VERSION "HNNBNNNYNNNNNNNNNNNNNNNNNNNNNNNNNNNNNNNNNN/4/%%%/4/'%**4NNN///"

NS_ :

BS_ :

BU_:  Airbag BAP_Tester ICAS1_Gateway ICAS1_KommunikationsServer LE1 LE2 Motor_BEV Schaltbetaetigung

BO_ 252 ESC_51: 48 ICAS1_Gateway
 SG_ ESC_51_CRC  : 0|8@1+ (1.000000,0.000000) [0.000000|255.000000] "" Motor_BEV
 SG_ ESC_51_BZ  : 8|4@1+ (1.000000,0.000000) [0.000000|15.000000] "" Motor_BEV
 SG_ ESC_aktBr_Modus  : 12|2@1+ (1.000000,0.000000) [0.000000|3.000000] "" Vector__XXX
 SG_ ESC_Blending_Solldruck  : 14|10@1+ (0.250000,0.000000) [0.000000|250.000000] "Unit_Bar" Vector__XXX
 SG_ ESC_aktBr_Volumenstrom  : 24|16@1+ (0.007812,-252.000000) [-252.000000|252.000000] "Unit_MilliLiterPerSec" Vector__XXX
 SG_ ESC_EBKV_Kraftblending_Modus  : 40|2@1+ (1.000000,0.000000) [0.000000|3.000000] "" Vector__XXX
 SG_ ESC_Bremsdruck_Modell  : 42|10@1+ (0.250000,0.000000) [0.000000|250.000000] "Unit_Bar" Motor_BEV
 SG_ ESC_Bremsdruck_02  : 52|10@1+ (0.300000,-30.000000) [-30.000000|276.600000] "Unit_Bar" Vector__XXX
 SG_ ESC_QBit_Bremsdruck_02  : 62|1@1+ (1.000000,0.000000) [0.000000|1.000000] "" Vector__XXX
 SG_ ESP_HL_Radgeschw_02  : 64|16@1+ (0.007500,0.000000) [0.000000|491.490000] "Unit_KiloMeterPerHour" Airbag LE1 LE2 Motor_BEV
 SG_ ESP_HR_Radgeschw_02  : 80|16@1+ (0.007500,0.000000) [0.000000|491.490000] "Unit_KiloMeterPerHour" Airbag LE1 LE2 Motor_BEV
 SG_ ESP_VL_Radgeschw_02  : 96|16@1+ (0.007500,0.000000) [0.000000|491.490000] "Unit_KiloMeterPerHour" Airbag LE1 LE2 Motor_BEV
 SG_ ESP_VR_Radgeschw_02  : 112|16@1+ (0.007500,0.000000) [0.000000|491.490000] "Unit_KiloMeterPerHour" Airbag LE1 LE2 Motor_BEV
 SG_ ESP_FZR_uebersteuern  : 128|8@1+ (0.004000,0.000000) [0.000000|1.000000] "" Vector__XXX
 SG_ ESP_FZR_untersteuern  : 136|8@1+ (0.004000,0.000000) [0.000000|1.000000] "" Vector__XXX
 SG_ ESC_Anf_Mindestreku  : 144|1@1+ (1.000000,0.000000) [0.000000|1.000000] "" Motor_BEV
 SG_ ESC_GMV_aktiv  : 145|3@1+ (1.000000,0.000000) [0.000000|7.000000] "" Vector__XXX
 SG_ ESC_GMV_nicht_verfuegbar  : 148|1@1+ (1.000000,0.000000) [0.000000|1.000000] "" Vector__XXX
 SG_ ESC_Status_vRef_Stuetzeingriff  : 149|1@1+ (1.000000,0.000000) [0.000000|1.000000] "" Motor_BEV
 SG_ FDR_Allradverteilung_aktiv  : 150|1@1+ (1.000000,0.000000) [0.000000|1.000000] "" Vector__XXX
 SG_ FDR_Anf_Allradbetrieb  : 151|1@1+ (1.000000,0.000000) [0.000000|1.000000] "" Vector__XXX
 SG_ ESP_HL_Bremsmoment  : 152|8@1+ (20.000000,0.000000) [0.000000|5060.000000] "Unit_NewtoMeter" Motor_BEV
 SG_ ESP_HR_Bremsmoment  : 160|8@1+ (20.000000,0.000000) [0.000000|5060.000000] "Unit_NewtoMeter" Motor_BEV
 SG_ ESP_VR_Bremsmoment  : 168|8@1+ (40.000000,0.000000) [0.000000|10120.000000] "Unit_NewtoMeter" Motor_BEV
 SG_ ESP_VL_Bremsmoment  : 176|8@1+ (40.000000,0.000000) [0.000000|10120.000000] "Unit_NewtoMeter" Motor_BEV
 SG_ ESP_FDR_uebersteuern  : 184|8@1+ (0.004000,0.000000) [0.000000|1.000000] "" Motor_BEV
 SG_ ESP_FDR_untersteuern  : 192|8@1+ (0.004000,0.000000) [0.000000|1.000000] "" Motor_BEV
 SG_ TSMomBegrenzung  : 268|12@1+ (3.000000,-12279.000000) [-12279.000000|0.000000] "" Motor_BEV
 SG_ ESC_Allrad_Anteil_max_sek  : 280|9@1+ (0.200000,0.000000) [0.000000|100.000000] "Unit_PerCent" Motor_BEV
 SG_ ESC_Allrad_Anteil_min_sek  : 289|9@1+ (0.200000,0.000000) [0.000000|100.000000] "Unit_PerCent" Motor_BEV
 SG_ ESC_Status_Eingriff  : 298|2@1+ (1.000000,0.000000) [0.000000|3.000000] "" Motor_BEV
 SG_ ESC_Status_Eingriff_sek  : 300|2@1+ (1.000000,0.000000) [0.000000|3.000000] "" Motor_BEV
 SG_ ESC_MomRad_Eingriff  : 302|13@1+ (3.000000,-12279.000000) [-12279.000000|12279.000000] "Unit_None" Motor_BEV
 SG_ ESC_MomRad_Eingriff_sek  : 315|13@1+ (3.000000,-12279.000000) [-12279.000000|12279.000000] "Unit_None" Motor_BEV
 SG_ ESC_Achsdrehzahl_Max  : 328|14@1+ (0.400000,-800.000000) [-800.000000|5752.400000] "Unit_MinutInver" Motor_BEV
 SG_ ESC_Achsdrehzahl_Min  : 342|14@1+ (0.400000,-800.000000) [-800.000000|5752.400000] "Unit_MinutInver" Motor_BEV
 SG_ ESC_Achsdrehzahl_Max_sek  : 356|14@1+ (0.400000,-800.000000) [-800.000000|5752.400000] "Unit_MinutInver" Motor_BEV
 SG_ ESC_Achsdrehzahl_Min_sek  : 370|14@1+ (0.400000,-800.000000) [-800.000000|5752.400000] "Unit_MinutInver" Motor_BEV

BO_ 2463978647 ESC_52: 16 ICAS1_Gateway
 SG_ ESP_ACC_LDE  : 12|1@1+ (1.000000,0.000000) [0.000000|1.000000] "" Vector__XXX
 SG_ ESP_Allrad_Antrieb  : 13|1@1+ (1.000000,0.000000) [0.000000|1.000000] "" Vector__XXX
 SG_ ESP_Codierung_ADS  : 14|2@1+ (1.000000,0.000000) [0.000000|3.000000] "" Vector__XXX
 SG_ ESP_RTA_HL  : 16|8@1+ (0.048828,-6.201170) [-6.201170|6.152346] "Unit_PerCent" Motor_BEV
 SG_ ESP_RTA_HR  : 24|8@1+ (0.048828,-6.201170) [-6.201170|6.152346] "Unit_PerCent" Motor_BEV
 SG_ ESP_RTA_VR  : 32|8@1+ (0.048828,-6.201170) [-6.201170|6.152346] "Unit_PerCent" Motor_BEV
 SG_ OBD_Fehler_Radsensor_HL  : 40|4@1+ (1.000000,0.000000) [0.000000|15.000000] "" Motor_BEV
 SG_ OBD_Fehler_Radsensor_HR  : 44|4@1+ (1.000000,0.000000) [0.000000|15.000000] "" Motor_BEV
 SG_ OBD_Fehler_Radsensor_VL  : 48|4@1+ (1.000000,0.000000) [0.000000|15.000000] "" Motor_BEV
 SG_ OBD_Fehler_Radsensor_VR  : 52|4@1+ (1.000000,0.000000) [0.000000|15.000000] "" Motor_BEV
 SG_ ESP_Qualifizierung_Antriebsart  : 56|1@1+ (1.000000,0.000000) [0.000000|1.000000] "" Vector__XXX
 SG_ ESP_Offroad_Modus  : 57|1@1+ (1.000000,0.000000) [0.000000|1.000000] "" Vector__XXX
 SG_ ESP_MKB_ausloesbar  : 58|1@1+ (1.000000,0.000000) [0.000000|1.000000] "" Vector__XXX
 SG_ ESP_Stat_FallBack_eBKV  : 59|1@1+ (1.000000,0.000000) [0.000000|1.000000] "" Vector__XXX
 SG_ ESP_CM_Variante  : 60|1@1+ (1.000000,0.000000) [0.000000|1.000000] "" Vector__XXX
 SG_ ESP_OBD_Status  : 61|1@1+ (1.000000,0.000000) [0.000000|1.000000] "" Motor_BEV
 SG_ ESP_Rollenmodus_Deaktivieren  : 62|1@1+ (1.000000,0.000000) [0.000000|1.000000] "" Motor_BEV
 SG_ ESP_nachtr_Stopp_Anf  : 63|1@1+ (1.000000,0.000000) [0.000000|1.000000] "" Vector__XXX

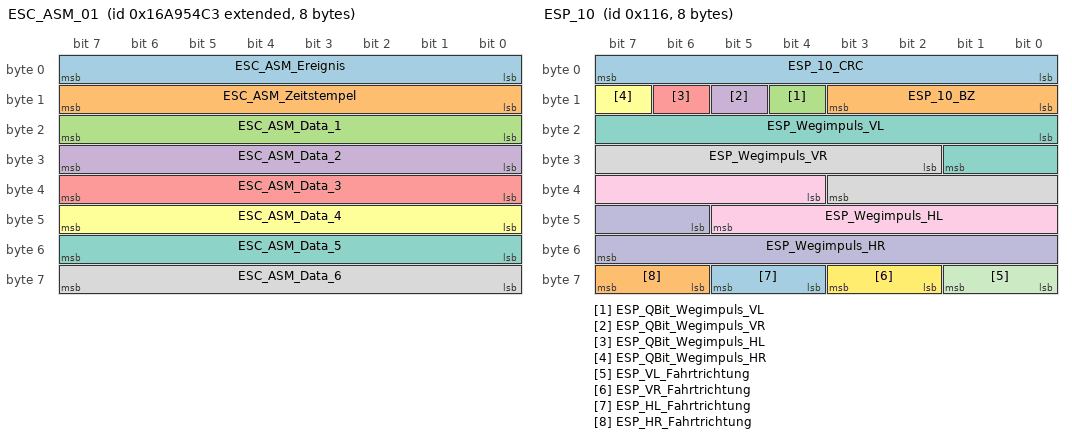
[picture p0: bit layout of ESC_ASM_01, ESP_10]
BO_ 2527679683 ESC_ASM_01: 8 ICAS1_Gateway
 SG_ ESC_ASM_Ereignis  : 0|8@1+ (1.000000,0.000000) [1.000000|254.000000] "Unit_None" Airbag
 SG_ ESC_ASM_Zeitstempel  : 8|8@1+ (0.080000,0.000000) [0.000000|20.320000] "Unit_Secon" Airbag
 SG_ ESC_ASM_Data_1  : 16|8@1+ (1.000000,0.000000) [0.000000|255.000000] "" Airbag
 SG_ ESC_ASM_Data_2  : 24|8@1+ (1.000000,0.000000) [0.000000|255.000000] "" Airbag
 SG_ ESC_ASM_Data_3  : 32|8@1+ (1.000000,0.000000) [0.000000|255.000000] "" Airbag
 SG_ ESC_ASM_Data_4  : 40|8@1+ (1.000000,0.000000) [0.000000|255.000000] "" Airbag
 SG_ ESC_ASM_Data_5  : 48|8@1+ (1.000000,0.000000) [0.000000|255.000000] "" Airbag
 SG_ ESC_ASM_Data_6  : 56|8@1+ (1.000000,0.000000) [0.000000|255.000000] "" Airbag

BO_ 278 ESP_10: 8 ICAS1_Gateway
 SG_ ESP_10_CRC  : 0|8@1+ (1.000000,0.000000) [0.000000|255.000000] "" Vector__XXX
 SG_ ESP_10_BZ  : 8|4@1+ (1.000000,0.000000) [0.000000|15.000000] "" Vector__XXX
 SG_ ESP_QBit_Wegimpuls_VL  : 12|1@1+ (1.000000,0.000000) [0.000000|1.000000] "" Motor_BEV
 SG_ ESP_QBit_Wegimpuls_VR  : 13|1@1+ (1.000000,0.000000) [0.000000|1.000000] "" Motor_BEV
 SG_ ESP_QBit_Wegimpuls_HL  : 14|1@1+ (1.000000,0.000000) [0.000000|1.000000] "" Motor_BEV
 SG_ ESP_QBit_Wegimpuls_HR  : 15|1@1+ (1.000000,0.000000) [0.000000|1.000000] "" Motor_BEV
 SG_ ESP_Wegimpuls_VL  : 16|10@1+ (1.000000,0.000000) [0.000000|1000.000000] "" Motor_BEV
 SG_ ESP_Wegimpuls_VR  : 26|10@1+ (1.000000,0.000000) [0.000000|1000.000000] "" Motor_BEV
 SG_ ESP_Wegimpuls_HL  : 36|10@1+ (1.000000,0.000000) [0.000000|1000.000000] "" Motor_BEV
 SG_ ESP_Wegimpuls_HR  : 46|10@1+ (1.000000,0.000000) [0.000000|1000.000000] "" Motor_BEV
 SG_ ESP_VL_Fahrtrichtung  : 56|2@1+ (1.000000,0.000000) [0.000000|3.000000] "" Motor_BEV
 SG_ ESP_VR_Fahrtrichtung  : 58|2@1+ (1.000000,0.000000) [0.000000|3.000000] "" Motor_BEV
 SG_ ESP_HL_Fahrtrichtung  : 60|2@1+ (1.000000,0.000000) [0.000000|3.000000] "" Motor_BEV
 SG_ ESP_HR_Fahrtrichtung  : 62|2@1+ (1.000000,0.000000) [0.000000|3.000000] "" Motor_BEV

BO_ 1629 ESP_20: 8 ICAS1_Gateway
 SG_ ESP_20_CRC  : 0|8@1+ (1.000000,0.000000) [0.000000|255.000000] "" Vector__XXX
 SG_ ESP_20_BZ  : 8|4@1+ (1.000000,0.000000) [0.000000|15.000000] "" Vector__XXX
 SG_ BR_Systemart  : 12|2@1+ (1.000000,0.000000) [0.000000|3.000000] "" Vector__XXX
 SG_ ESP_SpannungsAnf_02  : 14|2@1+ (1.000000,0.000000) [0.000000|3.000000] "" Vector__XXX
 SG_ ESP_Zaehnezahl  : 16|8@1+ (1.000000,0.000000) [0.000000|255.000000] "" Vector__XXX
 SG_ ESP_Charisma_FahrPr  : 24|4@1+ (1.000000,0.000000) [0.000000|15.000000] "" Vector__XXX
 SG_ ESP_Charisma_Status  : 28|2@1+ (1.000000,0.000000) [0.000000|3.000000] "" Vector__XXX
 SG_ ESP_Wiederstart_Anz_01  : 30|1@1+ (1.000000,0.000000) [0.000000|1.000000] "" Vector__XXX
 SG_ ESP_Wiederstart_Anz_02  : 31|1@1+ (1.000000,0.000000) [0.000000|1.000000] "" Vector__XXX
 SG_ ESP_Wiederstart_Anz_03  : 32|1@1+ (1.000000,0.000000) [0.000000|1.000000] "" Vector__XXX
 SG_ ESP_Wiederstart_Anz_04  : 33|1@1+ (1.000000,0.000000) [0.000000|1.000000] "" Vector__XXX
 SG_ ESP_Stoppverbot_Anz_01  : 34|1@1+ (1.000000,0.000000) [0.000000|1.000000] "" Vector__XXX
 SG_ ESP_Stoppverbot_Anz_02  : 35|1@1+ (1.000000,0.000000) [0.000000|1.000000] "" Vector__XXX
 SG_ ESP_Stoppverbot_Anz_03  : 36|1@1+ (1.000000,0.000000) [0.000000|1.000000] "" Vector__XXX
 SG_ ESP_Stoppverbot_Anz_04  : 37|1@1+ (1.000000,0.000000) [0.000000|1.000000] "" Vector__XXX
 SG_ ESP_Stoppverbot_Anz_05  : 38|1@1+ (1.000000,0.000000) [0.000000|1.000000] "" Vector__XXX
 SG_ ESP_Stoppverbot_Anz_06  : 39|1@1+ (1.000000,0.000000) [0.000000|1.000000] "" Vector__XXX
 SG_ ESP_Stoppverbot_Anz_07  : 40|1@1+ (1.000000,0.000000) [0.000000|1.000000] "" Vector__XXX
 SG_ ESP_Stoppverbot_Anz_Std  : 41|1@1+ (1.000000,0.000000) [0.000000|1.000000] "" Vector__XXX
 SG_ ESP_Dachrelingsensor  : 42|2@1+ (1.000000,0.000000) [0.000000|3.000000] "" Vector__XXX
 SG_ ESP_Stoppverbot_Anz_08  : 44|1@1+ (1.000000,0.000000) [0.000000|1.000000] "" Vector__XXX
 SG_ HDC_Charisma_FahrPr  : 45|4@1+ (1.000000,0.000000) [0.000000|15.000000] "" Vector__XXX
 SG_ HDC_Charisma_Status  : 49|2@1+ (1.000000,0.000000) [0.000000|3.000000] "" Vector__XXX
 SG_ BR_QBit_Reifenumfang  : 51|1@1+ (1.000000,0.000000) [0.000000|1.000000] "" LE1 LE2
 SG_ BR_Reifenumfang  : 52|12@1+ (1.000000,0.000000) [0.000000|4095.000000] "Unit_MilliMeter" LE1 LE2

BO_ 253 ESP_21: 8 ICAS1_Gateway
 SG_ ESP_21_CRC  : 0|8@1+ (1.000000,0.000000) [0.000000|255.000000] "" Airbag LE1 LE2 Motor_BEV
 SG_ ESP_21_BZ  : 8|4@1+ (1.000000,0.000000) [0.000000|15.000000] "" Airbag LE1 LE2 Motor_BEV
 SG_ BR_Eingriffsmoment  : 12|10@1+ (1.000000,-509.000000) [-509.000000|509.000000] "" Vector__XXX
 SG_ ESP_PLA_Bremseingriff  : 22|1@1+ (1.000000,0.000000) [0.000000|1.000000] "" Vector__XXX
 SG_ ESP_Diagnose  : 23|1@1+ (1.000000,0.000000) [0.000000|1.000000] "" Vector__XXX
 SG_ ESC_Reku_Freigabe  : 24|1@1+ (1.000000,0.000000) [0.000000|1.000000] "" Motor_BEV
 SG_ ESC_v_Signal_Qualifier_High_Low  : 25|3@1+ (1.000000,0.000000) [0.000000|7.000000] "" Airbag
 SG_ ESP_Vorsteuerung  : 28|1@1+ (1.000000,0.000000) [0.000000|1.000000] "" Motor_BEV
 SG_ ESP_AWV3_Brems_aktiv  : 29|1@1+ (1.000000,0.000000) [0.000000|1.000000] "" Vector__XXX
 SG_ OBD_Schlechtweg  : 30|1@1+ (1.000000,0.000000) [0.000000|1.000000] "" Vector__XXX
 SG_ OBD_QBit_Schlechtweg  : 31|1@1+ (1.000000,0.000000) [0.000000|1.000000] "" Vector__XXX
 SG_ ESP_v_Signal  : 32|16@1+ (0.010000,0.000000) [0.000000|655.320000] "Unit_KiloMeterPerHour" Airbag LE1 LE2 Motor_BEV
 SG_ ASR_Tastung_passiv  : 48|1@1+ (1.000000,0.000000) [0.000000|1.000000] "" Airbag Motor_BEV
 SG_ ESP_Tastung_passiv  : 49|1@1+ (1.000000,0.000000) [0.000000|1.000000] "" Airbag Motor_BEV
 SG_ ESP_Systemstatus  : 50|1@1+ (1.000000,0.000000) [0.000000|1.000000] "" Motor_BEV
 SG_ ASR_Schalteingriff  : 51|2@1+ (1.000000,0.000000) [0.000000|3.000000] "" Vector__XXX
 SG_ ESP_Haltebestaetigung  : 53|1@1+ (1.000000,0.000000) [0.000000|1.000000] "" Vector__XXX
 SG_ ESP_MKB_Abbruch_Geschw  : 54|1@1+ (1.000000,0.000000) [0.000000|1.000000] "" Vector__XXX
 SG_ ESP_QBit_v_Signal  : 55|1@1+ (1.000000,0.000000) [0.000000|1.000000] "" LE1 LE2 Motor_BEV
 SG_ ABS_Bremsung  : 56|1@1+ (1.000000,0.000000) [0.000000|1.000000] "" Airbag Motor_BEV
 SG_ ASR_Anf  : 57|1@1+ (1.000000,0.000000) [0.000000|1.000000] "" Vector__XXX
 SG_ MSR_Anf  : 58|1@1+ (1.000000,0.000000) [0.000000|1.000000] "" Vector__XXX
 SG_ EBV_Eingriff  : 59|1@1+ (1.000000,0.000000) [0.000000|1.000000] "" Vector__XXX
 SG_ EDS_Eingriff  : 60|1@1+ (1.000000,0.000000) [0.000000|1.000000] "" Motor_BEV
 SG_ ESP_Eingriff  : 61|1@1+ (1.000000,0.000000) [0.000000|1.000000] "" Airbag Motor_BEV
 SG_ ESP_ASP  : 62|1@1+ (1.000000,0.000000) [0.000000|1.000000] "" Vector__XXX
 SG_ ESP_Anhaltevorgang_ACC_aktiv  : 63|1@1+ (1.000000,0.000000) [0.000000|1.000000] "" Vector__XXX

BO_ 795 ESP_24: 8 ICAS1_Gateway
 SG_ ESP_24_CRC  : 0|8@1+ (1.000000,0.000000) [0.000000|255.000000] "" Vector__XXX
 SG_ ESP_24_BZ  : 8|4@1+ (1.000000,0.000000) [0.000000|15.000000] "" Vector__XXX
 SG_ ESP_Lampe  : 12|1@1+ (1.000000,0.000000) [0.000000|1.000000] "" Motor_BEV
 SG_ ABS_Lampe  : 13|1@1+ (1.000000,0.000000) [0.000000|1.000000] "" Vector__XXX
 SG_ BK_Lampe_02  : 14|2@1+ (1.000000,0.000000) [0.000000|3.000000] "" Vector__XXX
 SG_ TC_Lampe  : 16|1@1+ (1.000000,0.000000) [0.000000|1.000000] "" Vector__XXX
 SG_ ESP_m_Raddrehz  : 17|15@1+ (0.002000,0.000000) [0.000000|65.278000] "Unit_Hertz" Vector__XXX
 SG_ ESP_Textanzeigen_03  : 32|5@1+ (1.000000,0.000000) [0.000000|31.000000] "" Vector__XXX
 SG_ ESP_Meldungen  : 37|3@1+ (1.000000,0.000000) [0.000000|7.000000] "" Vector__XXX
 SG_ ESP_Wegimp_VA  : 40|11@1+ (1.000000,0.000000) [0.000000|2047.000000] "" Vector__XXX
 SG_ ESP_Fehlerstatus_Wegimp  : 51|1@1+ (1.000000,0.000000) [0.000000|1.000000] "" Vector__XXX
 SG_ ESP_Wegimp_Ueberlauf  : 52|1@1+ (1.000000,0.000000) [0.000000|1.000000] "" Vector__XXX
 SG_ ESP_QBit_Wegimp_VA  : 53|1@1+ (1.000000,0.000000) [0.000000|1.000000] "" Vector__XXX
 SG_ ESP_HDC_FktLampe  : 54|1@1+ (1.000000,0.000000) [0.000000|1.000000] "" Vector__XXX
 SG_ ESP_Off_Lampe  : 55|1@1+ (1.000000,0.000000) [0.000000|1.000000] "" Airbag
 SG_ ESP_HDC_Regelgeschw  : 56|7@1+ (0.320000,0.000000) [0.320000|39.680000] "Unit_KiloMeterPerHour" Vector__XXX
 SG_ ESP_BKV_Warnung  : 63|1@1+ (1.000000,0.000000) [0.000000|1.000000] "" Vector__XXX

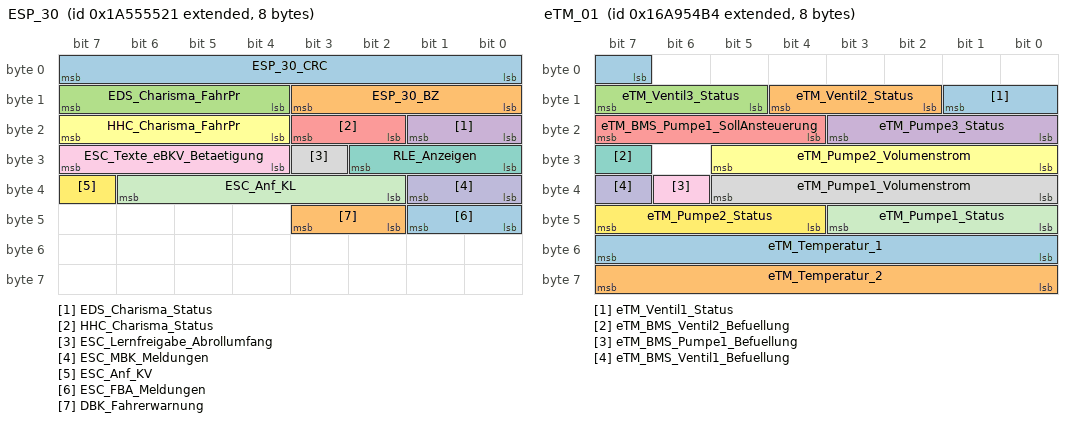
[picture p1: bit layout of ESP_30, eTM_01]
BO_ 2589283617 ESP_30: 8 ICAS1_Gateway
 SG_ ESP_30_CRC  : 0|8@1+ (1.000000,0.000000) [0.000000|255.000000] "" Vector__XXX
 SG_ ESP_30_BZ  : 8|4@1+ (1.000000,0.000000) [0.000000|15.000000] "" Vector__XXX
 SG_ EDS_Charisma_FahrPr  : 12|4@1+ (1.000000,0.000000) [0.000000|15.000000] "" Vector__XXX
 SG_ EDS_Charisma_Status  : 16|2@1+ (1.000000,0.000000) [0.000000|3.000000] "" Vector__XXX
 SG_ HHC_Charisma_Status  : 18|2@1+ (1.000000,0.000000) [0.000000|3.000000] "" Vector__XXX
 SG_ HHC_Charisma_FahrPr  : 20|4@1+ (1.000000,0.000000) [0.000000|15.000000] "" Vector__XXX
 SG_ RLE_Anzeigen  : 24|3@1+ (1.000000,0.000000) [0.000000|7.000000] "" Vector__XXX
 SG_ ESC_Lernfreigabe_Abrollumfang  : 27|1@1+ (1.000000,0.000000) [0.000000|1.000000] "" Vector__XXX
 SG_ ESC_Texte_eBKV_Betaetigung  : 28|4@1+ (1.000000,0.000000) [0.000000|15.000000] "" Vector__XXX
 SG_ ESC_MBK_Meldungen  : 32|2@1+ (1.000000,0.000000) [0.000000|3.000000] "" Vector__XXX
 SG_ ESC_Anf_KL  : 34|5@1+ (3.225806,0.000000) [0.000000|100.000000] "Unit_PerCent" Motor_BEV
 SG_ ESC_Anf_KV  : 39|1@1+ (1.000000,0.000000) [0.000000|1.000000] "" Motor_BEV
 SG_ ESC_FBA_Meldungen  : 40|2@1+ (1.000000,0.000000) [0.000000|3.000000] "" Vector__XXX
 SG_ DBK_Fahrerwarnung  : 42|2@1+ (1.000000,0.000000) [0.000000|3.000000] "" Vector__XXX

BO_ 2527679668 eTM_01: 8 Motor_BEV
 SG_ eTM_Ventil1_Status  : 7|3@1+ (1.000000,0.000000) [0.000000|7.000000] "" ICAS1_Gateway
 SG_ eTM_Ventil2_Status  : 10|3@1+ (1.000000,0.000000) [0.000000|7.000000] "" ICAS1_Gateway
 SG_ eTM_Ventil3_Status  : 13|3@1+ (1.000000,0.000000) [0.000000|7.000000] "" ICAS1_Gateway
 SG_ eTM_Pumpe3_Status  : 16|4@1+ (10.000000,0.000000) [0.000000|130.000000] "Unit_PerCent" ICAS1_Gateway
 SG_ eTM_BMS_Pumpe1_SollAnsteuerung  : 20|4@1+ (10.000000,0.000000) [0.000000|130.000000] "Unit_PerCent" ICAS1_Gateway
 SG_ eTM_Pumpe2_Volumenstrom  : 24|6@1+ (0.500000,0.000000) [0.000000|30.500000] "Unit_LiterPerMinut" ICAS1_Gateway LE1 LE2
 SG_ eTM_BMS_Ventil2_Befuellung  : 31|1@1+ (1.000000,0.000000) [0.000000|1.000000] "" ICAS1_Gateway
 SG_ eTM_Pumpe1_Volumenstrom  : 32|6@1+ (0.500000,0.000000) [0.000000|30.500000] "Unit_LiterPerMinut" ICAS1_Gateway LE1 LE2
 SG_ eTM_BMS_Pumpe1_Befuellung  : 38|1@1+ (1.000000,0.000000) [0.000000|1.000000] "" ICAS1_Gateway
 SG_ eTM_BMS_Ventil1_Befuellung  : 39|1@1+ (1.000000,0.000000) [0.000000|1.000000] "" ICAS1_Gateway
 SG_ eTM_Pumpe1_Status  : 40|4@1+ (10.000000,0.000000) [0.000000|130.000000] "Unit_PerCent" ICAS1_Gateway LE1 LE2
 SG_ eTM_Pumpe2_Status  : 44|4@1+ (10.000000,0.000000) [0.000000|130.000000] "Unit_PerCent" ICAS1_Gateway LE1 LE2
 SG_ eTM_Temperatur_1  : 48|8@1+ (0.750000,-40.000000) [-40.000000|149.750000] "Unit_DegreCelsi" ICAS1_Gateway LE1 LE2
 SG_ eTM_Temperatur_2  : 56|8@1+ (0.750000,-40.000000) [-40.000000|149.750000] "Unit_DegreCelsi" ICAS1_Gateway LE1 LE2

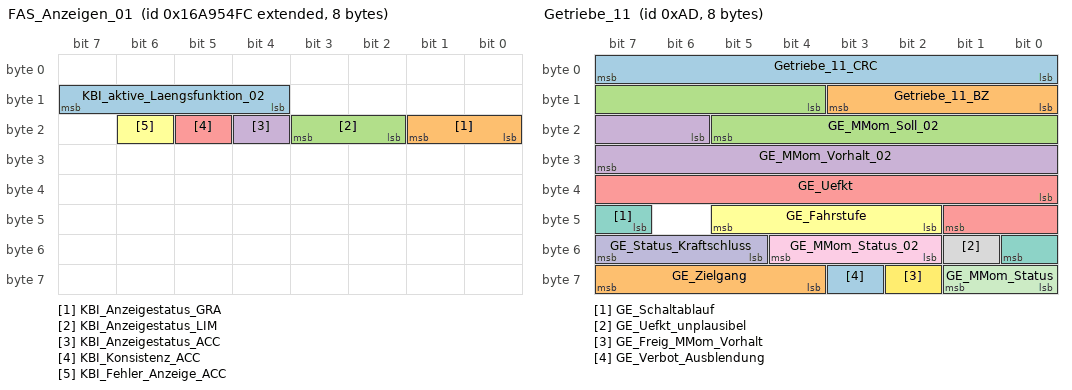
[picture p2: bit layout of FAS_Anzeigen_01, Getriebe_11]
BO_ 2527679740 FAS_Anzeigen_01: 8 ICAS1_KommunikationsServer
 SG_ KBI_aktive_Laengsfunktion_02  : 12|4@1+ (1.000000,0.000000) [0.000000|15.000000] "" Motor_BEV
 SG_ KBI_Anzeigestatus_GRA  : 16|2@1+ (1.000000,0.000000) [0.000000|3.000000] "" Motor_BEV
 SG_ KBI_Anzeigestatus_LIM  : 18|2@1+ (1.000000,0.000000) [0.000000|3.000000] "" Motor_BEV
 SG_ KBI_Anzeigestatus_ACC  : 20|1@1+ (1.000000,0.000000) [0.000000|1.000000] "" Vector__XXX
 SG_ KBI_Konsistenz_ACC  : 21|1@1+ (1.000000,0.000000) [0.000000|1.000000] "" Vector__XXX
 SG_ KBI_Fehler_Anzeige_ACC  : 22|1@1+ (1.000000,0.000000) [0.000000|1.000000] "" Vector__XXX

BO_ 2589283684 FoD_01: 8 ICAS1_Gateway
 SG_ GRA_FoD_Status  : 58|2@1+ (1.000000,0.000000) [0.000000|3.000000] "" Vector__XXX
 SG_ FoD_Transmission_Info  : 60|2@1+ (1.000000,0.000000) [0.000000|3.000000] "" Motor_BEV

BO_ 2549875574 FoD_MO_01_Req: 8 ICAS1_Gateway
 SG_ FoD_MO_01_Req_Data  : 0|64@1+ (1.000000,0.000000) [0.000000|18446744073709551616.000000] "" Motor_BEV

BO_ 2550006646 FoD_MO_01_Resp: 8 Motor_BEV
 SG_ FoD_MO_01_Resp_Data  : 0|64@1+ (1.000000,0.000000) [0.000000|18446744073709551616.000000] "" ICAS1_Gateway

BO_ 987 Gateway_72: 8 ICAS1_Gateway
 SG_ BCM_01_alt  : 0|1@1+ (1.000000,0.000000) [0.000000|1.000000] "" Airbag
 SG_ SMLS_01_alt  : 1|1@1+ (1.000000,0.000000) [0.000000|1.000000] "" Vector__XXX
 SG_ ZV_02_alt  : 2|1@1+ (1.000000,0.000000) [0.000000|1.000000] "" Vector__XXX
 SG_ Wischer_01_alt  : 3|1@1+ (1.000000,0.000000) [0.000000|1.000000] "" Vector__XXX
 SG_ Anhaenger_01_alt  : 4|1@1+ (1.000000,0.000000) [0.000000|1.000000] "" Airbag
 SG_ Klima_Sensor_02_alt  : 5|1@1+ (1.000000,0.000000) [0.000000|1.000000] "" Vector__XXX
 SG_ Verdeck_01_alt  : 6|1@1+ (1.000000,0.000000) [0.000000|1.000000] "" Vector__XXX
 SG_ Klima_11_alt  : 7|1@1+ (1.000000,0.000000) [0.000000|1.000000] "" Vector__XXX
 SG_ WFS_01_alt  : 8|1@1+ (1.000000,0.000000) [0.000000|1.000000] "" Vector__XXX
 SG_ Licht_Anf_01_alt  : 9|1@1+ (1.000000,0.000000) [0.000000|1.000000] "" Vector__XXX
 SG_ ZV_verriegelt_extern_soll  : 10|1@1+ (1.000000,0.000000) [0.000000|1.000000] "" Vector__XXX
 SG_ BH_Lichthupe  : 11|1@1+ (1.000000,0.000000) [0.000000|1.000000] "" Vector__XXX
 SG_ WFS_Klemmenfreigabe  : 12|1@1+ (1.000000,0.000000) [0.000000|1.000000] "" Vector__XXX
 SG_ ZV_Tankklappe_offen  : 13|1@1+ (1.000000,0.000000) [0.000000|1.000000] "" Vector__XXX
 SG_ AAG_Anhaenger_abgesteckt  : 14|1@1+ (1.000000,0.000000) [0.000000|1.000000] "" Vector__XXX
 SG_ BCM1_LDS_Stellung  : 15|3@1+ (1.000000,0.000000) [0.000000|7.000000] "" Vector__XXX
 SG_ VS_Verdeck_Anf  : 18|1@1+ (1.000000,0.000000) [0.000000|1.000000] "" Vector__XXX
 SG_ VS_VD_entriegelt  : 19|1@1+ (1.000000,0.000000) [0.000000|1.000000] "" Vector__XXX
 SG_ ZV_HFS_offen  : 20|1@1+ (1.000000,0.000000) [0.000000|1.000000] "" Vector__XXX
 SG_ ZV_HBFS_offen  : 21|1@1+ (1.000000,0.000000) [0.000000|1.000000] "" Vector__XXX
 SG_ VS_VD_offen_ver  : 22|1@1+ (1.000000,0.000000) [0.000000|1.000000] "" Vector__XXX
 SG_ VS_VD_zu_ver  : 23|1@1+ (1.000000,0.000000) [0.000000|1.000000] "" Vector__XXX
 SG_ ZV_BT_offen  : 24|1@1+ (1.000000,0.000000) [0.000000|1.000000] "" Vector__XXX
 SG_ BCM1_Rueckfahrlicht_Schalter  : 25|1@1+ (1.000000,0.000000) [0.000000|1.000000] "" Airbag Motor_BEV
 SG_ ZV_FT_offen  : 26|1@1+ (1.000000,0.000000) [0.000000|1.000000] "" Vector__XXX
 SG_ Wischer_vorne_aktiv  : 27|1@1+ (1.000000,0.000000) [0.000000|1.000000] "" Vector__XXX
 SG_ AAG_Anhaenger_erkannt  : 28|1@1+ (1.000000,0.000000) [0.000000|1.000000] "" Airbag
 SG_ BCM1_MH_Schalter  : 29|1@1+ (1.000000,0.000000) [0.000000|1.000000] "" Vector__XXX
 SG_ ZV_HD_offen  : 30|1@1+ (1.000000,0.000000) [0.000000|1.000000] "" Vector__XXX
 SG_ Waschen_vorne_aktiv  : 31|1@1+ (1.000000,0.000000) [0.000000|1.000000] "" Vector__XXX
 SG_ KL_Thermomanagement  : 32|2@1+ (1.000000,0.000000) [0.000000|3.000000] "" Vector__XXX
 SG_ WFS_Schluessel_Fahrberecht  : 34|4@1+ (1.000000,0.000000) [0.000000|15.000000] "" Vector__XXX
 SG_ BCM_Rueckfahrlicht_Anf  : 38|1@1+ (1.000000,0.000000) [0.000000|1.000000] "" Vector__XXX
 SG_ WWSs_01_alt  : 39|1@1+ (1.000000,0.000000) [0.000000|1.000000] "" Vector__XXX
 SG_ BCM_Tankklappensteller_Fehler  : 40|1@1+ (1.000000,0.000000) [0.000000|1.000000] "" Vector__XXX
 SG_ AAG_LED_aktiv  : 41|1@1+ (1.000000,0.000000) [0.000000|1.000000] "" Vector__XXX
 SG_ ZV_verriegelt_soll  : 42|2@1+ (1.000000,0.000000) [0.000000|3.000000] "" Vector__XXX
 SG_ ZV_Schluessel_Zugang  : 44|4@1+ (1.000000,0.000000) [0.000000|15.000000] "" Vector__XXX
 SG_ WFS_ID_Geb_autorisiert_in_Kl15  : 48|1@1+ (1.000000,0.000000) [0.000000|1.000000] "" Vector__XXX
 SG_ BH_Fernlicht  : 49|1@1+ (1.000000,0.000000) [0.000000|1.000000] "" Vector__XXX
 SG_ BH_Blinker_li  : 50|1@1+ (1.000000,0.000000) [0.000000|1.000000] "" Vector__XXX
 SG_ BH_Blinker_re  : 51|1@1+ (1.000000,0.000000) [0.000000|1.000000] "" Vector__XXX
 SG_ BCM1_OBD_FStatus_ATemp  : 52|4@1+ (1.000000,0.000000) [0.000000|15.000000] "" Vector__XXX
 SG_ BCM1_Aussen_Temp_ungef  : 56|8@1+ (0.500000,-50.000000) [-50.000000|76.000000] "Unit_DegreCelsi" Vector__XXX

BO_ 173 Getriebe_11: 8 Motor_BEV
 SG_ Getriebe_11_CRC  : 0|8@1+ (1.000000,0.000000) [0.000000|255.000000] "" ICAS1_Gateway
 SG_ Getriebe_11_BZ  : 8|4@1+ (1.000000,0.000000) [0.000000|15.000000] "" ICAS1_Gateway
 SG_ GE_MMom_Soll_02  : 12|10@1+ (1.000000,-509.000000) [-509.000000|509.000000] "" ICAS1_Gateway
 SG_ GE_MMom_Vorhalt_02  : 22|10@1+ (1.000000,-509.000000) [-509.000000|509.000000] "" ICAS1_Gateway
 SG_ GE_Uefkt  : 32|10@1+ (0.100000,0.000000) [0.000000|102.200000] "" ICAS1_Gateway
 SG_ GE_Fahrstufe  : 42|4@1+ (1.000000,0.000000) [0.000000|15.000000] "" ICAS1_Gateway
 SG_ GE_Schaltablauf  : 47|2@1+ (1.000000,0.000000) [0.000000|3.000000] "" ICAS1_Gateway
 SG_ GE_Uefkt_unplausibel  : 49|1@1+ (1.000000,0.000000) [0.000000|1.000000] "" ICAS1_Gateway
 SG_ GE_MMom_Status_02  : 50|3@1+ (1.000000,0.000000) [0.000000|7.000000] "" ICAS1_Gateway
 SG_ GE_Status_Kraftschluss  : 53|3@1+ (1.000000,0.000000) [0.000000|7.000000] "" ICAS1_Gateway
 SG_ GE_MMom_Status  : 56|2@1+ (1.000000,0.000000) [0.000000|3.000000] "" ICAS1_Gateway
 SG_ GE_Freig_MMom_Vorhalt  : 58|1@1+ (1.000000,0.000000) [0.000000|1.000000] "" ICAS1_Gateway
 SG_ GE_Verbot_Ausblendung  : 59|1@1+ (1.000000,0.000000) [0.000000|1.000000] "" ICAS1_Gateway
 SG_ GE_Zielgang  : 60|4@1+ (1.000000,0.000000) [0.000000|15.000000] "" ICAS1_Gateway

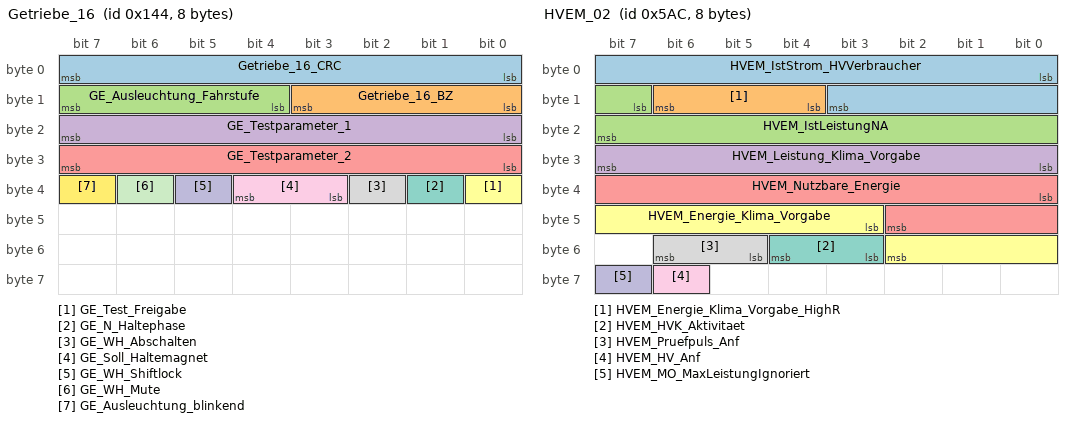
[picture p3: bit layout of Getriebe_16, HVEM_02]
BO_ 324 Getriebe_16: 8 Motor_BEV
 SG_ Getriebe_16_CRC  : 0|8@1+ (1.000000,0.000000) [0.000000|255.000000] "" ICAS1_Gateway Schaltbetaetigung
 SG_ Getriebe_16_BZ  : 8|4@1+ (1.000000,0.000000) [0.000000|15.000000] "" ICAS1_Gateway Schaltbetaetigung
 SG_ GE_Ausleuchtung_Fahrstufe  : 12|4@1+ (1.000000,0.000000) [0.000000|15.000000] "" ICAS1_Gateway Schaltbetaetigung
 SG_ GE_Testparameter_1  : 16|8@1+ (1.000000,0.000000) [0.000000|255.000000] "" ICAS1_Gateway Schaltbetaetigung
 SG_ GE_Testparameter_2  : 24|8@1+ (1.000000,0.000000) [0.000000|255.000000] "" ICAS1_Gateway Schaltbetaetigung
 SG_ GE_Test_Freigabe  : 32|1@1+ (1.000000,0.000000) [0.000000|1.000000] "" ICAS1_Gateway Schaltbetaetigung
 SG_ GE_N_Haltephase  : 33|1@1+ (1.000000,0.000000) [0.000000|1.000000] "" ICAS1_Gateway Schaltbetaetigung
 SG_ GE_WH_Abschalten  : 34|1@1+ (1.000000,0.000000) [0.000000|1.000000] "" ICAS1_Gateway Schaltbetaetigung
 SG_ GE_Soll_Haltemagnet  : 35|2@1+ (1.000000,0.000000) [0.000000|3.000000] "" ICAS1_Gateway Schaltbetaetigung
 SG_ GE_WH_Shiftlock  : 37|1@1+ (1.000000,0.000000) [0.000000|1.000000] "" ICAS1_Gateway Schaltbetaetigung
 SG_ GE_WH_Mute  : 38|1@1+ (1.000000,0.000000) [0.000000|1.000000] "" ICAS1_Gateway Schaltbetaetigung
 SG_ GE_Ausleuchtung_blinkend  : 39|1@1+ (1.000000,0.000000) [0.000000|1.000000] "" ICAS1_Gateway Schaltbetaetigung

BO_ 299 GRA_ACC_01: 8 ICAS1_Gateway
 SG_ GRA_ACC_01_CRC  : 0|8@1+ (1.000000,0.000000) [0.000000|255.000000] "" Motor_BEV
 SG_ GRA_ACC_01_BZ  : 8|4@1+ (1.000000,0.000000) [0.000000|15.000000] "" Motor_BEV
 SG_ GRA_Hauptschalter  : 12|1@1+ (1.000000,0.000000) [0.000000|1.000000] "" Motor_BEV
 SG_ GRA_Abbrechen  : 13|1@1+ (1.000000,0.000000) [0.000000|1.000000] "" Motor_BEV
 SG_ GRA_Typ_Hauptschalter  : 14|1@1+ (1.000000,0.000000) [0.000000|1.000000] "" Motor_BEV
 SG_ GRA_Limiter  : 15|1@1+ (1.000000,0.000000) [0.000000|1.000000] "" Motor_BEV
 SG_ GRA_Tip_Setzen  : 16|1@1+ (1.000000,0.000000) [0.000000|1.000000] "" Motor_BEV
 SG_ GRA_Tip_Hoch  : 17|1@1+ (1.000000,0.000000) [0.000000|1.000000] "" Motor_BEV
 SG_ GRA_Tip_Runter  : 18|1@1+ (1.000000,0.000000) [0.000000|1.000000] "" Motor_BEV
 SG_ GRA_Tip_Wiederaufnahme  : 19|1@1+ (1.000000,0.000000) [0.000000|1.000000] "" Motor_BEV
 SG_ GRA_Verstellung_Zeitluecke  : 20|2@1+ (1.000000,0.000000) [0.000000|3.000000] "" Vector__XXX
 SG_ GRA_Codierung  : 22|2@1+ (1.000000,0.000000) [0.000000|3.000000] "" Motor_BEV
 SG_ GRA_Fehler  : 24|1@1+ (1.000000,0.000000) [0.000000|1.000000] "" Motor_BEV
 SG_ GRA_LIM_Taste_verfuegbar  : 25|1@1+ (1.000000,0.000000) [0.000000|1.000000] "" Motor_BEV
 SG_ GRA_Tip_Stufe_2  : 26|1@1+ (1.000000,0.000000) [0.000000|1.000000] "" Motor_BEV
 SG_ GRA_Typ_Bedienteil  : 27|3@1+ (1.000000,0.000000) [0.000000|7.000000] "" Motor_BEV
 SG_ GRA_TravelAssist  : 30|1@1+ (1.000000,0.000000) [0.000000|1.000000] "" Vector__XXX
 SG_ GRA_reserveByte4  : 31|1@1+ (1.000000,0.000000) [0.000000|1.000000] "" Vector__XXX
 SG_ GRA_reserveByte5  : 32|8@1+ (1.000000,0.000000) [0.000000|255.000000] "" Vector__XXX
 SG_ GRA_reserveByte6  : 40|8@1+ (1.000000,0.000000) [0.000000|255.000000] "" Vector__XXX
 SG_ GRA_reserveByte7  : 48|8@1+ (1.000000,0.000000) [0.000000|255.000000] "" Vector__XXX
 SG_ GRA_reserveByte8  : 56|8@1+ (1.000000,0.000000) [0.000000|255.000000] "" Vector__XXX

BO_ 1452 HVEM_02: 8 ICAS1_Gateway
 SG_ HVEM_IstStrom_HVVerbraucher  : 0|12@1+ (0.100000,-204.700000) [-204.700000|204.600000] "Unit_Amper" Vector__XXX
 SG_ HVEM_Energie_Klima_Vorgabe_HighR  : 12|3@1+ (10.000000,0.000000) [0.000000|50.000000] "Unit_WattHour" Vector__XXX
 SG_ HVEM_IstLeistungNA  : 15|9@1+ (50.000000,0.000000) [0.000000|25450.000000] "Unit_Watt" Motor_BEV
 SG_ HVEM_Leistung_Klima_Vorgabe  : 24|8@1+ (50.000000,0.000000) [0.000000|12650.000000] "Unit_Watt" Vector__XXX
 SG_ HVEM_Nutzbare_Energie  : 32|11@1+ (50.000000,0.000000) [0.000000|102200.000000] "Unit_WattHour" Vector__XXX
 SG_ HVEM_Energie_Klima_Vorgabe  : 43|8@1+ (50.000000,0.000000) [0.000000|12650.000000] "Unit_WattHour" Vector__XXX
 SG_ HVEM_HVK_Aktivitaet  : 51|2@1+ (1.000000,0.000000) [0.000000|3.000000] "" Motor_BEV
 SG_ HVEM_Pruefpuls_Anf  : 53|2@1+ (1.000000,0.000000) [0.000000|3.000000] "" Motor_BEV
 SG_ HVEM_HV_Anf  : 62|1@1+ (1.000000,0.000000) [0.000000|1.000000] "" Motor_BEV
 SG_ HVEM_MO_MaxLeistungIgnoriert  : 63|1@1+ (1.000000,0.000000) [0.000000|1.000000] "" Vector__XXX

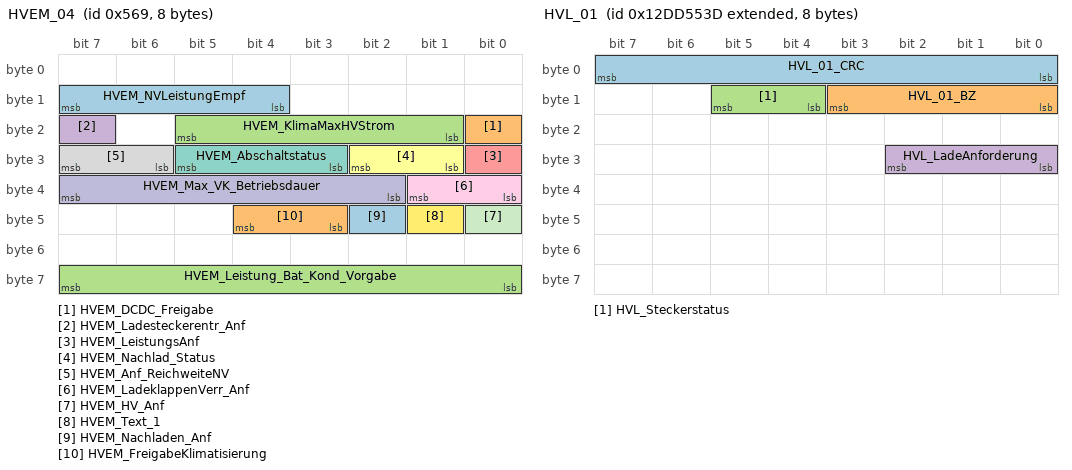
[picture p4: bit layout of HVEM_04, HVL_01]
BO_ 1385 HVEM_04: 8 ICAS1_Gateway
 SG_ HVEM_NVLeistungEmpf  : 12|4@1+ (100.000000,0.000000) [0.000000|1500.000000] "Unit_Watt" Vector__XXX
 SG_ HVEM_DCDC_Freigabe  : 16|1@1+ (1.000000,0.000000) [0.000000|1.000000] "" Motor_BEV
 SG_ HVEM_KlimaMaxHVStrom  : 17|5@1+ (1.000000,0.000000) [0.000000|31.000000] "Unit_Amper" Vector__XXX
 SG_ HVEM_Ladesteckerentr_Anf  : 23|1@1+ (1.000000,0.000000) [0.000000|1.000000] "" Vector__XXX
 SG_ HVEM_LeistungsAnf  : 24|1@1+ (1.000000,0.000000) [0.000000|1.000000] "" Vector__XXX
 SG_ HVEM_Nachlad_Status  : 25|2@1+ (1.000000,0.000000) [0.000000|3.000000] "" Vector__XXX
 SG_ HVEM_Abschaltstatus  : 27|3@1+ (1.000000,0.000000) [0.000000|7.000000] "" Vector__XXX
 SG_ HVEM_Anf_ReichweiteNV  : 30|2@1+ (1.000000,0.000000) [0.000000|3.000000] "" Vector__XXX
 SG_ HVEM_LadeklappenVerr_Anf  : 32|2@1+ (1.000000,0.000000) [0.000000|3.000000] "" Vector__XXX
 SG_ HVEM_Max_VK_Betriebsdauer  : 34|6@1+ (1.000000,0.000000) [0.000000|60.000000] "Unit_Minut" Vector__XXX
 SG_ HVEM_HV_Anf  : 40|1@1+ (1.000000,0.000000) [0.000000|1.000000] "" Vector__XXX
 SG_ HVEM_Text_1  : 41|1@1+ (1.000000,0.000000) [0.000000|1.000000] "" Vector__XXX
 SG_ HVEM_Nachladen_Anf  : 42|1@1+ (1.000000,0.000000) [0.000000|1.000000] "" Vector__XXX
 SG_ HVEM_FreigabeKlimatisierung  : 43|2@1+ (1.000000,0.000000) [0.000000|3.000000] "" Vector__XXX
 SG_ HVEM_Leistung_Bat_Kond_Vorgabe  : 56|8@1+ (50.000000,0.000000) [0.000000|12650.000000] "Unit_Watt" Vector__XXX

BO_ 1283 HVK_01: 8 Motor_BEV
 SG_ HVK_01_CRC  : 0|8@1+ (1.000000,0.000000) [0.000000|255.000000] "" ICAS1_Gateway LE1 LE2
 SG_ HVK_01_BZ  : 8|4@1+ (1.000000,0.000000) [0.000000|15.000000] "" ICAS1_Gateway LE1 LE2
 SG_ HVK_Istmodus_Anf  : 12|1@1+ (1.000000,0.000000) [0.000000|1.000000] "" ICAS1_Gateway
 SG_ HVK_TN1_Sollmodus  : 13|2@1+ (1.000000,0.000000) [0.000000|3.000000] "" ICAS1_Gateway
 SG_ HVK_Vorladung_aktiv  : 15|1@1+ (1.000000,0.000000) [0.000000|1.000000] "" ICAS1_Gateway
 SG_ HVK_BMS_Sollmodus  : 24|3@1+ (1.000000,0.000000) [0.000000|7.000000] "" ICAS1_Gateway
 SG_ HVK_DCDC_Sollmodus  : 27|3@1+ (1.000000,0.000000) [0.000000|7.000000] "" ICAS1_Gateway
 SG_ HVK_EKK_Sollmodus  : 30|3@1+ (1.000000,0.000000) [0.000000|7.000000] "" ICAS1_Gateway
 SG_ HVK_HVPTC_Sollmodus  : 33|3@1+ (1.000000,0.000000) [0.000000|7.000000] "" ICAS1_Gateway
 SG_ HVK_HVLM_Sollmodus  : 36|3@1+ (1.000000,0.000000) [0.000000|7.000000] "" ICAS1_Gateway
 SG_ HVK_HV_Netz_Warnungen  : 39|2@1+ (1.000000,0.000000) [0.000000|3.000000] "" ICAS1_Gateway ICAS1_KommunikationsServer
 SG_ HV_Bordnetz_aktiv  : 41|1@1+ (1.000000,0.000000) [0.000000|1.000000] "" ICAS1_Gateway LE1 LE2
 SG_ HV_Bordnetz_Fehler  : 42|1@1+ (1.000000,0.000000) [0.000000|1.000000] "" ICAS1_Gateway
 SG_ HVK_Gesamtst_Spgfreiheit  : 43|2@1+ (1.000000,0.000000) [0.000000|3.000000] "" ICAS1_Gateway ICAS1_KommunikationsServer
 SG_ HVK_AktiveEntladung_Anf  : 45|1@1+ (1.000000,0.000000) [0.000000|1.000000] "" ICAS1_Gateway LE1 LE2
 SG_ HVK_HVEM_Freigabe  : 46|2@1+ (1.000000,0.000000) [0.000000|3.000000] "" ICAS1_Gateway
 SG_ HVK_Notentladung_Anf  : 48|2@1+ (1.000000,0.000000) [0.000000|3.000000] "" ICAS1_Gateway LE1 LE2
 SG_ HVK_Iso_Messung_Start  : 50|3@1+ (1.000000,0.000000) [0.000000|7.000000] "" ICAS1_Gateway
 SG_ HVK_Ladebereit  : 53|3@1+ (1.000000,0.000000) [0.000000|7.000000] "" ICAS1_Gateway
 SG_ HVK_PPulsFreigabe  : 56|2@1+ (1.000000,0.000000) [0.000000|3.000000] "" ICAS1_Gateway

BO_ 2463978813 HVL_01: 8 ICAS1_Gateway
 SG_ HVL_01_CRC  : 0|8@1+ (1.000000,0.000000) [0.000000|255.000000] "" Motor_BEV
 SG_ HVL_01_BZ  : 8|4@1+ (1.000000,0.000000) [0.000000|15.000000] "" Motor_BEV
 SG_ HVL_Steckerstatus  : 12|2@1+ (1.000000,0.000000) [0.000000|3.000000] "" Motor_BEV
 SG_ HVL_LadeAnforderung  : 24|3@1+ (1.000000,0.000000) [0.000000|7.000000] "" Motor_BEV

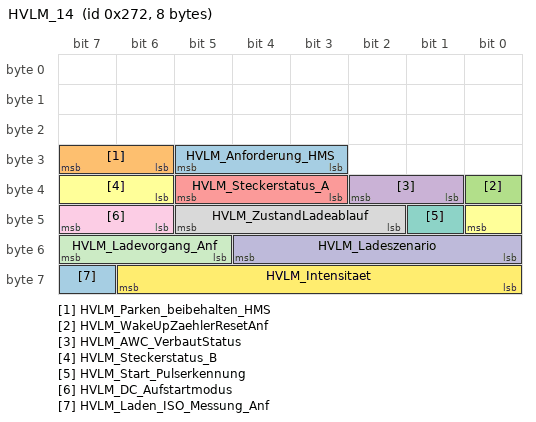
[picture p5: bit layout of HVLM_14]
BO_ 626 HVLM_14: 8 ICAS1_Gateway
 SG_ HVLM_Anforderung_HMS  : 27|3@1+ (1.000000,0.000000) [0.000000|7.000000] "" Vector__XXX
 SG_ HVLM_Parken_beibehalten_HMS  : 30|2@1+ (1.000000,0.000000) [0.000000|3.000000] "" Vector__XXX
 SG_ HVLM_WakeUpZaehlerResetAnf  : 32|1@1+ (1.000000,0.000000) [0.000000|1.000000] "" Vector__XXX
 SG_ HVLM_AWC_VerbautStatus  : 33|2@1+ (1.000000,0.000000) [0.000000|3.000000] "" Motor_BEV
 SG_ HVLM_Steckerstatus_A  : 35|3@1+ (1.000000,0.000000) [0.000000|7.000000] "" Motor_BEV
 SG_ HVLM_Steckerstatus_B  : 38|3@1+ (1.000000,0.000000) [0.000000|7.000000] "" Vector__XXX
 SG_ HVLM_Start_Pulserkennung  : 41|1@1+ (1.000000,0.000000) [0.000000|1.000000] "" Vector__XXX
 SG_ HVLM_ZustandLadeablauf  : 42|4@1+ (1.000000,0.000000) [0.000000|15.000000] "" Motor_BEV
 SG_ HVLM_DC_Aufstartmodus  : 46|2@1+ (1.000000,0.000000) [0.000000|3.000000] "" Motor_BEV
 SG_ HVLM_Ladeszenario  : 48|5@1+ (1.000000,0.000000) [0.000000|31.000000] "" Vector__XXX
 SG_ HVLM_Ladevorgang_Anf  : 53|3@1+ (1.000000,0.000000) [0.000000|7.000000] "" Motor_BEV
 SG_ HVLM_Intensitaet  : 56|7@1+ (1.000000,0.000000) [0.000000|100.000000] "Unit_PerCent" Vector__XXX
 SG_ HVLM_Laden_ISO_Messung_Anf  : 63|1@1+ (1.000000,0.000000) [0.000000|1.000000] "" Motor_BEV

BO_ 268 IMMO_CORD_01: 8 Motor_BEV
 SG_ ImoCord_Auth_Aufforderung_WFS  : 63|1@1+ (1.000000,0.000000) [0.000000|1.000000] "" LE1 LE2

BO_ 23 IMMO_MSG3_Antwort: 8 ICAS1_Gateway
 SG_ WFS_IMMO_MSG3_CRC  : 0|32@1+ (1.000000,0.000000) [0.000000|4294967295.000000] "" LE2
 SG_ WFS_IMMO_MSG3_Status  : 56|8@1+ (1.000000,0.000000) [0.000000|255.000000] "" LE2

BO_ 25 IMMO_MSG4_Antwort: 8 ICAS1_Gateway
 SG_ WFS_IMMO_MSG4_CRC  : 0|32@1+ (1.000000,0.000000) [0.000000|4294967295.000000] "" LE1
 SG_ WFS_IMMO_MSG4_Status  : 56|8@1+ (1.000000,0.000000) [0.000000|255.000000] "" LE1

CM_ BO_ 1629 "neuimMQB";
CM_ BO_ 253 "NeueMomenteimMQB
Struktur ab MQB mit CRC8 entstanden aus ESP_01";
CM_ BO_ 795 "neufürMQBwg.Absicherung
Entstanden aus ESP_04";
CM_ BO_ 987 "Komfort->Antrieb,Extended,Fahrwerk,Infotainment";
CM_ SG_ 252 ESC_51_CRC "FürMLB:
Berechnung siehe Lastenheft 'Kommunikationsabsicherung für FlexRay und CAN'
Ab MQB und MLBevo:
Berechnung siehe Lastenheft 'End-to-End Kommunikationsabsicherung'

Endwerte siehe Begleitdokument 'S-PDU Kennungsfolgen'";
CM_ SG_ 252 ESC_51_BZ "4bitBotschaftszähler,wirdmitjederSendebotschaftinkrementiert";
CM_ SG_ 252 ESC_aktBr_Modus "KontextdesSignalsESC_aktBr_Volumenstrom:
0: AktivBremsung per eBKV nicht aktiv
1: aktiver Druckaufbau per ESP-Pumpe: eBKV muss Volumen über HZ nachführen
2: Aktivbremsung per eBKV aktiv
3: eBKV bei Aktivbremsung im Runout: ESP-Pumpe muss zusätzlich";
CM_ SG_ 252 ESC_Blending_Solldruck "ZieldruckwährendRekuperation.DasSignalistspezifischaufbereitetundwirdfürdiePedakraftkompensationimeBKVgenutzt.

MQB/MQB2020: Wird nur von einem blendfähigen ESC unterstützt, wie es in mHEV und pHEV Fahrzeugen eingesetzt wird.";
CM_ SG_ 252 ESC_aktBr_Volumenstrom "VolumenstromvorgabefürAktivbremsungpereBKV,
Kontext des Volumenstroms wird im Signal ESC_aktBr_Modus übertragen";
CM_ SG_ 252 ESC_EBKV_Kraftblending_Modus "FreigabederPedalkraftkompensation(FunktiondeseBKV)

MQB/MQB2020: Wird nur von einem blendfähigen ESC unterstützt, wie es in mHEV und pHEV Fahrzeugen eingesetzt wird.";
CM_ SG_ 252 ESC_Bremsdruck_Modell "Virtueller,ausdemWert'EBKV_Stangenweg_Fahrerwunsch'berechneterHauptzylinderdruck.WährendeinerhydraulischenBremsungentsprichtdieserDrucknahezudem'ESC_Bremsdruck_02'.WährendeinerBremsungmitRekuperationisteseinberechneterWert,derd";
CM_ SG_ 252 ESC_Bremsdruck_02 "RohwertdesBremsdrucks
Für Fahrzeuge mit elektrischem Bremskraftverstärker gilt: Aus dem Signal ESC_Bremsdruck_02 lässt sich kein Fahrerbremswunsch ableiten. Das Signal bildet lediglich den hydraulischen Anteil der Fahrzeugverzögerung ab. Der Rohwert de";
CM_ SG_ 252 ESC_QBit_Bremsdruck_02 "QBitdesESC_Bremsdruck_02.GesetztbeiErsatzwert,InitoderFehler.";
CM_ SG_ 252 ESP_HL_Radgeschw_02 "Radgeschwindigkeithintenlinks";
CM_ SG_ 252 ESP_HR_Radgeschw_02 "Radgeschwindigkeithintenrechts";
CM_ SG_ 252 ESP_VL_Radgeschw_02 "Radgeschwindigkeitvornelinks";
CM_ SG_ 252 ESP_VR_Radgeschw_02 "Radgeschwindigkeitvornerechts";
CM_ SG_ 252 ESP_FZR_uebersteuern "Fahrzeugerkenntuebersteuern";
CM_ SG_ 252 ESP_FZR_untersteuern "Fahrzeugerkenntuntersteuern";
CM_ SG_ 252 ESC_Anf_Mindestreku "BeiWert==1solldurchdenAntriebeineimProjektdefinierteMindestrekuperationsleistungdesE-AntriebszurAnforderungdurchdasBremssystemschnellstmöglichfreigegebenwerden.DiesdientzurEntlastungderReibbremse.";
CM_ SG_ 252 ESC_GMV_aktiv "RueckmeldungGiermomentvorgabeaktiv";
CM_ SG_ 252 ESC_GMV_nicht_verfuegbar "RueckmeldungGiermomentvorgabenichtverfuegbar";
CM_ SG_ 252 ESC_Status_vRef_Stuetzeingriff "DasSignalqualifizierteineMomentenreduzierunganderHinterachsezurStützungderESCReferenzgeschwindigkeit.DieReduzierungerfolgtüberdieSignaleESC_MomRad_EingriffbzwESC_MomRad_Eingriff_sek";
CM_ SG_ 252 FDR_Allradverteilung_aktiv "AllradumverteilungausFDRaktivundvomMSGumzusetzen";
CM_ SG_ 252 FDR_Anf_Allradbetrieb "AnforderungdesFahrdynamikreglersanMSGzurAktivierungdesAllradbetriebs.";
CM_ SG_ 252 ESP_HL_Bremsmoment "BremsmomentHL
Ausgabe nach LAH: Ausgabe der internen Radbremsmomente / Radbremsdrücke / durch das ESP";
CM_ SG_ 252 ESP_HR_Bremsmoment "BremsmomentHR
Ausgabe nach LAH: Ausgabe der internen Radbremsmomente / Radbremsdrücke / durch das ESP";
CM_ SG_ 252 ESP_VR_Bremsmoment "BremsmomentVR
Ausgabe nach LAH: Ausgabe der internen Radbremsmomente / Radbremsdrücke / durch das ESP";
CM_ SG_ 252 ESP_VL_Bremsmoment "BremsmomentVL
Ausgabe nach LAH: Ausgabe der internen Radbremsmomente / Radbremsdrücke / durch das ESP";
CM_ SG_ 252 ESP_FDR_uebersteuern "ModularerFahrdynamikreglererkenntÜbersteuern.
Bei Integration modularer Fahrdynamikregler in ESC MEB: Verwendung durch eAllradfunktion in MSG.";
CM_ SG_ 252 ESP_FDR_untersteuern "ModularerFahrdynamikreglererkenntUntersteuern.
Bei Integration modularer Fahrdynamikregler in ESC MEB: Verwendung durch eAllradfunktion in MSG.";
CM_ SG_ 252 TSMomBegrenzung "InMLBevoFaktorinTS_Faktor_Radmomentebeachten!

Begrenzung des verzögernd wirkenden Antriebsstrangsollmomentenanteil auf Summenradebene";
CM_ SG_ 252 ESC_Allrad_Anteil_max_sek "MaximalerprozentualerAnteildersekundärenAntriebsachseamGesamtmoment-wirdsoweitdiesdurchdieLeistungsfähigkeitderAchsemöglichisteingehalten";
CM_ SG_ 252 ESC_Allrad_Anteil_min_sek "MinimalerprozentualerAnteildersekundärenAntriebsachseamGesamtmoment-wirdsoweitdiesdurchdieLeistungsfähigkeitderAchsemöglichisteingehalten";
CM_ SG_ 252 ESC_Status_Eingriff "DasSignalqualifiziert„ESC_MomRad_Eingriff“undgibtan,wiediesesSignalumzusetzenist";
CM_ SG_ 252 ESC_Status_Eingriff_sek "DasSignalqualifiziert„ESC_MomRad_Eingriff_sek“undgibtan,wiediesesSignalumzusetzenist";
CM_ SG_ 252 ESC_MomRad_Eingriff "Eingriffs-Momenten-AnforderungvomESCandasASGfürdieprimäreAchse;aufBezugsebene„MomentamRad;FaktorinTS_Faktor_Radmomentebeachten!";
CM_ SG_ 252 ESC_MomRad_Eingriff_sek "Eingriffs-Momenten-AnforderungvomESCandasASGfürdiesekundäreAchse;aufBezugsebene„MomentamRad;FaktorinTS_Faktor_Radmomentebeachten!SignalistnurrelevantfürmechanischgetrennteAchsantriebe(z.B.equattro)";
CM_ SG_ 252 ESC_Achsdrehzahl_Max "LimitAchsdrehzahlfürdiePrimärachse";
CM_ SG_ 252 ESC_Achsdrehzahl_Min "LimitAchsdrehzahlfürdiePrimärachse";
CM_ SG_ 252 ESC_Achsdrehzahl_Max_sek "LimitAchsdrehzahlfürdieSekundärachse";
CM_ SG_ 252 ESC_Achsdrehzahl_Min_sek "LimitAchsdrehzahlfürdieSekundärachse";
CM_ SG_ 2463978647 ESP_ACC_LDE "Verwendung/BedienungabFolgeprojekteD4,abernichtimD4selbst
Lebensdauerende für ACC-Bremsung erreicht";
CM_ SG_ 2463978647 ESP_Allrad_Antrieb "ImMQBwirddasSignalnichtunterstützt!";
CM_ SG_ 2463978647 ESP_Codierung_ADS "ESPgibtfürEmpfängerimFahrzeugaus,obADSverbaut/nichtverbautist.

Im MQB wird das Signal nicht unterstützt!
";
CM_ SG_ 2463978647 ESP_RTA_HL "PhysikalischerWertebereich+/-5%.DerReifentoleranzabgleichbeziehtsichaufdaslinkeVorderrad.

physikalischer Wert = ( (Hex-Wert - 0x7F) / 2048 )*100%

Im MQB wird das Signal nicht unterstützt!";
CM_ SG_ 2463978647 ESP_RTA_HR "PhysikalischerWertebereich+/-5%.DerReifentoleranzabgleichbeziehtsichaufdaslinkeVorderrad.

physikalischer Wert = ( (Hex-Wert - 0x7F) / 2048 )*100%

Im MQB wird das Signal nicht unterstützt!";
CM_ SG_ 2463978647 ESP_RTA_VR "PhysikalischerWertebereich+/-5%.DerReifentoleranzabgleichbeziehtsichaufdaslinkeVorderrad.

physikalischer Wert = ( (Hex-Wert - 0x7F) / 2048 )*100%

Im MQB wird das Signal nicht unterstützt!";
CM_ SG_ 2463978647 OBD_Fehler_Radsensor_HL "FürMotor-SG(gesetzlicheVorgabe)";
CM_ SG_ 2463978647 OBD_Fehler_Radsensor_HR "FürMotor-SG(gesetzlicheVorgabe)";
CM_ SG_ 2463978647 OBD_Fehler_Radsensor_VL "FürMotor-SG(gesetzlicheVorgabe)";
CM_ SG_ 2463978647 OBD_Fehler_Radsensor_VR "FürMotor-SG(gesetzlicheVorgabe)";
CM_ SG_ 2463978647 ESP_Qualifizierung_Antriebsart "SignalforBentleyBY83x:ESP_wheel_drive_selector

Bit qualifiziert für neue Projekte (ab D4 ff.) das Signal 'ESP_Quattro_Antrieb', d.h. ist 'ESP_Qualifizierung_Antriebsart'
auf 0x1 gesetzt, ändert sich die bisherige Bedeutung des Signals 'ESP_Quattro";
CM_ SG_ 2463978647 ESP_Offroad_Modus "NurVW526:BeiOffroad-FahrzeugenkannübereinenSchaltereinOffroadmodusgewähltwerden,dieserwirdhierangezeigt.BeiOffroadPlus-FahrzeugenwirdhierderOffroadmodusindirektdurchdasVerteilergetriebevorgegeben(ALR_Offroad=1)undeingespie";
CM_ SG_ 2463978647 ESP_MKB_ausloesbar "ESPhatFunktionMulti-Kollisions-Bremsungfreigeschaltet";
CM_ SG_ 2463978647 ESP_Stat_FallBack_eBKV "DasSignalzeigtdemeBKVan,obseineRückfallebeneimESPverfügbarist.";
CM_ SG_ 2463978647 ESP_CM_Variante "SignalgibtanwelcheCM-Varianteunterstuetztwird.
";
CM_ SG_ 2463978647 ESP_OBD_Status "DiesesBitsteuertdieMIL-Lampean(MotorsteuergerätreichtdieseInfoanKombiweiter).";
CM_ SG_ 2463978647 ESP_Rollenmodus_Deaktivieren "ZwangzumAbbruchdesRollenmodusmitanschließenderESP-Vollfunktion.
MQB: Zwang zum Abbruch des Rollenmodus in allen Funktionsteilnehmern (Empfänger) mit anschließender ESP-Vollfunktion (Sender).
Signal wird vom ESP dauerhaft mit gültigen Werten bedat";
CM_ SG_ 2463978647 ESP_nachtr_Stopp_Anf "DiesesSignaldientdemMotoralsTrigger,dasseinnachträglicherMotorstoppeingeleitetwerdenkann,wennesdieBedingungendesStStKoordinatorsdieszulassen.";
CM_ SG_ 2527679683 ESC_ASM_Ereignis "DiesesSignaldefiniert,welcheFunktionundwelcheArtvonAktivitätdasSendenderBotschaftandenAssistenzsystemmonitorASMveranlassthat.";
CM_ SG_ 2527679683 ESC_ASM_Zeitstempel "DiesesSignalermöglichtdiezeitlicheZuordnungdervonmehrerenFunktionenaufdemESC-SGandenAssistenzsystemmonitorASMgesendetenStatusbotschaften";
CM_ SG_ 2527679683 ESC_ASM_Data_1 "DieseSignalwirdvonmehrerenFunktionenaufdemESC-SGgemäßderASM-DatendefinitionbefülltundandenAssistenzsystemmonitorASMgesendet";
CM_ SG_ 2527679683 ESC_ASM_Data_2 "DieseSignalwirdvonmehrerenFunktionenaufdemESC-SGgemäßderASM-DatendefinitionbefülltundandenAssistenzsystemmonitorASMgesendet";
CM_ SG_ 2527679683 ESC_ASM_Data_3 "DieseSignalwirdvonmehrerenFunktionenaufdemESC-SGgemäßderASM-DatendefinitionbefülltundandenAssistenzsystemmonitorASMgesendet";
CM_ SG_ 2527679683 ESC_ASM_Data_4 "DieseSignalwirdvonmehrerenFunktionenaufdemESC-SGgemäßderASM-DatendefinitionbefülltundandenAssistenzsystemmonitorASMgesendet";
CM_ SG_ 2527679683 ESC_ASM_Data_5 "DieseSignalwirdvonmehrerenFunktionenaufdemESC-SGgemäßderASM-DatendefinitionbefülltundandenAssistenzsystemmonitorASMgesendet";
CM_ SG_ 2527679683 ESC_ASM_Data_6 "DieseSignalwirdvonmehrerenFunktionenaufdemESC-SGgemäßderASM-DatendefinitionbefülltundandenAssistenzsystemmonitorASMgesendet";
CM_ SG_ 278 ESP_10_CRC "FürMLB:
'Berechnung siehe Lastenheft 'Kommunikationsabsicherung für FlexRay und CAN''

Ab MQB und MLBevo:
'Berechnung siehe Lastenheft 'End-to-End Kommunikationsabsicherung''

Endwerte siehe Begleitdokument 'S-PDU Kennungsfolgen'

Wird im Projekt";
CM_ SG_ 278 ESP_10_BZ "Botschaftszähler

Wird im Projekt D4 und D4Hybrid nicht verwendet!  Wird im D4 PA verwendet";
CM_ SG_ 278 ESP_QBit_Wegimpuls_VL "QualifizierungsbitWegimpulszählerVL

Wird im Projekt D4 und D4Hybrid nicht verwendet!  Wird im D4 PA verwendet";
CM_ SG_ 278 ESP_QBit_Wegimpuls_VR "QualifizierungsbitWegimpulszählerVR

Wird im Projekt D4 und D4Hybrid nicht verwendet!  Wird im D4 PA verwendet";
CM_ SG_ 278 ESP_QBit_Wegimpuls_HL "QualifizierungsbitWegimpulszählerHL

Wird im Projekt D4 und D4Hybrid nicht verwendet!  Wird im D4 PA verwendet";
CM_ SG_ 278 ESP_QBit_Wegimpuls_HR "QualifizierungsbitWegimpulszählerHR

Wird im Projekt D4 und D4Hybrid nicht verwendet!  Wird im D4 PA verwendet";
CM_ SG_ 278 ESP_Wegimpuls_VL "WegimpulszählerVL.
Anzahl der Wegimpulse Vorderrad links (steigende und fallende Flanke)
Zähler läuft grundsätzlich vorwärts, auch bei Rückwärtsfahrt.
Nach SG-Reset ist immer, ohne Ausnahme, 1mal der Init Wert 1021 zu senden.

Wird im Projekt D4 und";
CM_ SG_ 278 ESP_Wegimpuls_VR "WegimpulszählerVR.
Anzahl der Wegimpulse Vorderrad rechts (steigende und fallende Flanke)
Zähler läuft grundsätzlich vorwärts, auch bei Rückwärtsfahrt.
Nach SG-Reset ist immer, ohne Ausnahme, 1mal der Init Wert 1021 zu senden.

Wird im Projekt D4 un";
CM_ SG_ 278 ESP_Wegimpuls_HL "WegimpulszählerHL.
Anzahl der Wegimpulse Hinterrad links (steigende und fallende Flanke)
Zähler läuft grundsätzlich vorwärts, auch bei Rückwärtsfahrt.
Nach SG-Reset ist immer, ohne Ausnahme, 1mal der Init Wert 1021 zu senden.

Wird im Projekt D4 und";
CM_ SG_ 278 ESP_Wegimpuls_HR "WegimpulszählerHR.
Anzahl der Wegimpulse Hinterrad rechts (steigende und fallende Flanke)
Zähler läuft grundsätzlich vorwärts, auch bei Rückwärtsfahrt.
Nach SG-Reset ist immer, ohne Ausnahme, 1mal der Init Wert 1021 zu senden.

Wird im Projekt D4 un";
CM_ SG_ 278 ESP_VL_Fahrtrichtung "DrehrichtungRadVL

Weiterführende Informationen im Lastenheft spezifiziert und in der entsprechenden Fachabteilung zu erfragen.

Wird im Projekt D4 und D4Hybrid nicht verwendet!  Wird im D4 PA verwendet";
CM_ SG_ 278 ESP_VR_Fahrtrichtung "DrehrichtungRadVR

Weiterführende Informationen im Lastenheft spezifiziert und in der entsprechenden Fachabteilung zu erfragen.

Wird im Projekt D4 und D4Hybrid nicht verwendet!  Wird im D4 PA verwendet";
CM_ SG_ 278 ESP_HL_Fahrtrichtung "DrehrichtungRadHL

Weiterführende Informationen im Lastenheft spezifiziert und in der entsprechenden Fachabteilung zu erfragen.

Wird im Projekt D4 und D4Hybrid nicht verwendet!  Wird im D4 PA verwendet";
CM_ SG_ 278 ESP_HR_Fahrtrichtung "DrehrichtungRadHR

Weiterführende Informationen im Lastenheft spezifiziert und in der entsprechenden Fachabteilung zu erfragen.

Wird im Projekt D4 und D4Hybrid nicht verwendet!  Wird im D4 PA verwendet";
CM_ SG_ 1629 ESP_20_CRC "FürMLB:
'Berechnung siehe Lastenheft 'Kommunikationsabsicherung für FlexRay und CAN''

Ab MQB und MLBevo:
'Berechnung siehe Lastenheft 'End-to-End Kommunikationsabsicherung''

Endwerte siehe Begleitdokument 'S-PDU Kennungsfolgen'";
CM_ SG_ 1629 BR_Systemart "IdentifikationdesverbautenBremssystems

Dient dem Kombi zur Plausibilisierung";
CM_ SG_ 1629 ESP_SpannungsAnf_02 "ForderungdesESP-SG'szurSpannungsanhebung.";
CM_ SG_ 1629 ESP_Zaehnezahl "KonstanterWertderZähnezahldesverwendetenImpulsradeswirdausgegeben,jederEmpfängerderWegimpulsemussdieZähnezahleinlesen,umeinevolleUmdrehungdesRadeszuerkennen.

Weiterführende Informationen im Lastenheft spezifiziert und in der en";
CM_ SG_ 1629 ESP_Charisma_FahrPr "MLBevo:AktuellesFahrprogrammdesCharisma-Teilnehmers(sieheSystemlastenheftDriveSelect)
MQB: Istwert der Kennlinie (siehe Systemlastenheft MQB FPA)";
CM_ SG_ 1629 ESP_Charisma_Status "SystemstatusdesCharismateilnehmers

Wert 0x3 ist nur für Fahrzeuge ab MQB relevant";
CM_ SG_ 1629 ESP_Wiederstart_Anz_01 "DiesesSignalgibtdiedetaillierteBegründungfüreinenWiederstartvomBremsensteuergerätan.";
CM_ SG_ 1629 ESP_Wiederstart_Anz_02 "DiesesSignalgibtdiedetaillierteBegründungfüreinenWiederstartvomBremsensteuergerätan.";
CM_ SG_ 1629 ESP_Wiederstart_Anz_03 "DiesesSignalgibtdiedetaillierteBegründungfüreinenWiederstartvomBremsensteuergerätan.";
CM_ SG_ 1629 ESP_Wiederstart_Anz_04 "DiesesSignalgibtdiedetaillierteBegründungfüreinenWiederstartvomBremsensteuergerätan.";
CM_ SG_ 1629 ESP_Stoppverbot_Anz_01 "DiesesSignalgibtdiedetaillierteBegründungfüreinStoppverbotvomBremsensteuergerätan.";
CM_ SG_ 1629 ESP_Stoppverbot_Anz_02 "DiesesSignalgibtdiedetaillierteBegründungfüreinStoppverbotvomBremsensteuergerätan.";
CM_ SG_ 1629 ESP_Stoppverbot_Anz_03 "DiesesSignalgibtdiedetaillierteBegründungfüreinStoppverbotvomBremsensteuergerätan.";
CM_ SG_ 1629 ESP_Stoppverbot_Anz_04 "DiesesSignalgibtdiedetaillierteBegründungfüreinStoppverbotvomBremsensteuergerätan.";
CM_ SG_ 1629 ESP_Stoppverbot_Anz_05 "DiesesSignalgibtdiedetaillierteBegründungfüreinStoppverbotvomBremsensteuergerätan.";
CM_ SG_ 1629 ESP_Stoppverbot_Anz_06 "DiesesSignalgibtdiedetaillierteBegründungfüreinStoppverbotvomBremsensteuergerätan.";
CM_ SG_ 1629 ESP_Stoppverbot_Anz_07 "DiesesSignalgibtdiedetaillierteBegründungfüreinStoppverbotvomBremsensteuergerätan.";
CM_ SG_ 1629 ESP_Stoppverbot_Anz_Std "DiesesSignalgibtdiedetaillierteBegründungfüreinStoppverbotvomBremsensteuergerätan.";
CM_ SG_ 1629 ESP_Dachrelingsensor "ErkennungaufVerbaudesDachrelingsensorsundDachquerträger.";
CM_ SG_ 1629 ESP_Stoppverbot_Anz_08 "DiesesSignalgibtdiedetaillierteBegründungfüreinStoppverbotvomBremsensteuergerätan.";
CM_ SG_ 1629 HDC_Charisma_FahrPr "MLBevo:AktuellesFahrprogrammdesCharisma-Teilnehmers(sieheSystemlastenheftDriveSelect)
MQB: Istwert der Kennlinie (siehe Systemlastenheft MQB FPA)";
CM_ SG_ 1629 HDC_Charisma_Status "SystemstatusdesCharismateilnehmers

Wert 0x3 ist nur für Fahrzeuge ab MQB relevant";
CM_ SG_ 1629 BR_QBit_Reifenumfang "GesetztbeiErsatzwert,InitoderFehler.";
CM_ SG_ 1629 BR_Reifenumfang "MittlererRadumfanggerechnetinMillimeter.
Von der Bremse plausibilisierter Wert (Kopie von KBI_Reifenumfang wenn dieser plausibel) oder Ersatzwert aus Bremse wenn KBI_Reifenumfang unplausibel. Bitte das QBit beachten!";
CM_ SG_ 253 ESP_21_CRC "FürMLB:
'Berechnung siehe Lastenheft 'Kommunikationsabsicherung für FlexRay und CAN''

Ab MQB und MLBevo:
'Berechnung siehe Lastenheft 'End-to-End Kommunikationsabsicherung''

Endwerte siehe Begleitdokument 'S-PDU Kennungsfolgen'";
CM_ SG_ 253 BR_Eingriffsmoment "EinheitenloserWert!FaktorinMO_Faktor_Momente_02inMotor_Code_01beachten!
Schnelle reduzierende (ASR) oder erhöhende (MSR) Momentanforderung an den Motor.";
CM_ SG_ 253 ESP_PLA_Bremseingriff "SignalisierungdesaktivenBremseingriffesdesESPaufgrundeinerBremsanforderungvomPLA.";
CM_ SG_ 253 ESP_Diagnose "MLB:NachDiagnoseendewirdeinSW-ResetausgelöstwelchereinenKommunikatiosausfallfürmax.150msverursacht.DiesistbeiSGmitverschärfterTimeoutüberwachung(nichtnachKonzern-LH)zubeachten.

MQB: Weiterführende Informationen im Lastenheft sp";
CM_ SG_ 253 ESC_Reku_Freigabe "MitdiesemBitwirddieRekuperationimMotorsteuergeräterlaubt.BeiAusfallESCwirdRekuperationnichtfreigegeben.

MQB/MQB2020: Wird nur von einem blendfähigen ESC unterstützt, wie es in mHEV und pHEV Fahrzeugen eingesetzt wird.";
CM_ SG_ 253 ESC_v_Signal_Qualifier_High_Low "DasQualifizerungssignalESC_v_Signal_Qualifier_High_LowgibteineInformationüberdieGütedervomBremsregelsystemausgegebenenGeschwindigkeitsinformation'mittlereGeschwindigkeit',wobeiVertrauensbereichefürdasausgegebeneGeschwindigkeitssignal";
CM_ SG_ 253 ESP_Vorsteuerung "zurUnterscheidungzwischenESP-VorsteuermaßnahmenundESP-Regeleingriffen";
CM_ SG_ 253 ESP_AWV3_Brems_aktiv "Teil-,Ziel-oderNotbremsungwirdimESPfürAWV3umgesetzt(dasMSGnutztdieseInfofürdenAbwurfderGRA-Regelung).";
CM_ SG_ 253 OBD_Schlechtweg "FürAusblendungderZündaussetzererkennungimMotorsteuergerät(Otto).Bitwirdgesetzt,wennRad-DrehbeschleunigungimESP>Grenzwertist.VorteilgegenüberRadgeschwindigkeiten,dassESPalle2msdynamischdieRad-Drehbeschleunigungerrechnetunddem";
CM_ SG_ 253 ESP_v_Signal "GeschwindigkeitssignalvomABS/ASRoderESP.MittelwertderangetriebenenRäder.
Bei MSR oder ABS Eingriffen wird die ABS-Referenzgeschwindigkeit für >= 200ms eingespiegelt (Zeit wird mit Aktiv-Flanke der Funktionsbits getriggert)

MQB: Bei Frontantrie";
CM_ SG_ 253 ASR_Tastung_passiv "ASRdeaktiviertoderSchwellengeändert(projektabhängig)
Weiterführende Informationen im Lastenheft spezifiziert und in der entsprechenden Fachabteilung zu erfragen.
";
CM_ SG_ 253 ESP_Tastung_passiv "ESPdeaktiviertoderSchwellengeändert(projektabhängig)
Weiterführende Informationen im Lastenheft spezifiziert und in der entsprechenden Fachabteilung zu erfragen.";
CM_ SG_ 253 ESP_Systemstatus "FehlerstehtfürStillegungESPmitFehlereintrag.

MLB: Flag wird bei Unterspannung im Stand bis einmalig 6km/h (AU48x) oder 10 km/h (AU641, AU57x) überschritten nicht gesetzt (Ausblendung Startvorgang)
Im AU64x, AU57x gilt ESP D4 Funktionsanforderung";
CM_ SG_ 253 ASR_Schalteingriff "WunschandasGetriebewährendeinerASRRegelung

MLB: Es wird nur 0x0 und 0x1 genutzt

";
CM_ SG_ 253 ESP_Haltebestaetigung "RückmeldungvomESP-SG,dassdasFahrzeugaufgrundeinerexternenBremsanforderung(z.B.ACC,PLA,ANB,o.ä.)abgebremstwurdeundimStillstandgehaltenwird.";
CM_ SG_ 253 ESP_MKB_Abbruch_Geschw "ImFalleeinerMultikollisionsbremsungteiltdasESPdenAbbruchderMKBaufgrundderunterenGeschwindigkeitsschwellemit.";
CM_ SG_ 253 ESP_QBit_v_Signal "GeschwindigkeitwirdvomABS/ASRoderESPausErsatzwertenerrechnet,wennBitgesetztist.GütedesSignalsistverändert.";
CM_ SG_ 253 ABS_Bremsung "Antiblockiersystem,BitzeigtauchDruckabbauan(z.B.ESPhatzuvielDruckaufgebautoderungebremsteRegelungaufBahnübergang)
Weiterführende Informationen im Lastenheft spezifiziert und in der entsprechenden Fachabteilung zu erfragen.";
CM_ SG_ 253 ASR_Anf "MLB:DieMomentenanforderung'ASR_MSR_Moment_schnell'und'ASR_Moment_langsam'sindauszuführen
MQB: Die Momentenanforderung 'BR_Eingriffsmoment' ist auszuführen";
CM_ SG_ 253 MSR_Anf "MLB:DieMomentenanforderung'ASR_MSR_Moment_schnell'istauszuführen.
MQB: Die Momentenanforderung 'BR_Eingriffsmoment' ist auszuführen";
CM_ SG_ 253 EBV_Eingriff "ElektronischeBremskraftverteilung,aktuellerEingriff(Druckhalten,Druckabbau)

Im MLB: kein ABS / ESP-Eingriff ???";
CM_ SG_ 253 EDS_Eingriff "ElektronischeDifferentialsperre";
CM_ SG_ 253 ESP_Eingriff "EingriffdesFahrdynamikreglers";
CM_ SG_ 253 ESP_ASP "MLB:Anhaenger-Stabilisierungs-Programm
MQB: Gespannstabilisierung";
CM_ SG_ 253 ESP_Anhaltevorgang_ACC_aktiv "Zeigtan,obACC-Anhaltevorgangaktiv";
CM_ SG_ 795 ESP_24_CRC "FürMLB:
'Berechnung siehe Lastenheft 'Kommunikationsabsicherung für FlexRay und CAN''

Ab MQB und MLBevo:
'Berechnung siehe Lastenheft 'End-to-End Kommunikationsabsicherung''

Endwerte siehe Begleitdokument 'S-PDU Kennungsfolgen'";
CM_ SG_ 795 ESP_Lampe "ZustandderFahrdynamikregelungslampe(MLB:ASRund/oderESP,MQB:nurESP)

Weiterführende Informationen im Lastenheft spezifiziert und in der entsprechenden Fachabteilung zu erfragen.";
CM_ SG_ 795 ABS_Lampe "Sicherheitswarnlampe

Weiterführende Informationen im Lastenheft spezifiziert und in der entsprechenden Fachabteilung zu erfragen.";
CM_ SG_ 795 BK_Lampe_02 "SicherheitswarnlampesignalisiertEBV-Ausfall

MQB: wird auch bei HBV-Ausfall verwendet.

Weiterführende Informationen im Lastenheft spezifiziert und in der entsprechenden Fachabteilung zu erfragen.";
CM_ SG_ 795 TC_Lampe "M-ABSLampe(separateLampefürM-ABS-SystemeMarktBrasilien)

Weiterführende Informationen im Lastenheft spezifiziert und in der entsprechenden Fachabteilung zu erfragen.";
CM_ SG_ 795 ESP_m_Raddrehz "RadumdrehungenproSekundesindEingangsgrößefürdieGeschwindigkeitsberechnungimKombi.AusdieserRaddrehzahlunddemRadumfangwirddieFahrzeuggeschwindigkeiterrechnet.

MLB: Exklusiver Empfänger ist das Kombiinstrument!
MQB: Bei Frontantrieb un";
CM_ SG_ 795 ESP_Textanzeigen_03 "TextanzeigenderFahrdynamikregelungimKombiinstrument

Weiterführende Informationen im Lastenheft spezifiziert und in der entsprechenden Fachabteilung zu erfragen.

Der Signalwert 24 wird nur im BY736 verwendet.";
CM_ SG_ 795 ESP_Meldungen "ESPsendetimHinweis-/StörungsfallandasKombiInformationenzumAnzeigen

Weiterführende Informationen im Lastenheft spezifiziert und in der entsprechenden Fachabteilung zu erfragen.
Ergänzender Hinweis:
1 = Autohold_Hinweis_1 (Anfahrassistent: nu";
CM_ SG_ 795 ESP_Wegimp_VA "WeiterführendeInformationenimLastenheftspezifiziertundinderentsprechendenFachabteilungzuerfragen.

MLB: Die Wegimpulse Vorderachse sind die gemittelten Werte (reine mathematische Operation: Addition und Division durch zwei, keine Filterung) d";
CM_ SG_ 795 ESP_Fehlerstatus_Wegimp "WeiterführendeInformationenimLastenheftspezifiziertundinderentsprechendenFachabteilungzuerfragen.

MLB: Fehler wird gesetzt, wenn beide ESP-Drehzahlfühler an der Vorderachse defekt sind.

MQB: Fehler wird gesetzt, wenn beide Raddrehzahlfühl";
CM_ SG_ 795 ESP_Wegimp_Ueberlauf "DerWegimpulszähleristproZündungslaufmindestenseinmalübergelaufen

Weiterführende Informationen im Lastenheft spezifiziert und in der entsprechenden Fachabteilung zu erfragen.";
CM_ SG_ 795 ESP_QBit_Wegimp_VA "GesetztbeiErsatzwert,InitoderFehler.";
CM_ SG_ 795 ESP_HDC_FktLampe "FunktionslampeBergabfahrassistent.
(Sender blinkt mit dem Bit 3,3Hz)";
CM_ SG_ 795 ESP_Off_Lampe "BitzurAnsteuerungderseparatenESP-off-LampeimKombi(GesetzesforderungUSA)

MLB:
Verwendung/Bedienung ab D4";
CM_ SG_ 795 ESP_HDC_Regelgeschw "Verwendung/BedienungnurimAU57xAllroad:
HDC-Geschwindigkeit
Dient der Anzeige der HDC-Geschwindigkeit und eines Bergabfahrsymbols im Kombi.
HDC-Standby wird gesetzt sobald der Fahrer den HDC-Taster aktiviert hat.
Bei HDC-Off oder während der Initia";
CM_ SG_ 795 ESP_BKV_Warnung "ESPsendetimHinweis-/StörungsfallandasKombiInformationenzumAnzeigen(Text+Akustik)

Im MQB wird dieses Signal nicht unterstützt!
";
CM_ SG_ 2589283617 ESP_30_CRC "FürMLB:
Berechnung siehe Lastenheft 'Kommunikationsabsicherung für FlexRay und CAN'
Ab MQB und MLBevo:
Berechnung siehe Lastenheft 'End-to-End Kommunikationsabsicherung'

Endwerte siehe Begleitdokument 'S-PDU Kennungsfolgen'";
CM_ SG_ 2589283617 ESP_30_BZ "4bitBotschaftszähler,wirdmitjederSendebotschaftinkrementiert";
CM_ SG_ 2589283617 EDS_Charisma_FahrPr "AktuellesFahrprogrammdesCharisma-TeilnehmersElektronischeDifferentialsperreEDS";
CM_ SG_ 2589283617 EDS_Charisma_Status "SystemstatusdesCharismateilnehmersElektronischeDifferentialsperreEDS";
CM_ SG_ 2589283617 HHC_Charisma_Status "SystemstatusdesCharismateilnehmersBerganfahrassistentHHC";
CM_ SG_ 2589283617 HHC_Charisma_FahrPr "AktuellesFahrprogrammdesCharisma-TeilnehmersBerganfahrassistentHHC";
CM_ SG_ 2589283617 RLE_Anzeigen "AnzeigenfürdieRadlöseerkennung";
CM_ SG_ 2589283617 ESC_Lernfreigabe_Abrollumfang "MeldeteinenFahrdynamikzustand,dereszulässt,dassderAbrollumfangderRädergenauererrechnetwerdendarf.
Die Verwendung des Signals ist ausschließlich für die MQB-Plattform zugelassen.";
CM_ SG_ 2589283617 ESC_Texte_eBKV_Betaetigung "AnweisungenandenFahrerfürdieBetätigungderBremseüberdeneBKVunterVerwendungderSchaltwippenamLenkrad.";
CM_ SG_ 2589283617 ESC_MBK_Meldungen "DasSignalsteuertdieSchaltempfehlungimKombi,diebeiBergabfahrtdenFahrerdaraufhinweistineinegeeigneteFahrstufezuschaltenumeineRekuperationzuermöglichen.";
CM_ SG_ 2589283617 ESC_Anf_KL "NachrichtanMotor-bzw.AntriebssteuergerätzurFestlegungderMotorluefterdrehzahl
Angabe in Prozent der Maximaldrehzahl";
CM_ SG_ 2589283617 ESC_Anf_KV "NachrichtanMotorbzw.AntriebssteuergerätzumÖffnenderKühlerjalousie.";
CM_ SG_ 2589283617 ESC_FBA_Meldungen "HinweisandenFahrerüberdasKombi,beidauerhafterBergabfahrteinenGangeinzulegenumdieMotorbremsezunutzen.
Unterscheidung zwischen:
Handschalterfahrzeugen (FBA_Warnung_aktiv_MT)
Automatikfahrzeugen (FBA_Warnung_aktiv_AT)";
CM_ SG_ 2589283617 DBK_Fahrerwarnung "WarntdenFahrerbeierkannterDampfblaseinderBremsflüssigkeitundfordertihnzumAnhaltensowieWerkstattbesuchauf(2Bit):
0: kein Anfordern (Initwert)
1: Warnereignis 1 - fordert Warnlampe, Warnmeldung (Aufforderung Anhalten) und Warnton sowie F";
CM_ SG_ 2527679668 eTM_Ventil1_Status "AnsteuerungNT2Kuehler-BypassventilimKuehlkreisHV-Komponenten";
CM_ SG_ 2527679668 eTM_Ventil2_Status "AnsteuerungHeizkreisabsperrventilimKühlkreisHTKreis";
CM_ SG_ 2527679668 eTM_Ventil3_Status "AnsteuerungGetriebeölkühler-AbsperrventilimKühlkreisHTKreis";
CM_ SG_ 2527679668 eTM_Pumpe3_Status "AnsteuerungPumpeNT1(KühlkreisNTKomponenten)";
CM_ SG_ 2527679668 eTM_BMS_Pumpe1_SollAnsteuerung "SollwertAnsteuerungBMSPumpe1fürBefüllung";
CM_ SG_ 2527679668 eTM_Pumpe2_Volumenstrom "Soll-KühlwasservolumenstromvonPumpe2KühlkreisHVKomponenten";
CM_ SG_ 2527679668 eTM_BMS_Ventil2_Befuellung "AnsteuerungBMSVentil2fürBefüllung";
CM_ SG_ 2527679668 eTM_Pumpe1_Volumenstrom "Soll-KühlwasservolumenstromvonPumpe1KühlkreisHVKomponenten";
CM_ SG_ 2527679668 eTM_BMS_Pumpe1_Befuellung "AnsteuerungBMSPumpe1fürBefüllungaktiv";
CM_ SG_ 2527679668 eTM_BMS_Ventil1_Befuellung "AnsteuerungBMSVentil1fürBefüllung";
CM_ SG_ 2527679668 eTM_Pumpe1_Status "AnsteuerungPumpe1KühlkreisHVKomponenten";
CM_ SG_ 2527679668 eTM_Pumpe2_Status "AnsteuerungPumpe2KühlkreisHVKomponenten";
CM_ SG_ 2527679668 eTM_Temperatur_1 "Wassertemperatur1KühlkreisHVKomponenten";
CM_ SG_ 2527679668 eTM_Temperatur_2 "Wassertemperatur2KühlkreisHVKomponenten";
CM_ SG_ 2527679740 KBI_aktive_Laengsfunktion_02 "Auswahl,dervomFahrergewünschtenLaengsregelfunktion";
CM_ SG_ 2527679740 KBI_Anzeigestatus_GRA "AnzeigestatusderGRAHighWunschgeschwindigkeitsanzeigeimKombiinstrument.
Bei VW bedeutet 'nicht vorhanden' GRA-low fähig (LED immer verbaut).
0 = nicht vorhanden
1 = Wunschgeschwindigkeits-Anzeigemöglichkeit vorhanden
2 = reserviert
3 = Fehler (B";
CM_ SG_ 2527679740 KBI_Anzeigestatus_LIM "AnzeigestatusderSpeedlimiterWunschgeschwindigkeitsanzeigeimKombiinstrument(permanenterAnzeigebereich)
0 = nicht vorhanden
1 = Wunschgeschwindigkeits-Anzeigemöglichkeit vorhanden
2 = reserviert
3 = Fehler (Botschaftsüberwachung, Timeout, Akustik";
CM_ SG_ 2527679740 KBI_Anzeigestatus_ACC "StatusderACC-AnzeigeimnichtpermanentenDisplaybereich";
CM_ SG_ 2527679740 KBI_Konsistenz_ACC "RückmeldunganACC,dassdieBotschaftenzurAnsteuerungvonAnzeigennichtbzw.nichtkonsistentempfangenwurden(Timeout-,BZ-,CHK-undDLC-Fehler)";
CM_ SG_ 2527679740 KBI_Fehler_Anzeige_ACC "RückmeldunganACC,dassmindestenseinederACC-relevantenAnzeigen-roteFahrerübernahme,Mitteldisplay,Gong-fehlerhaftsind.";
CM_ SG_ 2589283684 GRA_FoD_Status "VerortungdesFOD-SlavesfürdieFunktionGRAerfolgtimGateway.SignalübermitteltdenFOD-StatusandasMSG.";
CM_ SG_ 2589283684 FoD_Transmission_Info "MitdemSignalzeigtderFoD-MasterallenFoD-SlavesdenBeginnunddasEndeeinesFreischaltuebertragungszykluses(FS-ID-Zyklus)an.";
CM_ SG_ 2549875574 FoD_MO_01_Req_Data "FoD-FunctionOnDemand
ISO-TP Datenkanal - FID2NA Knoten 0x76 Motor (ASG)

FoD-Master an FoD-Slave ASG";
CM_ SG_ 2550006646 FoD_MO_01_Resp_Data "FoD-FunctionOnDemand
ISO-TP Datenkanal - FID2NA
Response Knoten 0x76 Motor

Motor an FoD Master";
CM_ SG_ 987 ZV_verriegelt_extern_soll "Sollzustand:VerriegelungFahrzeugaussen
";
CM_ SG_ 987 BH_Lichthupe "BetaetigungLichthupe
";
CM_ SG_ 987 WFS_Klemmenfreigabe "FreigabevonderWFSzumEinschaltenderKlemme15undKlemmeS";
CM_ SG_ 987 ZV_Tankklappe_offen "ÖffnungsstatusderTankklappe";
CM_ SG_ 987 AAG_Anhaenger_abgesteckt "AnhaengerwurdebeiKl.15ausabgesteckt";
CM_ SG_ 987 BCM1_LDS_Stellung "DasSignalwirdvomAFS/LWRSteuergerätempfangenunddientderVerifizierungderLichtdrehschalterstellung.IntelligenteLichtfunktionenwiedyn.KLundgleitendeLeuchtweite(GLW)nurbeiLDS='AUTO'.";
CM_ SG_ 987 VS_Verdeck_Anf "



";
CM_ SG_ 987 VS_VD_entriegelt "

";
CM_ SG_ 987 ZV_HFS_offen "gespiegeltesBitHFS_Tuer_geoeffnetTSG_HFS_1Botschaft";
CM_ SG_ 987 ZV_HBFS_offen "gespiegeltesBitHBFS_Tuer_geoeffnetTSG_HBFS_1Botschaft";
CM_ SG_ 987 VS_VD_offen_ver "ZustanddesVerdecksverriegeltundoffen";
CM_ SG_ 987 VS_VD_zu_ver "
";
CM_ SG_ 987 ZV_BT_offen "gespiegeltesBitBT_Tuer_geoeffnetTSG_BT_1Botschaft";
CM_ SG_ 987 BCM1_Rueckfahrlicht_Schalter "Rückfahrlichtschalter
ab MQB/ MLBevo: Die Ganginformation wird unentprellt übertragen, im AT-Getriebe wird evtl. kurzzeitig der R-Gang angezeigt. Eine Entprellung muß im Empfänger erfolgen (typisch 400ms).";
CM_ SG_ 987 ZV_FT_offen "gespiegeltesBitFT_Tuer_geoeffnetTSG_FT_1Botschaft";
CM_ SG_ 987 Wischer_vorne_aktiv "Status:Wischervorne";
CM_ SG_ 987 AAG_Anhaenger_erkannt "ErkennungAnhaenger";
CM_ SG_ 987 BCM1_MH_Schalter "Motorhaubenkontakt";
CM_ SG_ 987 ZV_HD_offen "StatusHeckdeckel
";
CM_ SG_ 987 Waschen_vorne_aktiv "Status:Waschenvorneaktiv
";
CM_ SG_ 987 KL_Thermomanagement "StufendesThermomanagement";
CM_ SG_ 987 WFS_Schluessel_Fahrberecht "SchlüsselnummerFahrberechtigung
0 = ungueltig, xxxx = Schluessel-Nr.";
CM_ SG_ 987 BCM_Rueckfahrlicht_Anf "AnforderungRückfahrlicht(Sollzustand).
Das Signal wird entprellt (typisch 400ms) und bei KL15EIN gesendet. Das Signal ist unabhängig von der Position des Heckdeckels (kein Überhitzungsschutz).";
CM_ SG_ 987 WWSs_01_alt "VeraltetBitfürdieLIN-BotschaftWWSs_01.

Betroffene Signale:

Wischer_vorne_aktiv";
CM_ SG_ 987 BCM_Tankklappensteller_Fehler "Fehler:nichtFunktionalitätdesTankklappenstellers";
CM_ SG_ 987 AAG_LED_aktiv "DiesesSignalsendetderBeleuchtungsartdesAnhängers(LEDoderLampe)
Bei LED aktiv erfolgt kein Kaltüberwachung";
CM_ SG_ 987 ZV_verriegelt_soll "FahrzeugGesamtverriegelungsstatusSollzustandfürLadestecker-undLadeklappenverriegelung.";
CM_ SG_ 987 ZV_Schluessel_Zugang "aktuelleFunkschlüsselnummer";
CM_ SG_ 987 WFS_ID_Geb_autorisiert_in_Kl15 "AuthorisierungdesSchlüsselsimaktivenKlemme-15-Zyklus";
CM_ SG_ 987 BH_Fernlicht "BetaetigungFernlicht
";
CM_ SG_ 987 BH_Blinker_li "BlinkerhebelRichtunglinks
";
CM_ SG_ 987 BH_Blinker_re "BlinkerhebelRichtungrechts
";
CM_ SG_ 987 BCM1_OBD_FStatus_ATemp "FehlerstatusUmgebungstemperatursensor(OBDrelevanterSensor)
";
CM_ SG_ 987 BCM1_Aussen_Temp_ungef "ungefilterterWertdesAussentemperatursensors
";
CM_ SG_ 173 Getriebe_11_CRC "FürMLB:
'Berechnung siehe Lastenheft 'Kommunikationsabsicherung für FlexRay und CAN''

Ab MQB und MLBevo:
'Berechnung siehe Lastenheft 'End-to-End Kommunikationsabsicherung''

Endwerte siehe Begleitdokument 'S-PDU Kennungsfolgen'";
CM_ SG_ 173 Getriebe_11_BZ "Botschaftszähler";
CM_ SG_ 173 GE_MMom_Soll_02 "MomenteneingriffandenMotor.
Fordert vom MSG eine kurzfristige Reduzierung oder Anhebung des Moments.
Das Signal ist nur gültig in Kombination mit GE_MMom_Status (bei MQB) bzw. GE_MMom_Status_02 (bei MLBevo).

Achtung:
Einheitenloser Wert! Faktor i";
CM_ SG_ 173 GE_MMom_Vorhalt_02 "AnforderungeinerMomentenreservedurchdasGetriebe,giltnurmitFreigabedurch
GE_Freig_MMom_Vorhalt

Anforderung wird als Absolut-Wert umgesetzt, nicht als Relativ-Wert/Delta zum aktuellen Ist-Moment (d. h. eine Momentenreserve wird eingestellt, w";
CM_ SG_ 173 GE_Uefkt "ÜbertragungsfunktiondesGetriebes
Drehzahlverhältnis = Eingangsdrehzahl / Ausgangsdrehzahl

AL: Wandlerverstärkung x Drehzahlverhältnis
VL: Drehzahlverhältnis
DL: Drehzahlverhältnis der aktiven und kraftschluß führenden Welle zum Abtrieb, bei Schalt";
CM_ SG_ 173 GE_Fahrstufe "FahrprogrammdesGetriebes

Hinweis: Zwischenstellung '0x0' darf nur für Zustandswechsel P/R, R/N, N/D ausgegeben werden, nicht für D/S oder D/Tippgasse wegen Abschaltkriterium GRA/ACC";
CM_ SG_ 173 GE_Schaltablauf "DasSignalzeigtdenaktuellenStatuseinesSchaltvorgangs.

Bei Signal = 0 liegt kein Schaltvorgang vor.
Bei Signal =2 liegt die Befüllphase der zuschaltenden Kupplung bzw.
die Vorbereitungsphase dazu vor.

Mit den unterschie";
CM_ SG_ 173 GE_Uefkt_unplausibel "DasSignaldarfnurimReku-ManagerinHybrid-Variantenverwendetwerden.
Zeigt an, ob die Plausibilisierung Momenten-Verhältnis zu Drehzahl-Verhältnis i.O. ist.
Ein gesetztes Signal meldet eine unplausible GE_Uefkt bzw. GE_Uefkt_02.";
CM_ SG_ 173 GE_MMom_Status_02 "DasSignalqualifiziertGE_MMom_Soll_02undgibtan,wiederWertausGE_MMom_soll–vorbehaltlichderUmsetzbarkeitaufgrundmotorinternerRestriktionen–umgesetztwerdensoll.
Werte:
0= kein Eingriff
1=   absoluter reduzierender Eingriff auf Gesamt ";
CM_ SG_ 173 GE_Status_Kraftschluss "ZeigtdenIst-StatusdesKraftschlussesimGetriebe.
(Anmerkung: meist wird damit der Zustand des Anfahrelements beschrieben, d.h. bei DL/DQ die Kupplung;  bei AQ/AL der Wandler incl. Überbrückungskupplung)
0 = offen, kein Kraftschluss
1 = offen mit Kr";
CM_ SG_ 173 GE_MMom_Status "Qualifiziert
MLB: GE_MMom_Soll
MQB: GE_MMom_Soll_02";
CM_ SG_ 173 GE_Freig_MMom_Vorhalt "FreigabefürdieAnforderungeinerMomentenreservedurchdasGetriebeüberdasSignal
MLB: GE_MMom_Vorhalt
MQB/MLBevo: GE_MMom_Vorhalt_02";
CM_ SG_ 173 GE_Verbot_Ausblendung "VerbotEinspritzausblendungfürkomfortableSchaltungen";
CM_ SG_ 173 GE_Zielgang "VL-Getriebe:
Signalisiert den Zielgang im manuellen Modus während eines Schaltvorgangs bzw. die momentane simulierte Gangstufe wenn kein Schaltvorgang aktiv ist. In den Fahrprogrammen 'D' und 'S' ist die Übersetzung variabel und somit wird dauerhaft 'Ist";
CM_ SG_ 324 Getriebe_16_CRC "FürMLB:
'Berechnung siehe Lastenheft 'Kommunikationsabsicherung für FlexRay und CAN''

Ab MQB und MLBevo:
'Berechnung siehe Lastenheft 'End-to-End Kommunikationsabsicherung''

Endwerte siehe Begleitdokument 'S-PDU Kennungsfolgen'";
CM_ SG_ 324 GE_Ausleuchtung_Fahrstufe "FahrstufezurAnzeigeinderSchaltbetätigung.IstdieFahrstufeungültig,wirdkeineFahrstufeangezeigt.";
CM_ SG_ 324 GE_Testparameter_1 "Testparameter1(Frage)zurÜberwachungdesWählhebel-SG";
CM_ SG_ 324 GE_Testparameter_2 "Testparameter2(Frage)zurÜberwachungdesWählhebel-SG";
CM_ SG_ 324 GE_Test_Freigabe "DasBitwirdauf1gesetzt,wenngültigeTestparametergesendetwerden.";
CM_ SG_ 324 GE_N_Haltephase "DasGetriebesignalisiertdemWaehlhebel,dassdieN-Haltephaseaktivist.
Danach kann der Waehlhebel ein Abschalten des I-CAN ermöglichen";
CM_ SG_ 324 GE_WH_Abschalten "MitdiesemBitkanndasGetriebedasWählhebel-SGresetenbzw.dauerhaftdeaktivieren.DerWählhebelgehtdannineinenStandby-Modus.";
CM_ SG_ 324 GE_Soll_Haltemagnet "SollpositiondesParksperren-HaltemagnetenfürdieAnsteuerungdurchdenWaehlhebel";
CM_ SG_ 324 GE_WH_Shiftlock "Bitwirdauf1gesetzt,wenngetriebeseitigenBedingungenerfülltsind,umWählhebelzubewegen.";
CM_ SG_ 324 GE_WH_Mute "AnforderungandieSchaltbetätigung,denSendebetriebeinzustellen.";
CM_ SG_ 324 GE_Ausleuchtung_blinkend "AnforderungeinerblinkendenFahrstufenausleuchtunginderSchaltbetätigung";
CM_ SG_ 299 GRA_ACC_01_CRC "FürMLB:
'Berechnung siehe Lastenheft 'Kommunikationsabsicherung für FlexRay und CAN''

Ab MQB und MLBevo:
'Berechnung siehe Lastenheft 'End-to-End Kommunikationsabsicherung''

Endwerte siehe Begleitdokument 'S-PDU Kennungsfolgen'";
CM_ SG_ 299 GRA_ACC_01_BZ "4bitBotschaftszaehler,wirdmitjederSendebotschaftinkrementiert";
CM_ SG_ 299 GRA_Hauptschalter "StellungdesGRA/ACC-Hauptschalters:
Bei gerastetem Hauptschalter:
0: Hauptschalter aus
1: Hauptschalter ein
Bei getastetem Hauptschalter:
0: Taster nicht betätigt
1: Taster betätigt";
CM_ SG_ 299 GRA_Abbrechen "GRA:ausmitspeichern
ACC : Soft aus";
CM_ SG_ 299 GRA_Typ_Hauptschalter "VariantedesGRA/ACC-Hauptschalters:
0: gerasteter Hauptschalter (bzw. Taster mit Speicherung des Status im SMLS (PAG))
1: getasteter Hauptschalter, keine Speicherung des Status im SMLS";
CM_ SG_ 299 GRA_Limiter "StellungdesLimiter-Tasters";
CM_ SG_ 299 GRA_Tip_Setzen "TippschalterSet";
CM_ SG_ 299 GRA_Tip_Hoch "TippschalterTipUp/Geschwindigkeiterhöhen";
CM_ SG_ 299 GRA_Tip_Runter "TippschalterTipDown/Geschwindigkeitreduzieren";
CM_ SG_ 299 GRA_Tip_Wiederaufnahme "TippschalterWiederaufnahme";
CM_ SG_ 299 GRA_Verstellung_Zeitluecke "VerstellungderZeitlückefürACC

DIST -1 = Zeitluecke um 1 Stufe kleiner
DIST +1 = Zeitluecke um 1 Stufe groeßer
DIST Toggle = Zeitlücke um 1 Stufe kleiner, von kleinster Stufe auf größte Stufe";
CM_ SG_ 299 GRA_Codierung "DasSignalzeigtan,obdasSende-SG(SMLS/MFL)aufGRA-oderACC-Bedienteilcodiertist:
0: kein GRA- oder ACC Bedienteil
1: GRA-Bedienteil
2: ACC-Bedienteil
3: Limiter_Only-Bedienteil";
CM_ SG_ 299 GRA_Fehler "DasSignalzeigtan,dassdasSende-SG(SMLS/MFG)einenDefektdesGRA-BedienteilserkannthatundhierzueinFSPEabgelegtwurde.";
CM_ SG_ 299 GRA_LIM_Taste_verfuegbar "DasSignalzeigtan,obeineLimiter-UmschalttasteamjeweiligenGRA/ACC-Bedienelementvorhandenist.";
CM_ SG_ 299 GRA_Tip_Stufe_2 "Signalzeigtan,dassderzweistufigeGRA/ACC-Hebel(8_Positions_Bedienteil)inder2.Tip-Stufebetätigtwird.DasSignalwirdnurgleichzeitigmitdemSignalGRA_Tip_HochoderGRA_Tip_Runtergesetzt,wobeidieBitsGRA_Tip_Hochbzw.GRA_Tip_RunterdieR";
CM_ SG_ 299 GRA_Typ_Bedienteil "DasSignalkennzeichnetdieVariantedesGRA/ACC-Bedienteils:
0: Init
1: 4-Positionen-Bedienteil (z.B. GRA im Blinkerhebel)
2: 6-Positionen-Bedienteil (GRA/ACC-Bedienteil mit separaten Stellungen für Set/Resume/TipUp/TipDown)
3: 8-Positionen-Bediente";
CM_ SG_ 299 GRA_TravelAssist "TastefürTravelAssist";
CM_ SG_ 299 GRA_reserveByte4 "Zweck:BefüllenderreserviertenBitpositionenmit0(wg.LIN-TeilnehmerMFL)";
CM_ SG_ 299 GRA_reserveByte5 "Zweck:BefüllenderreserviertenBitpositionenmit0(wg.LIN-TeilnehmerMFL)";
CM_ SG_ 299 GRA_reserveByte6 "Zweck:BefüllenderreserviertenBitpositionenmit0(wg.LIN-TeilnehmerMFL)";
CM_ SG_ 299 GRA_reserveByte7 "Zweck:BefüllenderreserviertenBitpositionenmit0(wg.LIN-TeilnehmerMFL)";
CM_ SG_ 299 GRA_reserveByte8 "Zweck:BefüllenderreserviertenBitpositionenmit0(wg.LIN-TeilnehmerMFL)";
CM_ SG_ 1452 HVEM_IstStrom_HVVerbraucher "IststromaufnahmederelektrischenNebenaggregateausdemHVZwischenkreis";
CM_ SG_ 1452 HVEM_Energie_Klima_Vorgabe_HighR "ErweiterteAuflösungvon10WhfürSignalHVEM_Energie_Klima_Vorgabe.
Signalwert wird zu HVEM_Energie_Klima_Vorgabe Addiert";
CM_ SG_ 1452 HVEM_IstLeistungNA "aktuelleLeistungsaufnahmederNebenaggregate";
CM_ SG_ 1452 HVEM_Leistung_Klima_Vorgabe "LeistungsvorgabeThermo(fürKühlenundHeizen)";
CM_ SG_ 1452 HVEM_Nutzbare_Energie "NutzbareEnergiewelchefürKomfortfunktionenvomHVEMfreigegebenwird.";
CM_ SG_ 1452 HVEM_Energie_Klima_Vorgabe "HVEM-EnergievorgabefürKlima-Vorkonditionierung";
CM_ SG_ 1452 HVEM_HVK_Aktivitaet "DemHVEMsindHV-Komponentenzugeordnet.DasHVEMübermitteltandenHVKein
Hochvolt –Aktivitätsstatus dieser HV-Komponenten.";
CM_ SG_ 1452 HVEM_Pruefpuls_Anf "PrüfpulsanforderungandenHV-Koordinator";
CM_ SG_ 1452 HVEM_HV_Anf "HVAnforderungdesHVEnergiemanagementsandasMSG";
CM_ SG_ 1452 HVEM_MO_MaxLeistungIgnoriert "RueckmeldungdesHVEMobdievorgegebeneMaxLeistungvomMSGeingehaltenwird.";
CM_ SG_ 1385 HVEM_NVLeistungEmpf "MaximalerSollwertderaktuellenLeistungderNV-SeitedesDCDC-Wandlers.";
CM_ SG_ 1385 HVEM_DCDC_Freigabe "FreigabedesDCDCwenndasFzgnichtFahrbereitist.";
CM_ SG_ 1385 HVEM_KlimaMaxHVStrom "KommuniziertdemKlimasteuergerätdenmax.Aufnahmestrom";
CM_ SG_ 1385 HVEM_Ladesteckerentr_Anf "AnforderungLadesteckerentriegelnnachZVAufBefehl";
CM_ SG_ 1385 HVEM_LeistungsAnf "AnforderunganNV-EMzurErhöhungderPerformancedenEnergieverbrauchaufderNV-Seitezureduzieren.";
CM_ SG_ 1385 HVEM_Nachlad_Status "StatusderUmsetzungderNachladeanforderungderNV-Seite.";
CM_ SG_ 1385 HVEM_Abschaltstatus "StatusderReduzierungsstufenderKlimakomponentenbeimLaden

0 = 100% (keine Reduzierung)
1 = 75%
2 = 50%
3 = 25%
7 = Init";
CM_ SG_ 1385 HVEM_Anf_ReichweiteNV "AnforderunganNV-EMzurErhöhungderReichweitedenEnergieverbrauchaufderNV-Seitezureduzieren.";
CM_ SG_ 1385 HVEM_LadeklappenVerr_Anf "AnforderungeinesVer-oderEntriegelnsderLadedosenklappeüberdieZV.";
CM_ SG_ 1385 HVEM_Max_VK_Betriebsdauer "BetriebslaufzeitderStandklimatisierung";
CM_ SG_ 1385 HVEM_HV_Anf "HVAnforderungdesHVEnergiemanagementsandasMSG";
CM_ SG_ 1385 HVEM_Text_1 "MeldungbeieinemAnzeigeSOC<10%('AchtungBatterieladen.Funktioneneingeschränkt')";
CM_ SG_ 1385 HVEM_Nachladen_Anf "AnforderungfürHVLadenbeigestecktemSteckerunddeaktivierterLadeanforderung";
CM_ SG_ 1385 HVEM_FreigabeKlimatisierung "Klimatisierungfreigeben";
CM_ SG_ 1385 HVEM_Leistung_Bat_Kond_Vorgabe "elektr.LeistungsvorgabeThermoBatterie";
CM_ SG_ 1283 HVK_01_CRC "FürMLB:
'Berechnung siehe Lastenheft 'Kommunikationsabsicherung für FlexRay und CAN''

Ab MQB und MLBevo:
'Berechnung siehe Lastenheft 'End-to-End Kommunikationsabsicherung''

Endwerte siehe Begleitdokument 'S-PDU Kennungsfolgen'";
CM_ SG_ 1283 HVK_Istmodus_Anf "HVK-AnforderunganalleHV-KomponentenderenIstmodusimschnellenZyklus(Inhibitzeit)zusenden.";
CM_ SG_ 1283 HVK_TN1_Sollmodus "AngeforderterSollmodusderSteuereinheitfürdasSchützedesTeilnetz1'Ladepfad':
0 : HV_Off
1 : HV_On (Schütz geschlossen)
2 : reserviert
3 : Init   (CAN-Initialisierung)";
CM_ SG_ 1283 HVK_Vorladung_aktiv "Systeminformation,dassaktivvorgeladenwird";
CM_ SG_ 1283 HVK_BMS_Sollmodus "AngeforderterSollmodusderHV-Batterie:
0 : HV_Off
1 : HV_On (HS geschlossen)
2 : nicht belegbar
3 : AC-Laden_erw (HS +AC_2-Schütze geschlossen)
4 : AC-";
CM_ SG_ 1283 HVK_DCDC_Sollmodus "angeforderteSoll-BetriebsartdesDC/DC-Wandlers:
0: Standby; Kommunikation aktiv
1: Zwischenkreis des HV-Netzes wird vorgeladen; HV-Netz wird aktiviert und darf nicht
belastet werden.
2: Tiefsetzen (HV --> BN 14,4V)
Sollwertvorgabe projek";
CM_ SG_ 1283 HVK_EKK_Sollmodus "SollmoduselektrischerKlimakompressor";
CM_ SG_ 1283 HVK_HVPTC_Sollmodus "SollmodusHV-PTC
0 : keine Freigabe
1 : Freigabe
2 : Freigabe_ausgesetzt
3 : nicht belegbar
4 : nicht belegbar
5 : nicht belegbar
6 : nicht belegbar
7 : Init   (CAN-Initialisierung)

Info: 'nicht belegbar' d.h. Sollmodus nicht relevant für HV";
CM_ SG_ 1283 HVK_HVLM_Sollmodus "AngeforderterSollmodusdesLademanagers.";
CM_ SG_ 1283 HVK_HV_Netz_Warnungen "AnforderungWarnung/FehlerHV-SystemimKombi
0: Keine Warnung/Init
1:Anforderung_Anzeige_Warnung_HV-Netz (gelbes Symbol)
2:Anforderung_Anzeige_Fehler_HV-Netz (rotes Symbol)
3:Anforderung_Anzeige_Warnung_Kein_Wiederstart_möglich";
CM_ SG_ 1283 HV_Bordnetz_aktiv "SignalisierteinaktivesHochvoltbordnetz.FürdieBelastbarkeitdesHV-NetzesmüssenStrom-bzw.Leistungsgrenzeneingehaltenwerden";
CM_ SG_ 1283 HV_Bordnetz_Fehler "StatusobimHV-NetzeinFehlerdetektiertwurde.";
CM_ SG_ 1283 HVK_Gesamtst_Spgfreiheit "StatusdesHV-Systems";
CM_ SG_ 1283 HVK_AktiveEntladung_Anf "AnforderungzumaktivenEntladendesHV-Netzes,währendderAbschaltungdesHV-Netz.";
CM_ SG_ 1283 HVK_HVEM_Freigabe "DerHVKgibtdasHVEMfrei,umdasHV-NetzunterEinhaltungvonLeistungsgrenzeninAnspruchzunehmen.";
CM_ SG_ 1283 HVK_Notentladung_Anf "AufforderungzurschnellstmöglichenEntladungdesHV-NetzesaufgrundHV-Sicherheit(Crash-Erkennung/AbrissPilotlinie/…).";
CM_ SG_ 1283 HVK_Iso_Messung_Start "AnforderungandieisolationswiderstandsüberwachendenHV-KomponentenzurDurchführungderIsolations-Widerstandsmessung.";
CM_ SG_ 1283 HVK_Ladebereit "InformationandasLademanagement,dassdasHV-SystemausSichtdesHVKsbereitgestelltwerdenkann.";
CM_ SG_ 1283 HVK_PPulsFreigabe "Prüfpuls-FreigabeseitensHochvoltkoordinator";
CM_ SG_ 2463978813 HVL_01_CRC "FürMLB:
Berechnung siehe Lastenheft 'Kommunikationsabsicherung für FlexRay und CAN'
Ab MQB und MLBevo:
Berechnung siehe Lastenheft 'End-to-End Kommunikationsabsicherung'

Endwerte siehe Begleitdokument 'S-PDU Kennungsfolgen'";
CM_ SG_ 2463978813 HVL_01_BZ "4bitBotschaftszähler,wirdmitjederSendebotschaftinkrementiert";
CM_ SG_ 2463978813 HVL_Steckerstatus "StelltdenStatusdesLadesteckershinsichtlichPräsenzzurVerfügung";
CM_ SG_ 2463978813 HVL_LadeAnforderung "FuSi-AbgesicherteLadeanforderungandenHVK";
CM_ SG_ 626 HVLM_Anforderung_HMS "AnforderungzurVerriegelungdesTriebstrangs";
CM_ SG_ 626 HVLM_Parken_beibehalten_HMS "AnforderungdenTriebstrangverriegeltzuhalten";
CM_ SG_ 626 HVLM_WakeUpZaehlerResetAnf "0=keine_Anforderung
1 = Reset_Zaehler";
CM_ SG_ 626 HVLM_AWC_VerbautStatus "VerbausignalisierungvomHVLMderoptionalenKomponenteAWC";
CM_ SG_ 626 HVLM_Steckerstatus_A "GibtdenSteckerstatusausderLadedoseAan";
CM_ SG_ 626 HVLM_Steckerstatus_B "GibtdenSteckerstatusausderLadedoseBan";
CM_ SG_ 626 HVLM_Start_Pulserkennung "StartanforderungfürdiePulserkennung";
CM_ SG_ 626 HVLM_ZustandLadeablauf "ZustandimAblaufdesLadevorganges
0 = Init
1 = Standby_Ladevorbedingungen erfuellt
2 = Standby_Ladevorbedingungen_nicht_erfuellt
3 = Fehler
4 = Laden_starten
5 = Laden_beenden
6 = HVBatterie_Laden
7 = HVBatterie_Entladen
8 = Erhaltungsladen";
CM_ SG_ 626 HVLM_DC_Aufstartmodus "AufstartmoduszumAktivierendesHV-ModusfürDC-Laden
0= keine_Anforderung
1= Angleich_Fahrzeug (Fahrzeug schaltet auf DC-Spannung der Ladesäule auf)
2= Angleich_LS_1 (Ladesäule schaltet auf DC-Spannung des Fahrzeuges auf Methode 1)
3= Angleich_LS_2 ";
CM_ SG_ 626 HVLM_Ladeszenario "ÜberdiesesSignalwirddaseinzustellendeSzenariofürdieVisualisierunggesendet.";
CM_ SG_ 626 HVLM_Ladevorgang_Anf "ArtderangefordertenLadeart
0 = Laden_nicht_angefordert
1 = AC_Laden_Angefordert
2 = DC_Laden_Angefordert
3 = AC_und_DC_Angefordert
4 = Induktiv_Laden_Angef
5 = AC_und_Induktiv_Angef
6 = DC_und_Induktiv_Angef
7 = AC_DC_und_Induktiv_Angef";
CM_ SG_ 626 HVLM_Intensitaet "ÜberdiesesSignalwirdeineInformationüberdieBeleuchtungsintensitätgesendet.";
CM_ SG_ 626 HVLM_Laden_ISO_Messung_Anf "MessungdesIsolationswiderstandesdesLadesystems(FzgundLadesäule)währenddesLadevorgangesdurchdasFahrzeug
0= Anforderung
1= keine_Anforderung";
CM_ SG_ 268 ImoCord_Auth_Aufforderung_WFS "WFS-Anforderung";
BA_DEF_ BO_ "DiagRequest" ENUM "No", "Yes";
BA_DEF_ BO_ "DiagResponse" ENUM "No", "Yes";
BA_DEF_ BO_ "DiagState" ENUM "No", "Yes";
BA_DEF_ BO_ "GenMsgChkConstant" HEX 0 4095;
BA_DEF_ BO_ "GenMsgCycleTime" INT 0 65535;
BA_DEF_ BO_ "GenMsgCycleTimeFast" INT 0 65535;
BA_DEF_ BO_ "GenMsgDelayTime" INT 0 100000;
BA_DEF_ BO_ "GenMsgILSupport" ENUM "No", "Yes";
BA_DEF_ BO_ "GenMsgNrOfRepetition" INT 0 100;
BA_DEF_ BO_ "GenMsgPDUConstants" STRING;
BA_DEF_ BO_ "GenMsgSendType" ENUM "Cyclic", "not_used", "not_used", "not_used", "not_used", "not_used", "not_used", "IfActive", "NoMsgSendType";
BA_DEF_ BO_ "GenMsgStartDelayTime" INT 0 100000;
BA_DEF_ BO_ "NmMessage" ENUM "No", "Yes";
BA_DEF_ BO_ "NmhMessage" ENUM "No", "Yes";
BA_DEF_ BO_ "MsgType" ENUM "Application", "NM", "NMH", "TP2.0", "ISO-TP", "BAP", "EID", "KS";
BA_DEF_ BO_ "VAGTP20_API" HEX 0 255;
BA_DEF_ BO_ "VAGTP20_DynConnection" ENUM "No", "Yes";
BA_DEF_ BO_ "VAGTP20_DynSetup" ENUM "No", "Yes";
BA_DEF_ BO_ "VAGTP20_StatConnection" ENUM "No", "Yes";
BA_DEF_ BO_ "CANFD_BRS" ENUM "0", "1";
BA_DEF_ BO_ "VFrameFormat" ENUM "StandardCAN", "ExtendedCAN", "reserved", "reserved", "reserved", "reserved", "reserved", "reserved", "reserved", "reserved", "reserved", "reserved", "reserved", "reserved", "StandardCAN_FD", "ExtendedCAN_FD";
BA_DEF_ SG_ "GenSigActiveRepetitions" INT -2147483648 2147483647;
BA_DEF_ SG_ "GenSigInactiveValue" INT -2147483648 2147483647;
BA_DEF_ SG_ "GenSigSendType" ENUM "Cyclic", "OnWrite", "OnWriteWithRepetition", "OnChange", "OnChangeWithRepetition", "IfActive", "IfActiveWithRepetition", "NoSigSendType", "OnChangeAndIfActive", "OnChangeAndIfActiveWithRepetition";
BA_DEF_ SG_ "GenSigStartValue" INT -2147483648 2147483647;
BA_DEF_ SG_ "NWM-WakeupAllowed" ENUM "No", "Yes";
BA_DEF_ SG_ "GenSigFuncType" ENUM "NoFunction", "MsgCounter", "CRC-8", "XOR", "XOR-2", "DatedBit", "SW-Kl15", "CHK", "Constant", "Protocol", "CRC-8-SAE_J1850";
BA_DEF_ SG_ "GenSigSwitchedByIgnition" ENUM "No", "Yes";
BA_DEF_ SG_ "Fehlerwert" HEX 0 2147483647;
BA_DEF_ SG_ "GenSigMissingSourceValue" HEX 0 2147483647;
BA_DEF_DEF_  "DiagRequest" "No";
BA_DEF_DEF_  "DiagResponse" "No";
BA_DEF_DEF_  "DiagState" "No";
BA_DEF_DEF_  "GenMsgChkConstant" 0;
BA_DEF_DEF_  "GenMsgCycleTime" 0;
BA_DEF_DEF_  "GenMsgCycleTimeFast" 0;
BA_DEF_DEF_  "GenMsgDelayTime" 0;
BA_DEF_DEF_  "GenMsgILSupport" "No";
BA_DEF_DEF_  "GenMsgNrOfRepetition" 0;
BA_DEF_DEF_  "GenMsgPDUConstants" "";
BA_DEF_DEF_  "GenMsgSendType" "NoMsgSendType";
BA_DEF_DEF_  "GenMsgStartDelayTime" 0;
BA_DEF_DEF_  "NmMessage" "No";
BA_DEF_DEF_  "NmhMessage" "No";
BA_DEF_DEF_  "MsgType" "Application";
BA_DEF_DEF_  "VAGTP20_API" 0;
BA_DEF_DEF_  "VAGTP20_DynConnection" "No";
BA_DEF_DEF_  "VAGTP20_DynSetup" "No";
BA_DEF_DEF_  "VAGTP20_StatConnection" "No";
BA_DEF_DEF_  "CANFD_BRS" "1";
BA_DEF_DEF_  "VFrameFormat" "StandardCAN";
BA_DEF_DEF_  "GenSigActiveRepetitions" 0;
BA_DEF_DEF_  "GenSigInactiveValue" 0;
BA_DEF_DEF_  "GenSigSendType" "NoSigSendType";
BA_DEF_DEF_  "GenSigStartValue" 0;
BA_DEF_DEF_  "NWM-WakeupAllowed" "No";
BA_DEF_DEF_  "GenSigFuncType" "NoFunction";
BA_DEF_DEF_  "GenSigSwitchedByIgnition" "Yes";
BA_DEF_DEF_  "Fehlerwert" 0;
BA_DEF_DEF_  "GenSigMissingSourceValue" 0;
BA_ "GenMsgCycleTime" BO_ 252 10;
BA_ "GenMsgILSupport" BO_ 252 "Yes";
BA_ "GenMsgPDUConstants" BO_ 252 "0x77,0x5c,0xa0,0x89,0x4b,0x7c,0xbb,0xd6,0x1f,0x6c,0x4f,0xf6,0x20,0x2b,0x43,0xdd";
BA_ "GenMsgSendType" BO_ 252 "Cyclic";
BA_ "VFrameFormat" BO_ 252 "StandardCAN_FD";
BA_ "GenMsgCycleTime" BO_ 2463978647 100;
BA_ "GenMsgILSupport" BO_ 2463978647 "Yes";
BA_ "GenMsgSendType" BO_ 2463978647 "Cyclic";
BA_ "VFrameFormat" BO_ 2463978647 "ExtendedCAN_FD";
BA_ "GenMsgCycleTime" BO_ 2527679683 2000;
BA_ "GenMsgDelayTime" BO_ 2527679683 100;
BA_ "GenMsgILSupport" BO_ 2527679683 "Yes";
BA_ "GenMsgSendType" BO_ 2527679683 "Cyclic";
BA_ "VFrameFormat" BO_ 2527679683 "ExtendedCAN_FD";
BA_ "GenMsgChkConstant" BO_ 278 172;
BA_ "GenMsgCycleTime" BO_ 278 20;
BA_ "GenMsgILSupport" BO_ 278 "Yes";
BA_ "GenMsgPDUConstants" BO_ 278 "0xac,0xac,0xac,0xac,0xac,0xac,0xac,0xac,0xac,0xac,0xac,0xac,0xac,0xac,0xac,0xac";
BA_ "GenMsgSendType" BO_ 278 "Cyclic";
BA_ "VFrameFormat" BO_ 278 "StandardCAN_FD";
BA_ "GenMsgCycleTime" BO_ 1629 1000;
BA_ "GenMsgDelayTime" BO_ 1629 200;
BA_ "GenMsgILSupport" BO_ 1629 "Yes";
BA_ "GenMsgPDUConstants" BO_ 1629 "0xac,0xb3,0xab,0xeb,0x7a,0xe1,0x3b,0xf7,0x73,0xba,0x7c,0x9e,0x06,0x5f,0x02,0xd9";
BA_ "GenMsgSendType" BO_ 1629 "Cyclic";
BA_ "VFrameFormat" BO_ 1629 "StandardCAN_FD";
BA_ "GenMsgCycleTime" BO_ 253 20;
BA_ "GenMsgILSupport" BO_ 253 "Yes";
BA_ "GenMsgPDUConstants" BO_ 253 "0xb4,0xef,0xf8,0x49,0x1e,0xe5,0xc2,0xc0,0x97,0x19,0x3c,0xc9,0xf1,0x98,0xd6,0x61";
BA_ "GenMsgSendType" BO_ 253 "Cyclic";
BA_ "VFrameFormat" BO_ 253 "StandardCAN_FD";
BA_ "GenMsgCycleTime" BO_ 795 50;
BA_ "GenMsgILSupport" BO_ 795 "Yes";
BA_ "GenMsgPDUConstants" BO_ 795 "0x67,0x8a,0xae,0x22,0x4d,0xd0,0x51,0x80,0x5c,0xb9,0xce,0x1e,0xdf,0x02,0x2d,0xd4";
BA_ "GenMsgSendType" BO_ 795 "Cyclic";
BA_ "VFrameFormat" BO_ 795 "StandardCAN_FD";
BA_ "GenMsgCycleTime" BO_ 2589283617 1000;
BA_ "GenMsgDelayTime" BO_ 2589283617 50;
BA_ "GenMsgILSupport" BO_ 2589283617 "Yes";
BA_ "GenMsgPDUConstants" BO_ 2589283617 "0xad,0xbd,0x5e,0x44,0x5b,0x90,0xb4,0x8d,0x9a,0x74,0xba,0xfa,0x2b,0x91,0xe2,0x89";
BA_ "GenMsgSendType" BO_ 2589283617 "Cyclic";
BA_ "VFrameFormat" BO_ 2589283617 "ExtendedCAN_FD";
BA_ "GenMsgCycleTime" BO_ 2527679668 500;
BA_ "GenMsgDelayTime" BO_ 2527679668 100;
BA_ "GenMsgILSupport" BO_ 2527679668 "Yes";
BA_ "GenMsgSendType" BO_ 2527679668 "Cyclic";
BA_ "VFrameFormat" BO_ 2527679668 "ExtendedCAN_FD";
BA_ "GenMsgCycleTime" BO_ 2527679740 200;
BA_ "GenMsgDelayTime" BO_ 2527679740 50;
BA_ "GenMsgILSupport" BO_ 2527679740 "Yes";
BA_ "GenMsgSendType" BO_ 2527679740 "Cyclic";
BA_ "VFrameFormat" BO_ 2527679740 "ExtendedCAN_FD";
BA_ "GenMsgCycleTime" BO_ 2589283684 1000;
BA_ "GenMsgDelayTime" BO_ 2589283684 200;
BA_ "GenMsgILSupport" BO_ 2589283684 "Yes";
BA_ "GenMsgSendType" BO_ 2589283684 "Cyclic";
BA_ "VFrameFormat" BO_ 2589283684 "ExtendedCAN_FD";
BA_ "MsgType" BO_ 2549875574 "ISO-TP";
BA_ "VFrameFormat" BO_ 2549875574 "ExtendedCAN_FD";
BA_ "MsgType" BO_ 2550006646 "ISO-TP";
BA_ "VFrameFormat" BO_ 2550006646 "ExtendedCAN_FD";
BA_ "GenMsgCycleTime" BO_ 987 100;
BA_ "GenMsgDelayTime" BO_ 987 10;
BA_ "GenMsgILSupport" BO_ 987 "Yes";
BA_ "GenMsgSendType" BO_ 987 "Cyclic";
BA_ "VFrameFormat" BO_ 987 "StandardCAN_FD";
BA_ "GenMsgCycleTime" BO_ 173 10;
BA_ "GenMsgILSupport" BO_ 173 "Yes";
BA_ "GenMsgPDUConstants" BO_ 173 "0x3f,0x69,0x39,0xdc,0x94,0xf9,0x14,0x64,0xd8,0x6a,0x34,0xce,0xa2,0x55,0xb5,0x2c";
BA_ "GenMsgSendType" BO_ 173 "Cyclic";
BA_ "VFrameFormat" BO_ 173 "StandardCAN_FD";
BA_ "GenMsgChkConstant" BO_ 324 227;
BA_ "GenMsgCycleTime" BO_ 324 20;
BA_ "GenMsgILSupport" BO_ 324 "Yes";
BA_ "GenMsgPDUConstants" BO_ 324 "0xe3,0xe3,0xe3,0xe3,0xe3,0xe3,0xe3,0xe3,0xe3,0xe3,0xe3,0xe3,0xe3,0xe3,0xe3,0xe3";
BA_ "GenMsgSendType" BO_ 324 "Cyclic";
BA_ "VFrameFormat" BO_ 324 "StandardCAN_FD";
BA_ "GenMsgCycleTime" BO_ 299 30;
BA_ "GenMsgILSupport" BO_ 299 "Yes";
BA_ "GenMsgPDUConstants" BO_ 299 "0x6a,0x38,0xb4,0x27,0x22,0xef,0xe1,0xbb,0xf8,0x80,0x84,0x49,0xc7,0x9e,0x1e,0x2b";
BA_ "GenMsgSendType" BO_ 299 "Cyclic";
BA_ "VFrameFormat" BO_ 299 "StandardCAN_FD";
BA_ "GenMsgCycleTime" BO_ 1452 100;
BA_ "GenMsgILSupport" BO_ 1452 "Yes";
BA_ "GenMsgSendType" BO_ 1452 "Cyclic";
BA_ "VFrameFormat" BO_ 1452 "StandardCAN_FD";
BA_ "GenMsgCycleTime" BO_ 1385 500;
BA_ "GenMsgDelayTime" BO_ 1385 50;
BA_ "GenMsgILSupport" BO_ 1385 "Yes";
BA_ "GenMsgSendType" BO_ 1385 "Cyclic";
BA_ "VFrameFormat" BO_ 1385 "StandardCAN_FD";
BA_ "GenMsgCycleTime" BO_ 1283 100;
BA_ "GenMsgDelayTime" BO_ 1283 10;
BA_ "GenMsgILSupport" BO_ 1283 "Yes";
BA_ "GenMsgPDUConstants" BO_ 1283 "0xed,0xd6,0x96,0x63,0xa5,0x12,0xd5,0x9a,0x1e,0x0d,0x24,0xcd,0x8c,0xa6,0x2f,0x41";
BA_ "GenMsgSendType" BO_ 1283 "Cyclic";
BA_ "VFrameFormat" BO_ 1283 "StandardCAN_FD";
BA_ "GenMsgCycleTime" BO_ 2463978813 100;
BA_ "GenMsgDelayTime" BO_ 2463978813 10;
BA_ "GenMsgILSupport" BO_ 2463978813 "Yes";
BA_ "GenMsgPDUConstants" BO_ 2463978813 "0x1d,0x82,0x7b,0x79,0xa5,0xee,0x3a,0xb9,0xb7,0xf9,0xe4,0x67,0x7f,0x97,0x11,0xad";
BA_ "GenMsgSendType" BO_ 2463978813 "Cyclic";
BA_ "VFrameFormat" BO_ 2463978813 "ExtendedCAN_FD";
BA_ "GenMsgCycleTime" BO_ 626 100;
BA_ "GenMsgDelayTime" BO_ 626 10;
BA_ "GenMsgILSupport" BO_ 626 "Yes";
BA_ "GenMsgSendType" BO_ 626 "Cyclic";
BA_ "VFrameFormat" BO_ 626 "StandardCAN_FD";
BA_ "GenMsgILSupport" BO_ 268 "Yes";
BA_ "VFrameFormat" BO_ 268 "StandardCAN_FD";
BA_ "GenMsgILSupport" BO_ 23 "Yes";
BA_ "VFrameFormat" BO_ 23 "StandardCAN_FD";
BA_ "GenMsgILSupport" BO_ 25 "Yes";
BA_ "VFrameFormat" BO_ 25 "StandardCAN_FD";
BA_ "GenSigSendType" SG_ 252 ESC_51_CRC "Cyclic";
BA_ "GenSigFuncType" SG_ 252 ESC_51_CRC "CRC-8";
BA_ "GenSigSwitchedByIgnition" SG_ 252 ESC_51_CRC "No";
BA_ "GenSigSendType" SG_ 252 ESC_51_BZ "Cyclic";
BA_ "GenSigFuncType" SG_ 252 ESC_51_BZ "MsgCounter";
BA_ "GenSigSwitchedByIgnition" SG_ 252 ESC_51_BZ "No";
BA_ "GenSigSendType" SG_ 252 ESC_aktBr_Modus "Cyclic";
BA_ "GenSigSwitchedByIgnition" SG_ 252 ESC_aktBr_Modus "No";
BA_ "GenSigSendType" SG_ 252 ESC_Blending_Solldruck "Cyclic";
BA_ "GenSigStartValue" SG_ 252 ESC_Blending_Solldruck 1022;
BA_ "GenSigSwitchedByIgnition" SG_ 252 ESC_Blending_Solldruck "No";
BA_ "Fehlerwert" SG_ 252 ESC_Blending_Solldruck 1023;
BA_ "GenSigSendType" SG_ 252 ESC_aktBr_Volumenstrom "Cyclic";
BA_ "GenSigStartValue" SG_ 252 ESC_aktBr_Volumenstrom 32256;
BA_ "GenSigSwitchedByIgnition" SG_ 252 ESC_aktBr_Volumenstrom "No";
BA_ "GenSigSendType" SG_ 252 ESC_EBKV_Kraftblending_Modus "Cyclic";
BA_ "GenSigSwitchedByIgnition" SG_ 252 ESC_EBKV_Kraftblending_Modus "No";
BA_ "GenSigSendType" SG_ 252 ESC_Bremsdruck_Modell "Cyclic";
BA_ "GenSigStartValue" SG_ 252 ESC_Bremsdruck_Modell 1022;
BA_ "GenSigSwitchedByIgnition" SG_ 252 ESC_Bremsdruck_Modell "No";
BA_ "Fehlerwert" SG_ 252 ESC_Bremsdruck_Modell 1023;
BA_ "GenSigSendType" SG_ 252 ESC_Bremsdruck_02 "Cyclic";
BA_ "GenSigStartValue" SG_ 252 ESC_Bremsdruck_02 100;
BA_ "GenSigSwitchedByIgnition" SG_ 252 ESC_Bremsdruck_02 "No";
BA_ "Fehlerwert" SG_ 252 ESC_Bremsdruck_02 1023;
BA_ "GenSigSendType" SG_ 252 ESC_QBit_Bremsdruck_02 "Cyclic";
BA_ "GenSigStartValue" SG_ 252 ESC_QBit_Bremsdruck_02 1;
BA_ "GenSigSwitchedByIgnition" SG_ 252 ESC_QBit_Bremsdruck_02 "No";
BA_ "GenSigSendType" SG_ 252 ESP_HL_Radgeschw_02 "Cyclic";
BA_ "GenSigStartValue" SG_ 252 ESP_HL_Radgeschw_02 65534;
BA_ "GenSigSwitchedByIgnition" SG_ 252 ESP_HL_Radgeschw_02 "No";
BA_ "Fehlerwert" SG_ 252 ESP_HL_Radgeschw_02 65535;
BA_ "GenSigSendType" SG_ 252 ESP_HR_Radgeschw_02 "Cyclic";
BA_ "GenSigStartValue" SG_ 252 ESP_HR_Radgeschw_02 65534;
BA_ "GenSigSwitchedByIgnition" SG_ 252 ESP_HR_Radgeschw_02 "No";
BA_ "Fehlerwert" SG_ 252 ESP_HR_Radgeschw_02 65535;
BA_ "GenSigSendType" SG_ 252 ESP_VL_Radgeschw_02 "Cyclic";
BA_ "GenSigStartValue" SG_ 252 ESP_VL_Radgeschw_02 65534;
BA_ "GenSigSwitchedByIgnition" SG_ 252 ESP_VL_Radgeschw_02 "No";
BA_ "Fehlerwert" SG_ 252 ESP_VL_Radgeschw_02 65535;
BA_ "GenSigSendType" SG_ 252 ESP_VR_Radgeschw_02 "Cyclic";
BA_ "GenSigStartValue" SG_ 252 ESP_VR_Radgeschw_02 65534;
BA_ "GenSigSwitchedByIgnition" SG_ 252 ESP_VR_Radgeschw_02 "No";
BA_ "Fehlerwert" SG_ 252 ESP_VR_Radgeschw_02 65535;
BA_ "GenSigSendType" SG_ 252 ESP_FZR_uebersteuern "Cyclic";
BA_ "GenSigStartValue" SG_ 252 ESP_FZR_uebersteuern 254;
BA_ "NWM-WakeupAllowed" SG_ 252 ESP_FZR_uebersteuern "Yes";
BA_ "GenSigSwitchedByIgnition" SG_ 252 ESP_FZR_uebersteuern "No";
BA_ "Fehlerwert" SG_ 252 ESP_FZR_uebersteuern 255;
BA_ "GenSigMissingSourceValue" SG_ 252 ESP_FZR_uebersteuern 254;
BA_ "GenSigSendType" SG_ 252 ESP_FZR_untersteuern "Cyclic";
BA_ "GenSigStartValue" SG_ 252 ESP_FZR_untersteuern 254;
BA_ "NWM-WakeupAllowed" SG_ 252 ESP_FZR_untersteuern "Yes";
BA_ "GenSigSwitchedByIgnition" SG_ 252 ESP_FZR_untersteuern "No";
BA_ "Fehlerwert" SG_ 252 ESP_FZR_untersteuern 255;
BA_ "GenSigMissingSourceValue" SG_ 252 ESP_FZR_untersteuern 254;
BA_ "GenSigSendType" SG_ 252 ESC_Anf_Mindestreku "Cyclic";
BA_ "GenSigSwitchedByIgnition" SG_ 252 ESC_Anf_Mindestreku "No";
BA_ "GenSigSendType" SG_ 252 ESC_GMV_aktiv "Cyclic";
BA_ "GenSigSwitchedByIgnition" SG_ 252 ESC_GMV_aktiv "No";
BA_ "GenSigSendType" SG_ 252 ESC_GMV_nicht_verfuegbar "Cyclic";
BA_ "GenSigStartValue" SG_ 252 ESC_GMV_nicht_verfuegbar 1;
BA_ "GenSigSwitchedByIgnition" SG_ 252 ESC_GMV_nicht_verfuegbar "No";
BA_ "GenSigSendType" SG_ 252 ESC_Status_vRef_Stuetzeingriff "Cyclic";
BA_ "GenSigSwitchedByIgnition" SG_ 252 ESC_Status_vRef_Stuetzeingriff "No";
BA_ "GenSigSendType" SG_ 252 FDR_Allradverteilung_aktiv "Cyclic";
BA_ "GenSigSwitchedByIgnition" SG_ 252 FDR_Allradverteilung_aktiv "No";
BA_ "GenSigSendType" SG_ 252 FDR_Anf_Allradbetrieb "Cyclic";
BA_ "GenSigSwitchedByIgnition" SG_ 252 FDR_Anf_Allradbetrieb "No";
BA_ "GenSigSendType" SG_ 252 ESP_HL_Bremsmoment "Cyclic";
BA_ "GenSigStartValue" SG_ 252 ESP_HL_Bremsmoment 254;
BA_ "Fehlerwert" SG_ 252 ESP_HL_Bremsmoment 255;
BA_ "GenSigSendType" SG_ 252 ESP_HR_Bremsmoment "Cyclic";
BA_ "GenSigStartValue" SG_ 252 ESP_HR_Bremsmoment 254;
BA_ "Fehlerwert" SG_ 252 ESP_HR_Bremsmoment 255;
BA_ "GenSigSendType" SG_ 252 ESP_VR_Bremsmoment "Cyclic";
BA_ "GenSigStartValue" SG_ 252 ESP_VR_Bremsmoment 254;
BA_ "Fehlerwert" SG_ 252 ESP_VR_Bremsmoment 255;
BA_ "GenSigSendType" SG_ 252 ESP_VL_Bremsmoment "Cyclic";
BA_ "GenSigStartValue" SG_ 252 ESP_VL_Bremsmoment 254;
BA_ "Fehlerwert" SG_ 252 ESP_VL_Bremsmoment 255;
BA_ "GenSigSendType" SG_ 252 ESP_FDR_uebersteuern "Cyclic";
BA_ "GenSigStartValue" SG_ 252 ESP_FDR_uebersteuern 254;
BA_ "GenSigSwitchedByIgnition" SG_ 252 ESP_FDR_uebersteuern "No";
BA_ "Fehlerwert" SG_ 252 ESP_FDR_uebersteuern 255;
BA_ "GenSigSendType" SG_ 252 ESP_FDR_untersteuern "Cyclic";
BA_ "GenSigStartValue" SG_ 252 ESP_FDR_untersteuern 254;
BA_ "GenSigSwitchedByIgnition" SG_ 252 ESP_FDR_untersteuern "No";
BA_ "Fehlerwert" SG_ 252 ESP_FDR_untersteuern 255;
BA_ "GenSigSendType" SG_ 252 TSMomBegrenzung "Cyclic";
BA_ "GenSigStartValue" SG_ 252 TSMomBegrenzung 4094;
BA_ "GenSigSwitchedByIgnition" SG_ 252 TSMomBegrenzung "No";
BA_ "Fehlerwert" SG_ 252 TSMomBegrenzung 4095;
BA_ "GenSigSendType" SG_ 252 ESC_Allrad_Anteil_max_sek "Cyclic";
BA_ "GenSigStartValue" SG_ 252 ESC_Allrad_Anteil_max_sek 510;
BA_ "GenSigSwitchedByIgnition" SG_ 252 ESC_Allrad_Anteil_max_sek "No";
BA_ "Fehlerwert" SG_ 252 ESC_Allrad_Anteil_max_sek 511;
BA_ "GenSigSendType" SG_ 252 ESC_Allrad_Anteil_min_sek "Cyclic";
BA_ "GenSigStartValue" SG_ 252 ESC_Allrad_Anteil_min_sek 510;
BA_ "GenSigSwitchedByIgnition" SG_ 252 ESC_Allrad_Anteil_min_sek "No";
BA_ "Fehlerwert" SG_ 252 ESC_Allrad_Anteil_min_sek 511;
BA_ "GenSigSendType" SG_ 252 ESC_Status_Eingriff "Cyclic";
BA_ "GenSigSwitchedByIgnition" SG_ 252 ESC_Status_Eingriff "No";
BA_ "GenSigSendType" SG_ 252 ESC_Status_Eingriff_sek "Cyclic";
BA_ "GenSigSwitchedByIgnition" SG_ 252 ESC_Status_Eingriff_sek "No";
BA_ "GenSigSendType" SG_ 252 ESC_MomRad_Eingriff "Cyclic";
BA_ "GenSigStartValue" SG_ 252 ESC_MomRad_Eingriff 8190;
BA_ "GenSigSwitchedByIgnition" SG_ 252 ESC_MomRad_Eingriff "No";
BA_ "Fehlerwert" SG_ 252 ESC_MomRad_Eingriff 8191;
BA_ "GenSigSendType" SG_ 252 ESC_MomRad_Eingriff_sek "Cyclic";
BA_ "GenSigStartValue" SG_ 252 ESC_MomRad_Eingriff_sek 8190;
BA_ "GenSigSwitchedByIgnition" SG_ 252 ESC_MomRad_Eingriff_sek "No";
BA_ "Fehlerwert" SG_ 252 ESC_MomRad_Eingriff_sek 8191;
BA_ "GenSigSendType" SG_ 252 ESC_Achsdrehzahl_Max "Cyclic";
BA_ "GenSigStartValue" SG_ 252 ESC_Achsdrehzahl_Max 16382;
BA_ "GenSigSwitchedByIgnition" SG_ 252 ESC_Achsdrehzahl_Max "No";
BA_ "Fehlerwert" SG_ 252 ESC_Achsdrehzahl_Max 16383;
BA_ "GenSigSendType" SG_ 252 ESC_Achsdrehzahl_Min "Cyclic";
BA_ "GenSigStartValue" SG_ 252 ESC_Achsdrehzahl_Min 16382;
BA_ "GenSigSwitchedByIgnition" SG_ 252 ESC_Achsdrehzahl_Min "No";
BA_ "Fehlerwert" SG_ 252 ESC_Achsdrehzahl_Min 16383;
BA_ "GenSigSendType" SG_ 252 ESC_Achsdrehzahl_Max_sek "Cyclic";
BA_ "GenSigStartValue" SG_ 252 ESC_Achsdrehzahl_Max_sek 16382;
BA_ "GenSigSwitchedByIgnition" SG_ 252 ESC_Achsdrehzahl_Max_sek "No";
BA_ "Fehlerwert" SG_ 252 ESC_Achsdrehzahl_Max_sek 16383;
BA_ "GenSigSendType" SG_ 252 ESC_Achsdrehzahl_Min_sek "Cyclic";
BA_ "GenSigStartValue" SG_ 252 ESC_Achsdrehzahl_Min_sek 16382;
BA_ "GenSigSwitchedByIgnition" SG_ 252 ESC_Achsdrehzahl_Min_sek "No";
BA_ "Fehlerwert" SG_ 252 ESC_Achsdrehzahl_Min_sek 16383;
BA_ "GenSigSendType" SG_ 2463978647 ESP_ACC_LDE "Cyclic";
BA_ "GenSigSwitchedByIgnition" SG_ 2463978647 ESP_ACC_LDE "No";
BA_ "GenSigSendType" SG_ 2463978647 ESP_Allrad_Antrieb "Cyclic";
BA_ "GenSigFuncType" SG_ 2463978647 ESP_Allrad_Antrieb "Constant";
BA_ "GenSigSwitchedByIgnition" SG_ 2463978647 ESP_Allrad_Antrieb "No";
BA_ "GenSigSendType" SG_ 2463978647 ESP_Codierung_ADS "Cyclic";
BA_ "GenSigFuncType" SG_ 2463978647 ESP_Codierung_ADS "Constant";
BA_ "GenSigSwitchedByIgnition" SG_ 2463978647 ESP_Codierung_ADS "No";
BA_ "GenSigSendType" SG_ 2463978647 ESP_RTA_HL "Cyclic";
BA_ "GenSigStartValue" SG_ 2463978647 ESP_RTA_HL 254;
BA_ "GenSigSwitchedByIgnition" SG_ 2463978647 ESP_RTA_HL "No";
BA_ "Fehlerwert" SG_ 2463978647 ESP_RTA_HL 255;
BA_ "GenSigSendType" SG_ 2463978647 ESP_RTA_HR "Cyclic";
BA_ "GenSigStartValue" SG_ 2463978647 ESP_RTA_HR 254;
BA_ "GenSigSwitchedByIgnition" SG_ 2463978647 ESP_RTA_HR "No";
BA_ "Fehlerwert" SG_ 2463978647 ESP_RTA_HR 255;
BA_ "GenSigSendType" SG_ 2463978647 ESP_RTA_VR "Cyclic";
BA_ "GenSigStartValue" SG_ 2463978647 ESP_RTA_VR 254;
BA_ "GenSigSwitchedByIgnition" SG_ 2463978647 ESP_RTA_VR "No";
BA_ "Fehlerwert" SG_ 2463978647 ESP_RTA_VR 255;
BA_ "GenSigSendType" SG_ 2463978647 OBD_Fehler_Radsensor_HL "Cyclic";
BA_ "GenSigSwitchedByIgnition" SG_ 2463978647 OBD_Fehler_Radsensor_HL "No";
BA_ "GenSigSendType" SG_ 2463978647 OBD_Fehler_Radsensor_HR "Cyclic";
BA_ "GenSigSwitchedByIgnition" SG_ 2463978647 OBD_Fehler_Radsensor_HR "No";
BA_ "GenSigSendType" SG_ 2463978647 OBD_Fehler_Radsensor_VL "Cyclic";
BA_ "GenSigSwitchedByIgnition" SG_ 2463978647 OBD_Fehler_Radsensor_VL "No";
BA_ "GenSigSendType" SG_ 2463978647 OBD_Fehler_Radsensor_VR "Cyclic";
BA_ "GenSigSwitchedByIgnition" SG_ 2463978647 OBD_Fehler_Radsensor_VR "No";
BA_ "GenSigSendType" SG_ 2463978647 ESP_Qualifizierung_Antriebsart "Cyclic";
BA_ "GenSigFuncType" SG_ 2463978647 ESP_Qualifizierung_Antriebsart "Constant";
BA_ "GenSigSwitchedByIgnition" SG_ 2463978647 ESP_Qualifizierung_Antriebsart "No";
BA_ "GenSigSendType" SG_ 2463978647 ESP_Offroad_Modus "Cyclic";
BA_ "GenSigSwitchedByIgnition" SG_ 2463978647 ESP_Offroad_Modus "No";
BA_ "GenSigSendType" SG_ 2463978647 ESP_MKB_ausloesbar "Cyclic";
BA_ "GenSigSwitchedByIgnition" SG_ 2463978647 ESP_MKB_ausloesbar "No";
BA_ "GenSigSendType" SG_ 2463978647 ESP_Stat_FallBack_eBKV "Cyclic";
BA_ "GenSigSwitchedByIgnition" SG_ 2463978647 ESP_Stat_FallBack_eBKV "No";
BA_ "GenSigSendType" SG_ 2463978647 ESP_CM_Variante "Cyclic";
BA_ "GenSigSwitchedByIgnition" SG_ 2463978647 ESP_CM_Variante "No";
BA_ "GenSigSendType" SG_ 2463978647 ESP_OBD_Status "Cyclic";
BA_ "GenSigSwitchedByIgnition" SG_ 2463978647 ESP_OBD_Status "No";
BA_ "GenSigSendType" SG_ 2463978647 ESP_Rollenmodus_Deaktivieren "Cyclic";
BA_ "GenSigSwitchedByIgnition" SG_ 2463978647 ESP_Rollenmodus_Deaktivieren "No";
BA_ "GenSigSendType" SG_ 2463978647 ESP_nachtr_Stopp_Anf "Cyclic";
BA_ "GenSigSwitchedByIgnition" SG_ 2463978647 ESP_nachtr_Stopp_Anf "No";
BA_ "GenSigSendType" SG_ 2527679683 ESC_ASM_Ereignis "OnChange";
BA_ "GenSigSwitchedByIgnition" SG_ 2527679683 ESC_ASM_Ereignis "No";
BA_ "GenSigSendType" SG_ 2527679683 ESC_ASM_Zeitstempel "OnChange";
BA_ "GenSigStartValue" SG_ 2527679683 ESC_ASM_Zeitstempel 255;
BA_ "GenSigSwitchedByIgnition" SG_ 2527679683 ESC_ASM_Zeitstempel "No";
BA_ "GenSigSendType" SG_ 2527679683 ESC_ASM_Data_1 "Cyclic";
BA_ "GenSigSwitchedByIgnition" SG_ 2527679683 ESC_ASM_Data_1 "No";
BA_ "GenSigSendType" SG_ 2527679683 ESC_ASM_Data_2 "Cyclic";
BA_ "GenSigSwitchedByIgnition" SG_ 2527679683 ESC_ASM_Data_2 "No";
BA_ "GenSigSendType" SG_ 2527679683 ESC_ASM_Data_3 "Cyclic";
BA_ "GenSigSwitchedByIgnition" SG_ 2527679683 ESC_ASM_Data_3 "No";
BA_ "GenSigSendType" SG_ 2527679683 ESC_ASM_Data_4 "Cyclic";
BA_ "GenSigSwitchedByIgnition" SG_ 2527679683 ESC_ASM_Data_4 "No";
BA_ "GenSigSendType" SG_ 2527679683 ESC_ASM_Data_5 "Cyclic";
BA_ "GenSigSwitchedByIgnition" SG_ 2527679683 ESC_ASM_Data_5 "No";
BA_ "GenSigSendType" SG_ 2527679683 ESC_ASM_Data_6 "Cyclic";
BA_ "GenSigSwitchedByIgnition" SG_ 2527679683 ESC_ASM_Data_6 "No";
BA_ "GenSigSendType" SG_ 278 ESP_10_CRC "Cyclic";
BA_ "GenSigFuncType" SG_ 278 ESP_10_CRC "CRC-8";
BA_ "GenSigSwitchedByIgnition" SG_ 278 ESP_10_CRC "No";
BA_ "GenSigSendType" SG_ 278 ESP_10_BZ "Cyclic";
BA_ "GenSigFuncType" SG_ 278 ESP_10_BZ "MsgCounter";
BA_ "GenSigSwitchedByIgnition" SG_ 278 ESP_10_BZ "No";
BA_ "GenSigSendType" SG_ 278 ESP_QBit_Wegimpuls_VL "Cyclic";
BA_ "GenSigStartValue" SG_ 278 ESP_QBit_Wegimpuls_VL 1;
BA_ "GenSigSwitchedByIgnition" SG_ 278 ESP_QBit_Wegimpuls_VL "No";
BA_ "GenSigSendType" SG_ 278 ESP_QBit_Wegimpuls_VR "Cyclic";
BA_ "GenSigStartValue" SG_ 278 ESP_QBit_Wegimpuls_VR 1;
BA_ "GenSigSwitchedByIgnition" SG_ 278 ESP_QBit_Wegimpuls_VR "No";
BA_ "GenSigSendType" SG_ 278 ESP_QBit_Wegimpuls_HL "Cyclic";
BA_ "GenSigStartValue" SG_ 278 ESP_QBit_Wegimpuls_HL 1;
BA_ "GenSigSwitchedByIgnition" SG_ 278 ESP_QBit_Wegimpuls_HL "No";
BA_ "GenSigSendType" SG_ 278 ESP_QBit_Wegimpuls_HR "Cyclic";
BA_ "GenSigStartValue" SG_ 278 ESP_QBit_Wegimpuls_HR 1;
BA_ "GenSigSwitchedByIgnition" SG_ 278 ESP_QBit_Wegimpuls_HR "No";
BA_ "GenSigSendType" SG_ 278 ESP_Wegimpuls_VL "Cyclic";
BA_ "GenSigStartValue" SG_ 278 ESP_Wegimpuls_VL 1021;
BA_ "GenSigSwitchedByIgnition" SG_ 278 ESP_Wegimpuls_VL "No";
BA_ "Fehlerwert" SG_ 278 ESP_Wegimpuls_VL 1023;
BA_ "GenSigSendType" SG_ 278 ESP_Wegimpuls_VR "Cyclic";
BA_ "GenSigStartValue" SG_ 278 ESP_Wegimpuls_VR 1021;
BA_ "GenSigSwitchedByIgnition" SG_ 278 ESP_Wegimpuls_VR "No";
BA_ "Fehlerwert" SG_ 278 ESP_Wegimpuls_VR 1023;
BA_ "GenSigSendType" SG_ 278 ESP_Wegimpuls_HL "Cyclic";
BA_ "GenSigStartValue" SG_ 278 ESP_Wegimpuls_HL 1021;
BA_ "GenSigSwitchedByIgnition" SG_ 278 ESP_Wegimpuls_HL "No";
BA_ "Fehlerwert" SG_ 278 ESP_Wegimpuls_HL 1023;
BA_ "GenSigSendType" SG_ 278 ESP_Wegimpuls_HR "Cyclic";
BA_ "GenSigStartValue" SG_ 278 ESP_Wegimpuls_HR 1021;
BA_ "GenSigSwitchedByIgnition" SG_ 278 ESP_Wegimpuls_HR "No";
BA_ "Fehlerwert" SG_ 278 ESP_Wegimpuls_HR 1023;
BA_ "GenSigSendType" SG_ 278 ESP_VL_Fahrtrichtung "Cyclic";
BA_ "GenSigStartValue" SG_ 278 ESP_VL_Fahrtrichtung 2;
BA_ "GenSigSwitchedByIgnition" SG_ 278 ESP_VL_Fahrtrichtung "No";
BA_ "GenSigSendType" SG_ 278 ESP_VR_Fahrtrichtung "Cyclic";
BA_ "GenSigStartValue" SG_ 278 ESP_VR_Fahrtrichtung 2;
BA_ "GenSigSwitchedByIgnition" SG_ 278 ESP_VR_Fahrtrichtung "No";
BA_ "GenSigSendType" SG_ 278 ESP_HL_Fahrtrichtung "Cyclic";
BA_ "GenSigStartValue" SG_ 278 ESP_HL_Fahrtrichtung 2;
BA_ "GenSigSwitchedByIgnition" SG_ 278 ESP_HL_Fahrtrichtung "No";
BA_ "GenSigSendType" SG_ 278 ESP_HR_Fahrtrichtung "Cyclic";
BA_ "GenSigStartValue" SG_ 278 ESP_HR_Fahrtrichtung 2;
BA_ "GenSigSwitchedByIgnition" SG_ 278 ESP_HR_Fahrtrichtung "No";
BA_ "GenSigSendType" SG_ 1629 ESP_20_CRC "Cyclic";
BA_ "GenSigFuncType" SG_ 1629 ESP_20_CRC "CRC-8";
BA_ "GenSigSwitchedByIgnition" SG_ 1629 ESP_20_CRC "No";
BA_ "GenSigSendType" SG_ 1629 ESP_20_BZ "Cyclic";
BA_ "GenSigFuncType" SG_ 1629 ESP_20_BZ "MsgCounter";
BA_ "GenSigSwitchedByIgnition" SG_ 1629 ESP_20_BZ "No";
BA_ "GenSigSendType" SG_ 1629 BR_Systemart "Cyclic";
BA_ "GenSigFuncType" SG_ 1629 BR_Systemart "Constant";
BA_ "GenSigSwitchedByIgnition" SG_ 1629 BR_Systemart "No";
BA_ "GenSigSendType" SG_ 1629 ESP_SpannungsAnf_02 "OnChange";
BA_ "GenSigSwitchedByIgnition" SG_ 1629 ESP_SpannungsAnf_02 "No";
BA_ "GenSigSendType" SG_ 1629 ESP_Zaehnezahl "Cyclic";
BA_ "GenSigFuncType" SG_ 1629 ESP_Zaehnezahl "Constant";
BA_ "GenSigSwitchedByIgnition" SG_ 1629 ESP_Zaehnezahl "No";
BA_ "GenSigSendType" SG_ 1629 ESP_Charisma_FahrPr "OnChange";
BA_ "GenSigSwitchedByIgnition" SG_ 1629 ESP_Charisma_FahrPr "No";
BA_ "GenSigSendType" SG_ 1629 ESP_Charisma_Status "OnChange";
BA_ "GenSigSwitchedByIgnition" SG_ 1629 ESP_Charisma_Status "No";
BA_ "GenSigSendType" SG_ 1629 ESP_Wiederstart_Anz_01 "OnChange";
BA_ "GenSigSwitchedByIgnition" SG_ 1629 ESP_Wiederstart_Anz_01 "No";
BA_ "GenSigSendType" SG_ 1629 ESP_Wiederstart_Anz_02 "OnChange";
BA_ "GenSigSwitchedByIgnition" SG_ 1629 ESP_Wiederstart_Anz_02 "No";
BA_ "GenSigSendType" SG_ 1629 ESP_Wiederstart_Anz_03 "OnChange";
BA_ "GenSigSwitchedByIgnition" SG_ 1629 ESP_Wiederstart_Anz_03 "No";
BA_ "GenSigSendType" SG_ 1629 ESP_Wiederstart_Anz_04 "OnChange";
BA_ "GenSigSwitchedByIgnition" SG_ 1629 ESP_Wiederstart_Anz_04 "No";
BA_ "GenSigSendType" SG_ 1629 ESP_Stoppverbot_Anz_01 "OnChange";
BA_ "GenSigSwitchedByIgnition" SG_ 1629 ESP_Stoppverbot_Anz_01 "No";
BA_ "GenSigSendType" SG_ 1629 ESP_Stoppverbot_Anz_02 "OnChange";
BA_ "GenSigSwitchedByIgnition" SG_ 1629 ESP_Stoppverbot_Anz_02 "No";
BA_ "GenSigSendType" SG_ 1629 ESP_Stoppverbot_Anz_03 "OnChange";
BA_ "GenSigSwitchedByIgnition" SG_ 1629 ESP_Stoppverbot_Anz_03 "No";
BA_ "GenSigSendType" SG_ 1629 ESP_Stoppverbot_Anz_04 "OnChange";
BA_ "GenSigSwitchedByIgnition" SG_ 1629 ESP_Stoppverbot_Anz_04 "No";
BA_ "GenSigSendType" SG_ 1629 ESP_Stoppverbot_Anz_05 "OnChange";
BA_ "GenSigSwitchedByIgnition" SG_ 1629 ESP_Stoppverbot_Anz_05 "No";
BA_ "GenSigSendType" SG_ 1629 ESP_Stoppverbot_Anz_06 "OnChange";
BA_ "GenSigSwitchedByIgnition" SG_ 1629 ESP_Stoppverbot_Anz_06 "No";
BA_ "GenSigSendType" SG_ 1629 ESP_Stoppverbot_Anz_07 "OnChange";
BA_ "GenSigSwitchedByIgnition" SG_ 1629 ESP_Stoppverbot_Anz_07 "No";
BA_ "GenSigSendType" SG_ 1629 ESP_Stoppverbot_Anz_Std "OnChange";
BA_ "GenSigSwitchedByIgnition" SG_ 1629 ESP_Stoppverbot_Anz_Std "No";
BA_ "GenSigSendType" SG_ 1629 ESP_Dachrelingsensor "Cyclic";
BA_ "GenSigSwitchedByIgnition" SG_ 1629 ESP_Dachrelingsensor "No";
BA_ "Fehlerwert" SG_ 1629 ESP_Dachrelingsensor 3;
BA_ "GenSigSendType" SG_ 1629 ESP_Stoppverbot_Anz_08 "OnChange";
BA_ "GenSigSwitchedByIgnition" SG_ 1629 ESP_Stoppverbot_Anz_08 "No";
BA_ "GenSigSendType" SG_ 1629 HDC_Charisma_FahrPr "OnChange";
BA_ "GenSigSwitchedByIgnition" SG_ 1629 HDC_Charisma_FahrPr "No";
BA_ "GenSigSendType" SG_ 1629 HDC_Charisma_Status "OnChange";
BA_ "GenSigSwitchedByIgnition" SG_ 1629 HDC_Charisma_Status "No";
BA_ "GenSigSendType" SG_ 1629 BR_QBit_Reifenumfang "Cyclic";
BA_ "GenSigStartValue" SG_ 1629 BR_QBit_Reifenumfang 1;
BA_ "GenSigSwitchedByIgnition" SG_ 1629 BR_QBit_Reifenumfang "No";
BA_ "GenSigSendType" SG_ 1629 BR_Reifenumfang "Cyclic";
BA_ "GenSigSwitchedByIgnition" SG_ 1629 BR_Reifenumfang "No";
BA_ "GenSigSendType" SG_ 253 ESP_21_CRC "Cyclic";
BA_ "GenSigFuncType" SG_ 253 ESP_21_CRC "CRC-8";
BA_ "GenSigSwitchedByIgnition" SG_ 253 ESP_21_CRC "No";
BA_ "GenSigSendType" SG_ 253 ESP_21_BZ "Cyclic";
BA_ "GenSigFuncType" SG_ 253 ESP_21_BZ "MsgCounter";
BA_ "GenSigSwitchedByIgnition" SG_ 253 ESP_21_BZ "No";
BA_ "GenSigSendType" SG_ 253 BR_Eingriffsmoment "Cyclic";
BA_ "GenSigStartValue" SG_ 253 BR_Eingriffsmoment 1022;
BA_ "GenSigSwitchedByIgnition" SG_ 253 BR_Eingriffsmoment "No";
BA_ "Fehlerwert" SG_ 253 BR_Eingriffsmoment 1023;
BA_ "GenSigSendType" SG_ 253 ESP_PLA_Bremseingriff "Cyclic";
BA_ "GenSigSwitchedByIgnition" SG_ 253 ESP_PLA_Bremseingriff "No";
BA_ "GenSigSendType" SG_ 253 ESP_Diagnose "Cyclic";
BA_ "GenSigSwitchedByIgnition" SG_ 253 ESP_Diagnose "No";
BA_ "GenSigSendType" SG_ 253 ESC_Reku_Freigabe "Cyclic";
BA_ "GenSigSwitchedByIgnition" SG_ 253 ESC_Reku_Freigabe "No";
BA_ "GenSigSendType" SG_ 253 ESC_v_Signal_Qualifier_High_Low "Cyclic";
BA_ "GenSigStartValue" SG_ 253 ESC_v_Signal_Qualifier_High_Low 6;
BA_ "GenSigSwitchedByIgnition" SG_ 253 ESC_v_Signal_Qualifier_High_Low "No";
BA_ "Fehlerwert" SG_ 253 ESC_v_Signal_Qualifier_High_Low 7;
BA_ "GenSigSendType" SG_ 253 ESP_Vorsteuerung "Cyclic";
BA_ "GenSigSwitchedByIgnition" SG_ 253 ESP_Vorsteuerung "No";
BA_ "GenSigSendType" SG_ 253 ESP_AWV3_Brems_aktiv "Cyclic";
BA_ "GenSigSwitchedByIgnition" SG_ 253 ESP_AWV3_Brems_aktiv "No";
BA_ "GenSigSendType" SG_ 253 OBD_Schlechtweg "Cyclic";
BA_ "GenSigSwitchedByIgnition" SG_ 253 OBD_Schlechtweg "No";
BA_ "GenSigSendType" SG_ 253 OBD_QBit_Schlechtweg "Cyclic";
BA_ "GenSigStartValue" SG_ 253 OBD_QBit_Schlechtweg 1;
BA_ "GenSigSwitchedByIgnition" SG_ 253 OBD_QBit_Schlechtweg "No";
BA_ "GenSigSendType" SG_ 253 ESP_v_Signal "Cyclic";
BA_ "GenSigStartValue" SG_ 253 ESP_v_Signal 65534;
BA_ "GenSigSwitchedByIgnition" SG_ 253 ESP_v_Signal "No";
BA_ "Fehlerwert" SG_ 253 ESP_v_Signal 65535;
BA_ "GenSigMissingSourceValue" SG_ 253 ESP_v_Signal 65534;
BA_ "GenSigSendType" SG_ 253 ASR_Tastung_passiv "Cyclic";
BA_ "GenSigSwitchedByIgnition" SG_ 253 ASR_Tastung_passiv "No";
BA_ "GenSigSendType" SG_ 253 ESP_Tastung_passiv "Cyclic";
BA_ "GenSigSwitchedByIgnition" SG_ 253 ESP_Tastung_passiv "No";
BA_ "GenSigSendType" SG_ 253 ESP_Systemstatus "Cyclic";
BA_ "GenSigSwitchedByIgnition" SG_ 253 ESP_Systemstatus "No";
BA_ "GenSigSendType" SG_ 253 ASR_Schalteingriff "Cyclic";
BA_ "GenSigSwitchedByIgnition" SG_ 253 ASR_Schalteingriff "No";
BA_ "GenSigSendType" SG_ 253 ESP_Haltebestaetigung "Cyclic";
BA_ "GenSigSwitchedByIgnition" SG_ 253 ESP_Haltebestaetigung "No";
BA_ "GenSigSendType" SG_ 253 ESP_MKB_Abbruch_Geschw "Cyclic";
BA_ "GenSigSwitchedByIgnition" SG_ 253 ESP_MKB_Abbruch_Geschw "No";
BA_ "GenSigSendType" SG_ 253 ESP_QBit_v_Signal "Cyclic";
BA_ "GenSigStartValue" SG_ 253 ESP_QBit_v_Signal 1;
BA_ "GenSigSwitchedByIgnition" SG_ 253 ESP_QBit_v_Signal "No";
BA_ "GenSigSendType" SG_ 253 ABS_Bremsung "Cyclic";
BA_ "GenSigSwitchedByIgnition" SG_ 253 ABS_Bremsung "No";
BA_ "GenSigSendType" SG_ 253 ASR_Anf "Cyclic";
BA_ "GenSigSwitchedByIgnition" SG_ 253 ASR_Anf "No";
BA_ "GenSigSendType" SG_ 253 MSR_Anf "Cyclic";
BA_ "GenSigSwitchedByIgnition" SG_ 253 MSR_Anf "No";
BA_ "GenSigSendType" SG_ 253 EBV_Eingriff "Cyclic";
BA_ "GenSigSwitchedByIgnition" SG_ 253 EBV_Eingriff "No";
BA_ "GenSigSendType" SG_ 253 EDS_Eingriff "Cyclic";
BA_ "GenSigSwitchedByIgnition" SG_ 253 EDS_Eingriff "No";
BA_ "GenSigSendType" SG_ 253 ESP_Eingriff "Cyclic";
BA_ "GenSigSwitchedByIgnition" SG_ 253 ESP_Eingriff "No";
BA_ "GenSigSendType" SG_ 253 ESP_ASP "Cyclic";
BA_ "GenSigSwitchedByIgnition" SG_ 253 ESP_ASP "No";
BA_ "GenSigSendType" SG_ 253 ESP_Anhaltevorgang_ACC_aktiv "Cyclic";
BA_ "GenSigSwitchedByIgnition" SG_ 253 ESP_Anhaltevorgang_ACC_aktiv "No";
BA_ "GenSigSendType" SG_ 795 ESP_24_CRC "Cyclic";
BA_ "GenSigFuncType" SG_ 795 ESP_24_CRC "CRC-8";
BA_ "GenSigSwitchedByIgnition" SG_ 795 ESP_24_CRC "No";
BA_ "GenSigSendType" SG_ 795 ESP_24_BZ "Cyclic";
BA_ "GenSigFuncType" SG_ 795 ESP_24_BZ "MsgCounter";
BA_ "GenSigSwitchedByIgnition" SG_ 795 ESP_24_BZ "No";
BA_ "GenSigSendType" SG_ 795 ESP_Lampe "Cyclic";
BA_ "GenSigStartValue" SG_ 795 ESP_Lampe 1;
BA_ "GenSigSwitchedByIgnition" SG_ 795 ESP_Lampe "No";
BA_ "GenSigSendType" SG_ 795 ABS_Lampe "Cyclic";
BA_ "GenSigStartValue" SG_ 795 ABS_Lampe 1;
BA_ "GenSigSwitchedByIgnition" SG_ 795 ABS_Lampe "No";
BA_ "GenSigSendType" SG_ 795 BK_Lampe_02 "Cyclic";
BA_ "GenSigStartValue" SG_ 795 BK_Lampe_02 1;
BA_ "GenSigSwitchedByIgnition" SG_ 795 BK_Lampe_02 "No";
BA_ "GenSigSendType" SG_ 795 TC_Lampe "Cyclic";
BA_ "GenSigSwitchedByIgnition" SG_ 795 TC_Lampe "No";
BA_ "GenSigSendType" SG_ 795 ESP_m_Raddrehz "Cyclic";
BA_ "GenSigStartValue" SG_ 795 ESP_m_Raddrehz 32766;
BA_ "GenSigSwitchedByIgnition" SG_ 795 ESP_m_Raddrehz "No";
BA_ "Fehlerwert" SG_ 795 ESP_m_Raddrehz 32767;
BA_ "GenSigSendType" SG_ 795 ESP_Textanzeigen_03 "Cyclic";
BA_ "GenSigSwitchedByIgnition" SG_ 795 ESP_Textanzeigen_03 "No";
BA_ "GenSigSendType" SG_ 795 ESP_Meldungen "Cyclic";
BA_ "GenSigSwitchedByIgnition" SG_ 795 ESP_Meldungen "No";
BA_ "GenSigSendType" SG_ 795 ESP_Wegimp_VA "Cyclic";
BA_ "GenSigSwitchedByIgnition" SG_ 795 ESP_Wegimp_VA "No";
BA_ "GenSigSendType" SG_ 795 ESP_Fehlerstatus_Wegimp "Cyclic";
BA_ "GenSigSwitchedByIgnition" SG_ 795 ESP_Fehlerstatus_Wegimp "No";
BA_ "GenSigSendType" SG_ 795 ESP_Wegimp_Ueberlauf "Cyclic";
BA_ "GenSigSwitchedByIgnition" SG_ 795 ESP_Wegimp_Ueberlauf "No";
BA_ "GenSigSendType" SG_ 795 ESP_QBit_Wegimp_VA "Cyclic";
BA_ "GenSigStartValue" SG_ 795 ESP_QBit_Wegimp_VA 1;
BA_ "GenSigSwitchedByIgnition" SG_ 795 ESP_QBit_Wegimp_VA "No";
BA_ "GenSigSendType" SG_ 795 ESP_HDC_FktLampe "Cyclic";
BA_ "GenSigSwitchedByIgnition" SG_ 795 ESP_HDC_FktLampe "No";
BA_ "GenSigSendType" SG_ 795 ESP_Off_Lampe "Cyclic";
BA_ "GenSigSwitchedByIgnition" SG_ 795 ESP_Off_Lampe "No";
BA_ "GenSigSendType" SG_ 795 ESP_HDC_Regelgeschw "Cyclic";
BA_ "GenSigStartValue" SG_ 795 ESP_HDC_Regelgeschw 126;
BA_ "GenSigSwitchedByIgnition" SG_ 795 ESP_HDC_Regelgeschw "No";
BA_ "Fehlerwert" SG_ 795 ESP_HDC_Regelgeschw 127;
BA_ "GenSigSendType" SG_ 795 ESP_BKV_Warnung "Cyclic";
BA_ "GenSigSwitchedByIgnition" SG_ 795 ESP_BKV_Warnung "No";
BA_ "GenSigSendType" SG_ 2589283617 ESP_30_CRC "Cyclic";
BA_ "GenSigFuncType" SG_ 2589283617 ESP_30_CRC "CRC-8";
BA_ "GenSigSwitchedByIgnition" SG_ 2589283617 ESP_30_CRC "No";
BA_ "GenSigSendType" SG_ 2589283617 ESP_30_BZ "Cyclic";
BA_ "GenSigFuncType" SG_ 2589283617 ESP_30_BZ "MsgCounter";
BA_ "GenSigSwitchedByIgnition" SG_ 2589283617 ESP_30_BZ "No";
BA_ "GenSigSendType" SG_ 2589283617 EDS_Charisma_FahrPr "OnChange";
BA_ "GenSigSwitchedByIgnition" SG_ 2589283617 EDS_Charisma_FahrPr "No";
BA_ "GenSigSendType" SG_ 2589283617 EDS_Charisma_Status "OnChange";
BA_ "GenSigSwitchedByIgnition" SG_ 2589283617 EDS_Charisma_Status "No";
BA_ "GenSigSendType" SG_ 2589283617 HHC_Charisma_Status "OnChange";
BA_ "GenSigSwitchedByIgnition" SG_ 2589283617 HHC_Charisma_Status "No";
BA_ "GenSigSendType" SG_ 2589283617 HHC_Charisma_FahrPr "OnChange";
BA_ "GenSigSwitchedByIgnition" SG_ 2589283617 HHC_Charisma_FahrPr "No";
BA_ "GenSigSendType" SG_ 2589283617 RLE_Anzeigen "Cyclic";
BA_ "GenSigSwitchedByIgnition" SG_ 2589283617 RLE_Anzeigen "No";
BA_ "GenSigSendType" SG_ 2589283617 ESC_Lernfreigabe_Abrollumfang "OnChange";
BA_ "GenSigSwitchedByIgnition" SG_ 2589283617 ESC_Lernfreigabe_Abrollumfang "No";
BA_ "GenSigSendType" SG_ 2589283617 ESC_Texte_eBKV_Betaetigung "OnChange";
BA_ "GenSigSwitchedByIgnition" SG_ 2589283617 ESC_Texte_eBKV_Betaetigung "No";
BA_ "GenSigSendType" SG_ 2589283617 ESC_MBK_Meldungen "OnChange";
BA_ "GenSigSwitchedByIgnition" SG_ 2589283617 ESC_MBK_Meldungen "No";
BA_ "GenSigSendType" SG_ 2589283617 ESC_Anf_KL "Cyclic";
BA_ "GenSigSwitchedByIgnition" SG_ 2589283617 ESC_Anf_KL "No";
BA_ "GenSigSendType" SG_ 2589283617 ESC_Anf_KV "Cyclic";
BA_ "GenSigSwitchedByIgnition" SG_ 2589283617 ESC_Anf_KV "No";
BA_ "GenSigSendType" SG_ 2589283617 ESC_FBA_Meldungen "OnChange";
BA_ "GenSigSwitchedByIgnition" SG_ 2589283617 ESC_FBA_Meldungen "No";
BA_ "GenSigSendType" SG_ 2589283617 DBK_Fahrerwarnung "Cyclic";
BA_ "GenSigSwitchedByIgnition" SG_ 2589283617 DBK_Fahrerwarnung "No";
BA_ "GenSigSendType" SG_ 2527679668 eTM_Ventil1_Status "OnChange";
BA_ "GenSigStartValue" SG_ 2527679668 eTM_Ventil1_Status 6;
BA_ "GenSigSwitchedByIgnition" SG_ 2527679668 eTM_Ventil1_Status "No";
BA_ "Fehlerwert" SG_ 2527679668 eTM_Ventil1_Status 7;
BA_ "GenSigSendType" SG_ 2527679668 eTM_Ventil2_Status "OnChange";
BA_ "GenSigStartValue" SG_ 2527679668 eTM_Ventil2_Status 6;
BA_ "GenSigSwitchedByIgnition" SG_ 2527679668 eTM_Ventil2_Status "No";
BA_ "Fehlerwert" SG_ 2527679668 eTM_Ventil2_Status 7;
BA_ "GenSigSendType" SG_ 2527679668 eTM_Ventil3_Status "OnChange";
BA_ "GenSigStartValue" SG_ 2527679668 eTM_Ventil3_Status 6;
BA_ "GenSigSwitchedByIgnition" SG_ 2527679668 eTM_Ventil3_Status "No";
BA_ "Fehlerwert" SG_ 2527679668 eTM_Ventil3_Status 7;
BA_ "GenSigSendType" SG_ 2527679668 eTM_Pumpe3_Status "OnChange";
BA_ "GenSigStartValue" SG_ 2527679668 eTM_Pumpe3_Status 14;
BA_ "GenSigSwitchedByIgnition" SG_ 2527679668 eTM_Pumpe3_Status "No";
BA_ "Fehlerwert" SG_ 2527679668 eTM_Pumpe3_Status 15;
BA_ "GenSigSendType" SG_ 2527679668 eTM_BMS_Pumpe1_SollAnsteuerung "Cyclic";
BA_ "GenSigStartValue" SG_ 2527679668 eTM_BMS_Pumpe1_SollAnsteuerung 14;
BA_ "GenSigSwitchedByIgnition" SG_ 2527679668 eTM_BMS_Pumpe1_SollAnsteuerung "No";
BA_ "Fehlerwert" SG_ 2527679668 eTM_BMS_Pumpe1_SollAnsteuerung 15;
BA_ "GenSigSendType" SG_ 2527679668 eTM_Pumpe2_Volumenstrom "Cyclic";
BA_ "GenSigStartValue" SG_ 2527679668 eTM_Pumpe2_Volumenstrom 62;
BA_ "GenSigSwitchedByIgnition" SG_ 2527679668 eTM_Pumpe2_Volumenstrom "No";
BA_ "Fehlerwert" SG_ 2527679668 eTM_Pumpe2_Volumenstrom 63;
BA_ "GenSigSendType" SG_ 2527679668 eTM_BMS_Ventil2_Befuellung "Cyclic";
BA_ "GenSigSwitchedByIgnition" SG_ 2527679668 eTM_BMS_Ventil2_Befuellung "No";
BA_ "GenSigSendType" SG_ 2527679668 eTM_Pumpe1_Volumenstrom "Cyclic";
BA_ "GenSigStartValue" SG_ 2527679668 eTM_Pumpe1_Volumenstrom 62;
BA_ "GenSigSwitchedByIgnition" SG_ 2527679668 eTM_Pumpe1_Volumenstrom "No";
BA_ "Fehlerwert" SG_ 2527679668 eTM_Pumpe1_Volumenstrom 63;
BA_ "GenSigSendType" SG_ 2527679668 eTM_BMS_Pumpe1_Befuellung "Cyclic";
BA_ "GenSigSwitchedByIgnition" SG_ 2527679668 eTM_BMS_Pumpe1_Befuellung "No";
BA_ "GenSigSendType" SG_ 2527679668 eTM_BMS_Ventil1_Befuellung "Cyclic";
BA_ "GenSigSwitchedByIgnition" SG_ 2527679668 eTM_BMS_Ventil1_Befuellung "No";
BA_ "GenSigSendType" SG_ 2527679668 eTM_Pumpe1_Status "OnChange";
BA_ "GenSigStartValue" SG_ 2527679668 eTM_Pumpe1_Status 14;
BA_ "GenSigSwitchedByIgnition" SG_ 2527679668 eTM_Pumpe1_Status "No";
BA_ "Fehlerwert" SG_ 2527679668 eTM_Pumpe1_Status 15;
BA_ "GenSigSendType" SG_ 2527679668 eTM_Pumpe2_Status "OnChange";
BA_ "GenSigStartValue" SG_ 2527679668 eTM_Pumpe2_Status 14;
BA_ "GenSigSwitchedByIgnition" SG_ 2527679668 eTM_Pumpe2_Status "No";
BA_ "Fehlerwert" SG_ 2527679668 eTM_Pumpe2_Status 15;
BA_ "GenSigSendType" SG_ 2527679668 eTM_Temperatur_1 "Cyclic";
BA_ "GenSigStartValue" SG_ 2527679668 eTM_Temperatur_1 254;
BA_ "GenSigSwitchedByIgnition" SG_ 2527679668 eTM_Temperatur_1 "No";
BA_ "Fehlerwert" SG_ 2527679668 eTM_Temperatur_1 255;
BA_ "GenSigSendType" SG_ 2527679668 eTM_Temperatur_2 "Cyclic";
BA_ "GenSigStartValue" SG_ 2527679668 eTM_Temperatur_2 254;
BA_ "GenSigSwitchedByIgnition" SG_ 2527679668 eTM_Temperatur_2 "No";
BA_ "Fehlerwert" SG_ 2527679668 eTM_Temperatur_2 255;
BA_ "GenSigSendType" SG_ 2527679740 KBI_aktive_Laengsfunktion_02 "OnChange";
BA_ "GenSigSendType" SG_ 2527679740 KBI_Anzeigestatus_GRA "OnChange";
BA_ "GenSigSwitchedByIgnition" SG_ 2527679740 KBI_Anzeigestatus_GRA "No";
BA_ "Fehlerwert" SG_ 2527679740 KBI_Anzeigestatus_GRA 3;
BA_ "GenSigSendType" SG_ 2527679740 KBI_Anzeigestatus_LIM "OnChange";
BA_ "GenSigSwitchedByIgnition" SG_ 2527679740 KBI_Anzeigestatus_LIM "No";
BA_ "Fehlerwert" SG_ 2527679740 KBI_Anzeigestatus_LIM 3;
BA_ "GenSigSendType" SG_ 2527679740 KBI_Anzeigestatus_ACC "OnChange";
BA_ "GenSigSwitchedByIgnition" SG_ 2527679740 KBI_Anzeigestatus_ACC "No";
BA_ "GenSigSendType" SG_ 2527679740 KBI_Konsistenz_ACC "OnChange";
BA_ "GenSigSwitchedByIgnition" SG_ 2527679740 KBI_Konsistenz_ACC "No";
BA_ "GenSigSendType" SG_ 2527679740 KBI_Fehler_Anzeige_ACC "OnChange";
BA_ "GenSigSwitchedByIgnition" SG_ 2527679740 KBI_Fehler_Anzeige_ACC "No";
BA_ "GenSigSendType" SG_ 2589283684 GRA_FoD_Status "OnChange";
BA_ "GenSigSwitchedByIgnition" SG_ 2589283684 GRA_FoD_Status "No";
BA_ "GenSigSendType" SG_ 2589283684 FoD_Transmission_Info "OnChange";
BA_ "GenSigSwitchedByIgnition" SG_ 2589283684 FoD_Transmission_Info "No";
BA_ "GenSigSendType" SG_ 2549875574 FoD_MO_01_Req_Data "OnChange";
BA_ "GenSigSwitchedByIgnition" SG_ 2549875574 FoD_MO_01_Req_Data "No";
BA_ "GenSigSendType" SG_ 2550006646 FoD_MO_01_Resp_Data "OnChange";
BA_ "GenSigSwitchedByIgnition" SG_ 2550006646 FoD_MO_01_Resp_Data "No";
BA_ "GenSigSendType" SG_ 987 BCM_01_alt "Cyclic";
BA_ "GenSigStartValue" SG_ 987 BCM_01_alt 1;
BA_ "GenSigFuncType" SG_ 987 BCM_01_alt "DatedBit";
BA_ "GenSigSwitchedByIgnition" SG_ 987 BCM_01_alt "No";
BA_ "GenSigSendType" SG_ 987 SMLS_01_alt "Cyclic";
BA_ "GenSigStartValue" SG_ 987 SMLS_01_alt 1;
BA_ "GenSigFuncType" SG_ 987 SMLS_01_alt "DatedBit";
BA_ "GenSigSwitchedByIgnition" SG_ 987 SMLS_01_alt "No";
BA_ "GenSigSendType" SG_ 987 ZV_02_alt "Cyclic";
BA_ "GenSigStartValue" SG_ 987 ZV_02_alt 1;
BA_ "GenSigFuncType" SG_ 987 ZV_02_alt "DatedBit";
BA_ "GenSigSendType" SG_ 987 Wischer_01_alt "Cyclic";
BA_ "GenSigStartValue" SG_ 987 Wischer_01_alt 1;
BA_ "GenSigFuncType" SG_ 987 Wischer_01_alt "DatedBit";
BA_ "GenSigSwitchedByIgnition" SG_ 987 Wischer_01_alt "No";
BA_ "GenSigSendType" SG_ 987 Anhaenger_01_alt "Cyclic";
BA_ "GenSigStartValue" SG_ 987 Anhaenger_01_alt 1;
BA_ "GenSigFuncType" SG_ 987 Anhaenger_01_alt "DatedBit";
BA_ "GenSigSwitchedByIgnition" SG_ 987 Anhaenger_01_alt "No";
BA_ "GenSigSendType" SG_ 987 Klima_Sensor_02_alt "Cyclic";
BA_ "GenSigStartValue" SG_ 987 Klima_Sensor_02_alt 1;
BA_ "GenSigFuncType" SG_ 987 Klima_Sensor_02_alt "DatedBit";
BA_ "GenSigSwitchedByIgnition" SG_ 987 Klima_Sensor_02_alt "No";
BA_ "GenSigSendType" SG_ 987 Verdeck_01_alt "Cyclic";
BA_ "GenSigStartValue" SG_ 987 Verdeck_01_alt 1;
BA_ "GenSigFuncType" SG_ 987 Verdeck_01_alt "DatedBit";
BA_ "GenSigSendType" SG_ 987 Klima_11_alt "Cyclic";
BA_ "GenSigStartValue" SG_ 987 Klima_11_alt 1;
BA_ "GenSigFuncType" SG_ 987 Klima_11_alt "DatedBit";
BA_ "GenSigSendType" SG_ 987 WFS_01_alt "Cyclic";
BA_ "GenSigStartValue" SG_ 987 WFS_01_alt 1;
BA_ "GenSigFuncType" SG_ 987 WFS_01_alt "DatedBit";
BA_ "GenSigSwitchedByIgnition" SG_ 987 WFS_01_alt "No";
BA_ "GenSigSendType" SG_ 987 Licht_Anf_01_alt "Cyclic";
BA_ "GenSigStartValue" SG_ 987 Licht_Anf_01_alt 1;
BA_ "GenSigFuncType" SG_ 987 Licht_Anf_01_alt "DatedBit";
BA_ "GenSigSendType" SG_ 987 ZV_verriegelt_extern_soll "Cyclic";
BA_ "GenSigSendType" SG_ 987 BH_Lichthupe "OnChange";
BA_ "GenSigSwitchedByIgnition" SG_ 987 BH_Lichthupe "No";
BA_ "GenSigSendType" SG_ 987 WFS_Klemmenfreigabe "Cyclic";
BA_ "GenSigSendType" SG_ 987 ZV_Tankklappe_offen "Cyclic";
BA_ "GenSigSendType" SG_ 987 AAG_Anhaenger_abgesteckt "Cyclic";
BA_ "GenSigSwitchedByIgnition" SG_ 987 AAG_Anhaenger_abgesteckt "No";
BA_ "GenSigSendType" SG_ 987 BCM1_LDS_Stellung "OnChange";
BA_ "Fehlerwert" SG_ 987 BCM1_LDS_Stellung 7;
BA_ "GenSigSendType" SG_ 987 VS_Verdeck_Anf "Cyclic";
BA_ "GenSigSendType" SG_ 987 VS_VD_entriegelt "Cyclic";
BA_ "GenSigSendType" SG_ 987 ZV_HFS_offen "OnChange";
BA_ "GenSigSendType" SG_ 987 ZV_HBFS_offen "OnChange";
BA_ "GenSigSendType" SG_ 987 VS_VD_offen_ver "Cyclic";
BA_ "GenSigSendType" SG_ 987 VS_VD_zu_ver "Cyclic";
BA_ "GenSigSendType" SG_ 987 ZV_BT_offen "OnChange";
BA_ "GenSigSendType" SG_ 987 BCM1_Rueckfahrlicht_Schalter "OnChange";
BA_ "GenSigSwitchedByIgnition" SG_ 987 BCM1_Rueckfahrlicht_Schalter "No";
BA_ "GenSigSendType" SG_ 987 ZV_FT_offen "OnChange";
BA_ "GenSigSendType" SG_ 987 Wischer_vorne_aktiv "OnChange";
BA_ "GenSigSwitchedByIgnition" SG_ 987 Wischer_vorne_aktiv "No";
BA_ "GenSigSendType" SG_ 987 AAG_Anhaenger_erkannt "Cyclic";
BA_ "NWM-WakeupAllowed" SG_ 987 AAG_Anhaenger_erkannt "Yes";
BA_ "GenSigSwitchedByIgnition" SG_ 987 AAG_Anhaenger_erkannt "No";
BA_ "GenSigSendType" SG_ 987 BCM1_MH_Schalter "OnChange";
BA_ "GenSigSwitchedByIgnition" SG_ 987 BCM1_MH_Schalter "No";
BA_ "GenSigSendType" SG_ 987 ZV_HD_offen "OnChange";
BA_ "GenSigSendType" SG_ 987 Waschen_vorne_aktiv "OnChange";
BA_ "GenSigSwitchedByIgnition" SG_ 987 Waschen_vorne_aktiv "No";
BA_ "GenSigSendType" SG_ 987 KL_Thermomanagement "Cyclic";
BA_ "GenSigSendType" SG_ 987 WFS_Schluessel_Fahrberecht "Cyclic";
BA_ "GenSigSendType" SG_ 987 BCM_Rueckfahrlicht_Anf "Cyclic";
BA_ "GenSigSendType" SG_ 987 WWSs_01_alt "OnChange";
BA_ "GenSigStartValue" SG_ 987 WWSs_01_alt 1;
BA_ "GenSigFuncType" SG_ 987 WWSs_01_alt "DatedBit";
BA_ "GenSigSwitchedByIgnition" SG_ 987 WWSs_01_alt "No";
BA_ "GenSigSendType" SG_ 987 BCM_Tankklappensteller_Fehler "Cyclic";
BA_ "Fehlerwert" SG_ 987 BCM_Tankklappensteller_Fehler 1;
BA_ "GenSigSendType" SG_ 987 AAG_LED_aktiv "Cyclic";
BA_ "GenSigSwitchedByIgnition" SG_ 987 AAG_LED_aktiv "No";
BA_ "GenSigSendType" SG_ 987 ZV_verriegelt_soll "OnChange";
BA_ "GenSigSendType" SG_ 987 ZV_Schluessel_Zugang "Cyclic";
BA_ "GenSigSendType" SG_ 987 WFS_ID_Geb_autorisiert_in_Kl15 "Cyclic";
BA_ "GenSigSendType" SG_ 987 BH_Fernlicht "OnChange";
BA_ "GenSigSwitchedByIgnition" SG_ 987 BH_Fernlicht "No";
BA_ "GenSigSendType" SG_ 987 BH_Blinker_li "OnChange";
BA_ "GenSigSwitchedByIgnition" SG_ 987 BH_Blinker_li "No";
BA_ "GenSigSendType" SG_ 987 BH_Blinker_re "OnChange";
BA_ "GenSigSwitchedByIgnition" SG_ 987 BH_Blinker_re "No";
BA_ "GenSigSendType" SG_ 987 BCM1_OBD_FStatus_ATemp "Cyclic";
BA_ "GenSigSwitchedByIgnition" SG_ 987 BCM1_OBD_FStatus_ATemp "No";
BA_ "GenSigSendType" SG_ 987 BCM1_Aussen_Temp_ungef "Cyclic";
BA_ "GenSigStartValue" SG_ 987 BCM1_Aussen_Temp_ungef 254;
BA_ "GenSigSwitchedByIgnition" SG_ 987 BCM1_Aussen_Temp_ungef "No";
BA_ "Fehlerwert" SG_ 987 BCM1_Aussen_Temp_ungef 255;
BA_ "GenSigSendType" SG_ 173 Getriebe_11_CRC "Cyclic";
BA_ "GenSigFuncType" SG_ 173 Getriebe_11_CRC "CRC-8";
BA_ "GenSigSwitchedByIgnition" SG_ 173 Getriebe_11_CRC "No";
BA_ "GenSigSendType" SG_ 173 Getriebe_11_BZ "Cyclic";
BA_ "GenSigFuncType" SG_ 173 Getriebe_11_BZ "MsgCounter";
BA_ "GenSigSwitchedByIgnition" SG_ 173 Getriebe_11_BZ "No";
BA_ "GenSigSendType" SG_ 173 GE_MMom_Soll_02 "Cyclic";
BA_ "GenSigStartValue" SG_ 173 GE_MMom_Soll_02 1022;
BA_ "GenSigSwitchedByIgnition" SG_ 173 GE_MMom_Soll_02 "No";
BA_ "Fehlerwert" SG_ 173 GE_MMom_Soll_02 1023;
BA_ "GenSigSendType" SG_ 173 GE_MMom_Vorhalt_02 "Cyclic";
BA_ "GenSigStartValue" SG_ 173 GE_MMom_Vorhalt_02 1022;
BA_ "GenSigSwitchedByIgnition" SG_ 173 GE_MMom_Vorhalt_02 "No";
BA_ "Fehlerwert" SG_ 173 GE_MMom_Vorhalt_02 1023;
BA_ "GenSigSendType" SG_ 173 GE_Uefkt "Cyclic";
BA_ "GenSigSwitchedByIgnition" SG_ 173 GE_Uefkt "No";
BA_ "Fehlerwert" SG_ 173 GE_Uefkt 1023;
BA_ "GenSigSendType" SG_ 173 GE_Fahrstufe "Cyclic";
BA_ "GenSigStartValue" SG_ 173 GE_Fahrstufe 1;
BA_ "GenSigSwitchedByIgnition" SG_ 173 GE_Fahrstufe "No";
BA_ "Fehlerwert" SG_ 173 GE_Fahrstufe 15;
BA_ "GenSigSendType" SG_ 173 GE_Schaltablauf "Cyclic";
BA_ "GenSigSwitchedByIgnition" SG_ 173 GE_Schaltablauf "No";
BA_ "GenSigSendType" SG_ 173 GE_Uefkt_unplausibel "Cyclic";
BA_ "GenSigSwitchedByIgnition" SG_ 173 GE_Uefkt_unplausibel "No";
BA_ "GenSigSendType" SG_ 173 GE_MMom_Status_02 "Cyclic";
BA_ "GenSigSwitchedByIgnition" SG_ 173 GE_MMom_Status_02 "No";
BA_ "GenSigSendType" SG_ 173 GE_Status_Kraftschluss "Cyclic";
BA_ "GenSigSwitchedByIgnition" SG_ 173 GE_Status_Kraftschluss "No";
BA_ "GenSigSendType" SG_ 173 GE_MMom_Status "Cyclic";
BA_ "GenSigSwitchedByIgnition" SG_ 173 GE_MMom_Status "No";
BA_ "GenSigSendType" SG_ 173 GE_Freig_MMom_Vorhalt "Cyclic";
BA_ "GenSigSwitchedByIgnition" SG_ 173 GE_Freig_MMom_Vorhalt "No";
BA_ "GenSigSendType" SG_ 173 GE_Verbot_Ausblendung "Cyclic";
BA_ "GenSigSwitchedByIgnition" SG_ 173 GE_Verbot_Ausblendung "No";
BA_ "GenSigSendType" SG_ 173 GE_Zielgang "Cyclic";
BA_ "GenSigSwitchedByIgnition" SG_ 173 GE_Zielgang "No";
BA_ "Fehlerwert" SG_ 173 GE_Zielgang 15;
BA_ "GenSigSendType" SG_ 324 Getriebe_16_CRC "Cyclic";
BA_ "GenSigFuncType" SG_ 324 Getriebe_16_CRC "CRC-8";
BA_ "GenSigSwitchedByIgnition" SG_ 324 Getriebe_16_CRC "No";
BA_ "GenSigSendType" SG_ 324 Getriebe_16_BZ "Cyclic";
BA_ "GenSigFuncType" SG_ 324 Getriebe_16_BZ "MsgCounter";
BA_ "GenSigSwitchedByIgnition" SG_ 324 Getriebe_16_BZ "No";
BA_ "GenSigSendType" SG_ 324 GE_Ausleuchtung_Fahrstufe "Cyclic";
BA_ "GenSigSwitchedByIgnition" SG_ 324 GE_Ausleuchtung_Fahrstufe "No";
BA_ "Fehlerwert" SG_ 324 GE_Ausleuchtung_Fahrstufe 15;
BA_ "GenSigSendType" SG_ 324 GE_Testparameter_1 "Cyclic";
BA_ "GenSigSwitchedByIgnition" SG_ 324 GE_Testparameter_1 "No";
BA_ "GenSigSendType" SG_ 324 GE_Testparameter_2 "Cyclic";
BA_ "GenSigSwitchedByIgnition" SG_ 324 GE_Testparameter_2 "No";
BA_ "GenSigSendType" SG_ 324 GE_Test_Freigabe "Cyclic";
BA_ "GenSigSwitchedByIgnition" SG_ 324 GE_Test_Freigabe "No";
BA_ "GenSigSendType" SG_ 324 GE_N_Haltephase "Cyclic";
BA_ "GenSigSwitchedByIgnition" SG_ 324 GE_N_Haltephase "No";
BA_ "GenSigSendType" SG_ 324 GE_WH_Abschalten "Cyclic";
BA_ "GenSigSwitchedByIgnition" SG_ 324 GE_WH_Abschalten "No";
BA_ "GenSigSendType" SG_ 324 GE_Soll_Haltemagnet "Cyclic";
BA_ "GenSigSwitchedByIgnition" SG_ 324 GE_Soll_Haltemagnet "No";
BA_ "GenSigSendType" SG_ 324 GE_WH_Shiftlock "Cyclic";
BA_ "GenSigStartValue" SG_ 324 GE_WH_Shiftlock 1;
BA_ "GenSigSwitchedByIgnition" SG_ 324 GE_WH_Shiftlock "No";
BA_ "GenSigSendType" SG_ 324 GE_WH_Mute "Cyclic";
BA_ "GenSigSwitchedByIgnition" SG_ 324 GE_WH_Mute "No";
BA_ "GenSigSendType" SG_ 324 GE_Ausleuchtung_blinkend "Cyclic";
BA_ "GenSigSwitchedByIgnition" SG_ 324 GE_Ausleuchtung_blinkend "No";
BA_ "GenSigSendType" SG_ 299 GRA_ACC_01_CRC "Cyclic";
BA_ "GenSigFuncType" SG_ 299 GRA_ACC_01_CRC "CRC-8";
BA_ "GenSigSendType" SG_ 299 GRA_ACC_01_BZ "Cyclic";
BA_ "GenSigFuncType" SG_ 299 GRA_ACC_01_BZ "MsgCounter";
BA_ "GenSigSendType" SG_ 299 GRA_Hauptschalter "Cyclic";
BA_ "GenSigSendType" SG_ 299 GRA_Abbrechen "Cyclic";
BA_ "GenSigSendType" SG_ 299 GRA_Typ_Hauptschalter "Cyclic";
BA_ "GenSigSendType" SG_ 299 GRA_Limiter "Cyclic";
BA_ "GenSigSendType" SG_ 299 GRA_Tip_Setzen "Cyclic";
BA_ "GenSigSendType" SG_ 299 GRA_Tip_Hoch "Cyclic";
BA_ "GenSigSendType" SG_ 299 GRA_Tip_Runter "Cyclic";
BA_ "GenSigSendType" SG_ 299 GRA_Tip_Wiederaufnahme "Cyclic";
BA_ "GenSigSendType" SG_ 299 GRA_Verstellung_Zeitluecke "Cyclic";
BA_ "GenSigSendType" SG_ 299 GRA_Codierung "Cyclic";
BA_ "GenSigSendType" SG_ 299 GRA_Fehler "Cyclic";
BA_ "Fehlerwert" SG_ 299 GRA_Fehler 1;
BA_ "GenSigSendType" SG_ 299 GRA_LIM_Taste_verfuegbar "Cyclic";
BA_ "GenSigFuncType" SG_ 299 GRA_LIM_Taste_verfuegbar "Constant";
BA_ "GenSigSendType" SG_ 299 GRA_Tip_Stufe_2 "Cyclic";
BA_ "GenSigSendType" SG_ 299 GRA_Typ_Bedienteil "Cyclic";
BA_ "GenSigSendType" SG_ 299 GRA_TravelAssist "Cyclic";
BA_ "GenSigSwitchedByIgnition" SG_ 299 GRA_TravelAssist "No";
BA_ "GenSigSendType" SG_ 299 GRA_reserveByte4 "Cyclic";
BA_ "GenSigSendType" SG_ 299 GRA_reserveByte5 "Cyclic";
BA_ "GenSigSendType" SG_ 299 GRA_reserveByte6 "Cyclic";
BA_ "GenSigSendType" SG_ 299 GRA_reserveByte7 "Cyclic";
BA_ "GenSigSendType" SG_ 299 GRA_reserveByte8 "Cyclic";
BA_ "GenSigSendType" SG_ 1452 HVEM_IstStrom_HVVerbraucher "Cyclic";
BA_ "GenSigStartValue" SG_ 1452 HVEM_IstStrom_HVVerbraucher 4094;
BA_ "GenSigSwitchedByIgnition" SG_ 1452 HVEM_IstStrom_HVVerbraucher "No";
BA_ "Fehlerwert" SG_ 1452 HVEM_IstStrom_HVVerbraucher 4095;
BA_ "GenSigSendType" SG_ 1452 HVEM_Energie_Klima_Vorgabe_HighR "Cyclic";
BA_ "GenSigStartValue" SG_ 1452 HVEM_Energie_Klima_Vorgabe_HighR 6;
BA_ "GenSigSwitchedByIgnition" SG_ 1452 HVEM_Energie_Klima_Vorgabe_HighR "No";
BA_ "Fehlerwert" SG_ 1452 HVEM_Energie_Klima_Vorgabe_HighR 7;
BA_ "GenSigSendType" SG_ 1452 HVEM_IstLeistungNA "Cyclic";
BA_ "GenSigStartValue" SG_ 1452 HVEM_IstLeistungNA 510;
BA_ "GenSigSwitchedByIgnition" SG_ 1452 HVEM_IstLeistungNA "No";
BA_ "Fehlerwert" SG_ 1452 HVEM_IstLeistungNA 511;
BA_ "GenSigSendType" SG_ 1452 HVEM_Leistung_Klima_Vorgabe "Cyclic";
BA_ "GenSigStartValue" SG_ 1452 HVEM_Leistung_Klima_Vorgabe 254;
BA_ "GenSigSwitchedByIgnition" SG_ 1452 HVEM_Leistung_Klima_Vorgabe "No";
BA_ "Fehlerwert" SG_ 1452 HVEM_Leistung_Klima_Vorgabe 255;
BA_ "GenSigSendType" SG_ 1452 HVEM_Nutzbare_Energie "Cyclic";
BA_ "GenSigStartValue" SG_ 1452 HVEM_Nutzbare_Energie 2046;
BA_ "GenSigSwitchedByIgnition" SG_ 1452 HVEM_Nutzbare_Energie "No";
BA_ "Fehlerwert" SG_ 1452 HVEM_Nutzbare_Energie 2047;
BA_ "GenSigSendType" SG_ 1452 HVEM_Energie_Klima_Vorgabe "Cyclic";
BA_ "GenSigStartValue" SG_ 1452 HVEM_Energie_Klima_Vorgabe 254;
BA_ "GenSigSwitchedByIgnition" SG_ 1452 HVEM_Energie_Klima_Vorgabe "No";
BA_ "Fehlerwert" SG_ 1452 HVEM_Energie_Klima_Vorgabe 255;
BA_ "GenSigSendType" SG_ 1452 HVEM_HVK_Aktivitaet "Cyclic";
BA_ "GenSigStartValue" SG_ 1452 HVEM_HVK_Aktivitaet 2;
BA_ "GenSigSwitchedByIgnition" SG_ 1452 HVEM_HVK_Aktivitaet "No";
BA_ "GenSigSendType" SG_ 1452 HVEM_Pruefpuls_Anf "Cyclic";
BA_ "GenSigStartValue" SG_ 1452 HVEM_Pruefpuls_Anf 3;
BA_ "GenSigSwitchedByIgnition" SG_ 1452 HVEM_Pruefpuls_Anf "No";
BA_ "GenSigSendType" SG_ 1452 HVEM_HV_Anf "Cyclic";
BA_ "GenSigSwitchedByIgnition" SG_ 1452 HVEM_HV_Anf "No";
BA_ "GenSigSendType" SG_ 1452 HVEM_MO_MaxLeistungIgnoriert "Cyclic";
BA_ "GenSigSwitchedByIgnition" SG_ 1452 HVEM_MO_MaxLeistungIgnoriert "No";
BA_ "GenSigSendType" SG_ 1385 HVEM_NVLeistungEmpf "OnChange";
BA_ "GenSigSwitchedByIgnition" SG_ 1385 HVEM_NVLeistungEmpf "No";
BA_ "GenSigSendType" SG_ 1385 HVEM_DCDC_Freigabe "Cyclic";
BA_ "GenSigSwitchedByIgnition" SG_ 1385 HVEM_DCDC_Freigabe "No";
BA_ "GenSigSendType" SG_ 1385 HVEM_KlimaMaxHVStrom "OnChange";
BA_ "GenSigSwitchedByIgnition" SG_ 1385 HVEM_KlimaMaxHVStrom "No";
BA_ "GenSigSendType" SG_ 1385 HVEM_Ladesteckerentr_Anf "OnChange";
BA_ "GenSigSwitchedByIgnition" SG_ 1385 HVEM_Ladesteckerentr_Anf "No";
BA_ "GenSigSendType" SG_ 1385 HVEM_LeistungsAnf "OnChange";
BA_ "GenSigSwitchedByIgnition" SG_ 1385 HVEM_LeistungsAnf "No";
BA_ "GenSigSendType" SG_ 1385 HVEM_Nachlad_Status "OnChange";
BA_ "GenSigStartValue" SG_ 1385 HVEM_Nachlad_Status 3;
BA_ "GenSigSwitchedByIgnition" SG_ 1385 HVEM_Nachlad_Status "No";
BA_ "GenSigSendType" SG_ 1385 HVEM_Abschaltstatus "OnChange";
BA_ "GenSigStartValue" SG_ 1385 HVEM_Abschaltstatus 7;
BA_ "GenSigSwitchedByIgnition" SG_ 1385 HVEM_Abschaltstatus "No";
BA_ "GenSigSendType" SG_ 1385 HVEM_Anf_ReichweiteNV "OnChange";
BA_ "GenSigSwitchedByIgnition" SG_ 1385 HVEM_Anf_ReichweiteNV "No";
BA_ "Fehlerwert" SG_ 1385 HVEM_Anf_ReichweiteNV 3;
BA_ "GenSigSendType" SG_ 1385 HVEM_LadeklappenVerr_Anf "OnChange";
BA_ "GenSigSwitchedByIgnition" SG_ 1385 HVEM_LadeklappenVerr_Anf "No";
BA_ "GenSigSendType" SG_ 1385 HVEM_Max_VK_Betriebsdauer "Cyclic";
BA_ "GenSigStartValue" SG_ 1385 HVEM_Max_VK_Betriebsdauer 62;
BA_ "GenSigSwitchedByIgnition" SG_ 1385 HVEM_Max_VK_Betriebsdauer "No";
BA_ "Fehlerwert" SG_ 1385 HVEM_Max_VK_Betriebsdauer 63;
BA_ "GenSigSendType" SG_ 1385 HVEM_HV_Anf "OnChange";
BA_ "GenSigSwitchedByIgnition" SG_ 1385 HVEM_HV_Anf "No";
BA_ "GenSigSendType" SG_ 1385 HVEM_Text_1 "OnChange";
BA_ "GenSigSwitchedByIgnition" SG_ 1385 HVEM_Text_1 "No";
BA_ "GenSigSendType" SG_ 1385 HVEM_Nachladen_Anf "OnChange";
BA_ "GenSigSwitchedByIgnition" SG_ 1385 HVEM_Nachladen_Anf "No";
BA_ "GenSigSendType" SG_ 1385 HVEM_FreigabeKlimatisierung "OnChange";
BA_ "GenSigStartValue" SG_ 1385 HVEM_FreigabeKlimatisierung 2;
BA_ "GenSigSwitchedByIgnition" SG_ 1385 HVEM_FreigabeKlimatisierung "No";
BA_ "Fehlerwert" SG_ 1385 HVEM_FreigabeKlimatisierung 3;
BA_ "GenSigSendType" SG_ 1385 HVEM_Leistung_Bat_Kond_Vorgabe "Cyclic";
BA_ "GenSigStartValue" SG_ 1385 HVEM_Leistung_Bat_Kond_Vorgabe 254;
BA_ "GenSigSwitchedByIgnition" SG_ 1385 HVEM_Leistung_Bat_Kond_Vorgabe "No";
BA_ "GenSigSendType" SG_ 1283 HVK_01_CRC "Cyclic";
BA_ "GenSigFuncType" SG_ 1283 HVK_01_CRC "CRC-8";
BA_ "GenSigSwitchedByIgnition" SG_ 1283 HVK_01_CRC "No";
BA_ "GenSigSendType" SG_ 1283 HVK_01_BZ "Cyclic";
BA_ "GenSigFuncType" SG_ 1283 HVK_01_BZ "MsgCounter";
BA_ "GenSigSwitchedByIgnition" SG_ 1283 HVK_01_BZ "No";
BA_ "GenSigSendType" SG_ 1283 HVK_Istmodus_Anf "OnChange";
BA_ "GenSigSwitchedByIgnition" SG_ 1283 HVK_Istmodus_Anf "No";
BA_ "GenSigSendType" SG_ 1283 HVK_TN1_Sollmodus "OnChange";
BA_ "GenSigStartValue" SG_ 1283 HVK_TN1_Sollmodus 3;
BA_ "GenSigSwitchedByIgnition" SG_ 1283 HVK_TN1_Sollmodus "No";
BA_ "GenSigSendType" SG_ 1283 HVK_Vorladung_aktiv "OnChange";
BA_ "GenSigSwitchedByIgnition" SG_ 1283 HVK_Vorladung_aktiv "No";
BA_ "GenSigSendType" SG_ 1283 HVK_BMS_Sollmodus "OnChange";
BA_ "GenSigStartValue" SG_ 1283 HVK_BMS_Sollmodus 7;
BA_ "GenSigSwitchedByIgnition" SG_ 1283 HVK_BMS_Sollmodus "No";
BA_ "GenSigSendType" SG_ 1283 HVK_DCDC_Sollmodus "OnChange";
BA_ "GenSigStartValue" SG_ 1283 HVK_DCDC_Sollmodus 7;
BA_ "GenSigSwitchedByIgnition" SG_ 1283 HVK_DCDC_Sollmodus "No";
BA_ "GenSigSendType" SG_ 1283 HVK_EKK_Sollmodus "OnChange";
BA_ "GenSigStartValue" SG_ 1283 HVK_EKK_Sollmodus 7;
BA_ "GenSigSwitchedByIgnition" SG_ 1283 HVK_EKK_Sollmodus "No";
BA_ "GenSigSendType" SG_ 1283 HVK_HVPTC_Sollmodus "OnChange";
BA_ "GenSigStartValue" SG_ 1283 HVK_HVPTC_Sollmodus 7;
BA_ "GenSigSwitchedByIgnition" SG_ 1283 HVK_HVPTC_Sollmodus "No";
BA_ "GenSigSendType" SG_ 1283 HVK_HVLM_Sollmodus "OnChange";
BA_ "GenSigStartValue" SG_ 1283 HVK_HVLM_Sollmodus 7;
BA_ "GenSigSwitchedByIgnition" SG_ 1283 HVK_HVLM_Sollmodus "No";
BA_ "GenSigSendType" SG_ 1283 HVK_HV_Netz_Warnungen "OnChange";
BA_ "GenSigSwitchedByIgnition" SG_ 1283 HVK_HV_Netz_Warnungen "No";
BA_ "GenSigSendType" SG_ 1283 HV_Bordnetz_aktiv "OnChange";
BA_ "GenSigSwitchedByIgnition" SG_ 1283 HV_Bordnetz_aktiv "No";
BA_ "GenSigSendType" SG_ 1283 HV_Bordnetz_Fehler "OnChange";
BA_ "GenSigSwitchedByIgnition" SG_ 1283 HV_Bordnetz_Fehler "No";
BA_ "Fehlerwert" SG_ 1283 HV_Bordnetz_Fehler 1;
BA_ "GenSigSendType" SG_ 1283 HVK_Gesamtst_Spgfreiheit "Cyclic";
BA_ "GenSigSwitchedByIgnition" SG_ 1283 HVK_Gesamtst_Spgfreiheit "No";
BA_ "Fehlerwert" SG_ 1283 HVK_Gesamtst_Spgfreiheit 3;
BA_ "GenSigSendType" SG_ 1283 HVK_AktiveEntladung_Anf "OnChange";
BA_ "GenSigSwitchedByIgnition" SG_ 1283 HVK_AktiveEntladung_Anf "No";
BA_ "GenSigSendType" SG_ 1283 HVK_HVEM_Freigabe "OnChange";
BA_ "GenSigStartValue" SG_ 1283 HVK_HVEM_Freigabe 2;
BA_ "GenSigSwitchedByIgnition" SG_ 1283 HVK_HVEM_Freigabe "No";
BA_ "GenSigSendType" SG_ 1283 HVK_Notentladung_Anf "OnChange";
BA_ "GenSigSwitchedByIgnition" SG_ 1283 HVK_Notentladung_Anf "No";
BA_ "GenSigSendType" SG_ 1283 HVK_Iso_Messung_Start "Cyclic";
BA_ "GenSigSwitchedByIgnition" SG_ 1283 HVK_Iso_Messung_Start "No";
BA_ "GenSigSendType" SG_ 1283 HVK_Ladebereit "OnChange";
BA_ "GenSigSwitchedByIgnition" SG_ 1283 HVK_Ladebereit "No";
BA_ "GenSigSendType" SG_ 1283 HVK_PPulsFreigabe "Cyclic";
BA_ "GenSigStartValue" SG_ 1283 HVK_PPulsFreigabe 3;
BA_ "GenSigSwitchedByIgnition" SG_ 1283 HVK_PPulsFreigabe "No";
BA_ "GenSigSendType" SG_ 2463978813 HVL_01_CRC "Cyclic";
BA_ "GenSigFuncType" SG_ 2463978813 HVL_01_CRC "CRC-8";
BA_ "GenSigSwitchedByIgnition" SG_ 2463978813 HVL_01_CRC "No";
BA_ "GenSigSendType" SG_ 2463978813 HVL_01_BZ "Cyclic";
BA_ "GenSigFuncType" SG_ 2463978813 HVL_01_BZ "MsgCounter";
BA_ "GenSigSwitchedByIgnition" SG_ 2463978813 HVL_01_BZ "No";
BA_ "GenSigSendType" SG_ 2463978813 HVL_Steckerstatus "Cyclic";
BA_ "GenSigSwitchedByIgnition" SG_ 2463978813 HVL_Steckerstatus "No";
BA_ "Fehlerwert" SG_ 2463978813 HVL_Steckerstatus 3;
BA_ "GenSigSendType" SG_ 2463978813 HVL_LadeAnforderung "OnChange";
BA_ "GenSigSwitchedByIgnition" SG_ 2463978813 HVL_LadeAnforderung "No";
BA_ "Fehlerwert" SG_ 2463978813 HVL_LadeAnforderung 7;
BA_ "GenSigSendType" SG_ 626 HVLM_Anforderung_HMS "Cyclic";
BA_ "GenSigSwitchedByIgnition" SG_ 626 HVLM_Anforderung_HMS "No";
BA_ "GenSigSendType" SG_ 626 HVLM_Parken_beibehalten_HMS "Cyclic";
BA_ "GenSigStartValue" SG_ 626 HVLM_Parken_beibehalten_HMS 2;
BA_ "GenSigSwitchedByIgnition" SG_ 626 HVLM_Parken_beibehalten_HMS "No";
BA_ "Fehlerwert" SG_ 626 HVLM_Parken_beibehalten_HMS 3;
BA_ "GenSigSendType" SG_ 626 HVLM_WakeUpZaehlerResetAnf "Cyclic";
BA_ "GenSigSwitchedByIgnition" SG_ 626 HVLM_WakeUpZaehlerResetAnf "No";
BA_ "GenSigSendType" SG_ 626 HVLM_AWC_VerbautStatus "Cyclic";
BA_ "GenSigSwitchedByIgnition" SG_ 626 HVLM_AWC_VerbautStatus "No";
BA_ "Fehlerwert" SG_ 626 HVLM_AWC_VerbautStatus 3;
BA_ "GenSigSendType" SG_ 626 HVLM_Steckerstatus_A "OnChange";
BA_ "GenSigSwitchedByIgnition" SG_ 626 HVLM_Steckerstatus_A "No";
BA_ "Fehlerwert" SG_ 626 HVLM_Steckerstatus_A 7;
BA_ "GenSigSendType" SG_ 626 HVLM_Steckerstatus_B "OnChange";
BA_ "GenSigSwitchedByIgnition" SG_ 626 HVLM_Steckerstatus_B "No";
BA_ "Fehlerwert" SG_ 626 HVLM_Steckerstatus_B 7;
BA_ "GenSigSendType" SG_ 626 HVLM_Start_Pulserkennung "Cyclic";
BA_ "GenSigSwitchedByIgnition" SG_ 626 HVLM_Start_Pulserkennung "No";
BA_ "GenSigSendType" SG_ 626 HVLM_ZustandLadeablauf "Cyclic";
BA_ "GenSigSwitchedByIgnition" SG_ 626 HVLM_ZustandLadeablauf "No";
BA_ "GenSigSendType" SG_ 626 HVLM_DC_Aufstartmodus "Cyclic";
BA_ "GenSigSwitchedByIgnition" SG_ 626 HVLM_DC_Aufstartmodus "No";
BA_ "GenSigSendType" SG_ 626 HVLM_Ladeszenario "OnChange";
BA_ "GenSigStartValue" SG_ 626 HVLM_Ladeszenario 30;
BA_ "GenSigSwitchedByIgnition" SG_ 626 HVLM_Ladeszenario "No";
BA_ "Fehlerwert" SG_ 626 HVLM_Ladeszenario 31;
BA_ "GenSigSendType" SG_ 626 HVLM_Ladevorgang_Anf "Cyclic";
BA_ "GenSigSwitchedByIgnition" SG_ 626 HVLM_Ladevorgang_Anf "No";
BA_ "GenSigSendType" SG_ 626 HVLM_Intensitaet "OnChange";
BA_ "GenSigStartValue" SG_ 626 HVLM_Intensitaet 126;
BA_ "GenSigSwitchedByIgnition" SG_ 626 HVLM_Intensitaet "No";
BA_ "Fehlerwert" SG_ 626 HVLM_Intensitaet 127;
BA_ "GenSigSendType" SG_ 626 HVLM_Laden_ISO_Messung_Anf "Cyclic";
BA_ "GenSigStartValue" SG_ 626 HVLM_Laden_ISO_Messung_Anf 1;
BA_ "GenSigSwitchedByIgnition" SG_ 626 HVLM_Laden_ISO_Messung_Anf "No";
BA_ "GenSigSendType" SG_ 268 ImoCord_Auth_Aufforderung_WFS "OnChange";
BA_ "GenSigSwitchedByIgnition" SG_ 268 ImoCord_Auth_Aufforderung_WFS "No";
BA_ "GenSigSwitchedByIgnition" SG_ 23 WFS_IMMO_MSG3_CRC "No";
BA_ "GenSigSendType" SG_ 23 WFS_IMMO_MSG3_Status "OnWrite";
BA_ "GenSigSwitchedByIgnition" SG_ 23 WFS_IMMO_MSG3_Status "No";
BA_ "GenSigSwitchedByIgnition" SG_ 25 WFS_IMMO_MSG4_CRC "No";
BA_ "GenSigSendType" SG_ 25 WFS_IMMO_MSG4_Status "OnWrite";
BA_ "GenSigSwitchedByIgnition" SG_ 25 WFS_IMMO_MSG4_Status "No";
VAL_ 252 ESC_aktBr_Modus 0 "Aktivbremsung_Aus" 1 "Aktivbremsung_Volumenkompensation" 2 "Aktivbremsung_Aktiv" 3 "Aktivbremsung_Runout";
VAL_ 252 ESC_Blending_Solldruck 1022 "Init" 1023 "Fehler";
VAL_ 252 ESC_EBKV_Kraftblending_Modus 0 "Inactive" 1 "Hold" 2 "Active";
VAL_ 252 ESC_Bremsdruck_Modell 1022 "Init" 1023 "Fehler";
VAL_ 252 ESC_Bremsdruck_02 1023 "Fehler";
VAL_ 252 ESC_QBit_Bremsdruck_02 0 "gueltiger_Wert" 1 "Ersatz_Init_oder_Fehlerwert";
VAL_ 252 ESP_HL_Radgeschw_02 65533 "Unterspannung" 65534 "Init" 65535 "Fehler";
VAL_ 252 ESP_HR_Radgeschw_02 65533 "Unterspannung" 65534 "Init" 65535 "Fehler";
VAL_ 252 ESP_VL_Radgeschw_02 65533 "Unterspannung" 65534 "Init" 65535 "Fehler";
VAL_ 252 ESP_VR_Radgeschw_02 65533 "Unterspannung" 65534 "Init" 65535 "Fehler";
VAL_ 252 ESP_FZR_uebersteuern 254 "Init" 255 "Fehler";
VAL_ 252 ESP_FZR_untersteuern 254 "Init" 255 "Fehler";
VAL_ 252 ESC_Anf_Mindestreku 0 "nicht_angefordert" 1 "angefordert";
VAL_ 252 ESC_GMV_aktiv 0 "keine_Aktivitaet" 1 "Aktivitaet_durch_AWA";
VAL_ 252 ESC_GMV_nicht_verfuegbar 0 "verfuegbar" 1 "nicht_verfuegbar";
VAL_ 252 ESC_Status_vRef_Stuetzeingriff 0 "kein_Eingriff" 1 "Stuetzungseingriff";
VAL_ 252 FDR_Allradverteilung_aktiv 0 "kein_Eingriff" 1 "Allradeingriff_aktiv";
VAL_ 252 FDR_Anf_Allradbetrieb 0 "keine_Anforderung" 1 "Kraftschluss_an_beiden_Achsen_herstellen";
VAL_ 252 ESP_HL_Bremsmoment 254 "Init" 255 "Fehler";
VAL_ 252 ESP_HR_Bremsmoment 254 "Init" 255 "Fehler";
VAL_ 252 ESP_VR_Bremsmoment 254 "Init" 255 "Fehler";
VAL_ 252 ESP_VL_Bremsmoment 254 "Init" 255 "Fehler";
VAL_ 252 ESP_FDR_uebersteuern 254 "Init" 255 "Fehler";
VAL_ 252 ESP_FDR_untersteuern 254 "Init" 255 "Fehler";
VAL_ 252 TSMomBegrenzung 4094 "Init" 4095 "Fehler";
VAL_ 252 ESC_Allrad_Anteil_max_sek 510 "Init" 511 "Fehler";
VAL_ 252 ESC_Allrad_Anteil_min_sek 510 "Init" 511 "Fehler";
VAL_ 252 ESC_Status_Eingriff 0 "kein Eingriff" 1 "ASR-Eingriff" 2 "MSR-Eingriff" 3 "nicht belegt ";
VAL_ 252 ESC_Status_Eingriff_sek 0 "kein Eingriff" 1 "ASR-Eingriff" 2 "MSR-Eingriff" 3 "nicht belegt ";
VAL_ 252 ESC_MomRad_Eingriff 8190 "Init" 8191 "Fehler";
VAL_ 252 ESC_MomRad_Eingriff_sek 8190 "Init" 8191 "Fehler";
VAL_ 252 ESC_Achsdrehzahl_Max 16382 "Init" 16383 "Fehler";
VAL_ 252 ESC_Achsdrehzahl_Min 16382 "Init" 16383 "Fehler";
VAL_ 252 ESC_Achsdrehzahl_Max_sek 16382 "Init" 16383 "Fehler";
VAL_ 252 ESC_Achsdrehzahl_Min_sek 16382 "Init" 16383 "Fehler";
VAL_ 2463978647 ESP_ACC_LDE 0 "Lebensdauerende_nicht_erreicht" 1 "Lebensdauerende_erreicht";
VAL_ 2463978647 ESP_Allrad_Antrieb 0 "Front" 1 "Allrad";
VAL_ 2463978647 ESP_Codierung_ADS 0 "Init" 1 "ESP_nicht_ADS_codiert" 2 "ADS_codiert" 3 "tbd";
VAL_ 2463978647 ESP_RTA_HL 254 "Abgleich_nocht_nicht_genuegend_konvergent" 255 "Fehler";
VAL_ 2463978647 ESP_RTA_HR 254 "Abgleich_nocht_nicht_genuegend_konvergent" 255 "Fehler";
VAL_ 2463978647 ESP_RTA_VR 254 "Abgleich_nocht_nicht_genuegend_konvergent" 255 "Fehler";
VAL_ 2463978647 OBD_Fehler_Radsensor_HL 0 "kein Fehler / Init / nicht verbaut" 1 "KS- (Kurzschluss nach minus)" 2 "KS+ (Kurzschluss nach plus)" 3 "OC (Leitungsunterbrechung)" 4 "OOR+ (Signal zu gross)" 5 "OOR- (Signal zu klein)" 6 "RC+ (Signal unplausibel zu gross)" 7 "RC- (Signal unplausibel zu klein)" 8 "KS+/OC (Kurzschluss nach plus/Unterbrechung)" 9 "KS-/OC  (Kurzschluss nach minus/Unterbrechung)" 10 "KS-/KS+  (Kurzschluss nach minus/plus)" 11 "KS-/KS+/OC (Kurzschluss nach minus/plus/Unterbrechung)" 12 "frei" 13 "frei" 14 "frei" 15 "frei";
VAL_ 2463978647 OBD_Fehler_Radsensor_HR 0 "kein Fehler / Init / nicht verbaut" 1 "KS- (Kurzschluss nach minus)" 2 "KS+ (Kurzschluss nach plus)" 3 "OC (Leitungsunterbrechung)" 4 "OOR+ (Signal zu gross)" 5 "OOR- (Signal zu klein)" 6 "RC+ (Signal unplausibel zu gross)" 7 "RC- (Signal unplausibel zu klein)" 8 "KS+/OC (Kurzschluss nach plus/Unterbrechung)" 9 "KS-/OC  (Kurzschluss nach minus/Unterbrechung)" 10 "KS-/KS+  (Kurzschluss nach minus/plus)" 11 "KS-/KS+/OC (Kurzschluss nach minus/plus/Unterbrechung)" 12 "frei" 13 "frei" 14 "frei" 15 "frei";
VAL_ 2463978647 OBD_Fehler_Radsensor_VL 0 "kein Fehler / Init / nicht verbaut" 1 "KS- (Kurzschluss nach minus)" 2 "KS+ (Kurzschluss nach plus)" 3 "OC (Leitungsunterbrechung)" 4 "OOR+ (Signal zu gross)" 5 "OOR- (Signal zu klein)" 6 "RC+ (Signal unplausibel zu gross)" 7 "RC- (Signal unplausibel zu klein)" 8 "KS+/OC (Kurzschluss nach plus/Unterbrechung)" 9 "KS-/OC  (Kurzschluss nach minus/Unterbrechung)" 10 "KS-/KS+  (Kurzschluss nach minus/plus)" 11 "KS-/KS+/OC (Kurzschluss nach minus/plus/Unterbrechung)" 12 "frei" 13 "frei" 14 "frei" 15 "frei";
VAL_ 2463978647 OBD_Fehler_Radsensor_VR 0 "kein Fehler / Init / nicht verbaut" 1 "KS- (Kurzschluss nach minus)" 2 "KS+ (Kurzschluss nach plus)" 3 "OC (Leitungsunterbrechung)" 4 "OOR+ (Signal zu gross)" 5 "OOR- (Signal zu klein)" 6 "RC+ (Signal unplausibel zu gross)" 7 "RC- (Signal unplausibel zu klein)" 8 "KS+/OC (Kurzschluss nach plus/Unterbrechung)" 9 "KS-/OC  (Kurzschluss nach minus/Unterbrechung)" 10 "KS-/KS+  (Kurzschluss nach minus/plus)" 11 "KS-/KS+/OC (Kurzschluss nach minus/plus/Unterbrechung)" 12 "frei" 13 "frei" 14 "frei" 15 "frei";
VAL_ 2463978647 ESP_Qualifizierung_Antriebsart 0 "alte_Bedeutung_Bit_ESP_Allrad_Antrieb" 1 "neue_Bedeutung_Bit_ESP_Allrad_Antrieb";
VAL_ 2463978647 ESP_Offroad_Modus 0 "kein_ESP_Offroadmodus" 1 "ESP_Offroadmodus";
VAL_ 2463978647 ESP_MKB_ausloesbar 0 "Multikollisionsbremsung_nicht_freigeschaltet" 1 "Multikollisionsbremsung_freigeschaltet";
VAL_ 2463978647 ESP_Stat_FallBack_eBKV 0 "Rueckfallebene_nicht_vorhanden" 1 "Rueckfallebene_vorhanden";
VAL_ 2463978647 ESP_CM_Variante 0 "Standard" 1 "Erweitert";
VAL_ 2463978647 ESP_OBD_Status 0 "MIL_aus" 1 "MIL_ein";
VAL_ 2463978647 ESP_Rollenmodus_Deaktivieren 0 "keine_Aenderung" 1 "Abbruch";
VAL_ 2463978647 ESP_nachtr_Stopp_Anf 0 "nicht_angefordert" 1 "angefordert";
VAL_ 2527679683 ESC_ASM_Ereignis 0 "No_Event" 255 "ASM_Trigger";
VAL_ 2527679683 ESC_ASM_Zeitstempel 255 "Init";
VAL_ 278 ESP_QBit_Wegimpuls_VL 0 "gueltiger_Wert" 1 "Ersatz_Init_oder_Fehlerwert";
VAL_ 278 ESP_QBit_Wegimpuls_VR 0 "gueltiger_Wert" 1 "Ersatz_Init_oder_Fehlerwert";
VAL_ 278 ESP_QBit_Wegimpuls_HL 0 "gueltiger_Wert" 1 "Ersatz_Init_oder_Fehlerwert";
VAL_ 278 ESP_QBit_Wegimpuls_HR 0 "gueltiger_Wert" 1 "Ersatz_Init_oder_Fehlerwert";
VAL_ 278 ESP_Wegimpuls_VL 1021 "Init" 1022 "Unterspannung" 1023 "Fehler";
VAL_ 278 ESP_Wegimpuls_VR 1021 "Init" 1022 "Unterspannung" 1023 "Fehler";
VAL_ 278 ESP_Wegimpuls_HL 1021 "Init" 1022 "Unterspannung" 1023 "Fehler";
VAL_ 278 ESP_Wegimpuls_HR 1021 "Init" 1022 "Unterspannung" 1023 "Fehler";
VAL_ 278 ESP_VL_Fahrtrichtung 0 "Vorwaerts" 1 "Rueckwaerts" 2 "Init" 3 "ungueltig_oder_nicht_verbaut";
VAL_ 278 ESP_VR_Fahrtrichtung 0 "Vorwaerts" 1 "Rueckwaerts" 2 "Init" 3 "ungueltig_oder_nicht_verbaut";
VAL_ 278 ESP_HL_Fahrtrichtung 0 "Vorwaerts" 1 "Rueckwaerts" 2 "Init" 3 "ungueltig_oder_nicht_verbaut";
VAL_ 278 ESP_HR_Fahrtrichtung 0 "Vorwaerts" 1 "Rueckwaerts" 2 "Init" 3 "ungueltig_oder_nicht_verbaut";
VAL_ 1629 BR_Systemart 0 "ABS" 1 "ABS_ASR" 2 "ESP" 3 "ESP_mit_integrierter_EPB";
VAL_ 1629 ESP_SpannungsAnf_02 0 "keine_Anforderung" 1 "Anforderung_Stufe1" 2 "Anforderung_Stufe2" 3 "Anforderung_Stufe3";
VAL_ 1629 ESP_Charisma_FahrPr 0 "keine_Funktion" 1 "Programm_1" 2 "Programm_2" 3 "Programm_3" 4 "Programm_4" 5 "Programm_5" 6 "Programm_6" 7 "Programm_7" 8 "Programm_8" 9 "Programm_9" 10 "Programm_10" 11 "Programm_11" 12 "Programm_12" 13 "Programm_13" 14 "Programm_14" 15 "Programm_15";
VAL_ 1629 ESP_Charisma_Status 0 "Init" 1 "verfuegbar" 2 "nicht_verfuegbar" 3 "asynchron_durch_Fahrerwunsch";
VAL_ 1629 ESP_Wiederstart_Anz_01 0 "keine_Anzeige" 1 "Rueckwaertsrollen";
VAL_ 1629 ESP_Wiederstart_Anz_02 0 "keine_Anzeige" 1 "Autohold_Rutschen";
VAL_ 1629 ESP_Wiederstart_Anz_03 0 "keine_Anzeige" 1 "Offroad_HDC";
VAL_ 1629 ESP_Wiederstart_Anz_04 0 "keine_Anzeige" 1 "ESC_Off";
VAL_ 1629 ESP_Stoppverbot_Anz_01 0 "keine_Anzeige" 1 "Notbremsung_aktiv";
VAL_ 1629 ESP_Stoppverbot_Anz_02 0 "keine_Anzeige" 1 "Autohold_AVH_Rutschen";
VAL_ 1629 ESP_Stoppverbot_Anz_03 0 "keine_Anzeige" 1 "Rueckwaertsrollen";
VAL_ 1629 ESP_Stoppverbot_Anz_04 0 "keine_Anzeige" 1 "ESP_Pumpenlauf";
VAL_ 1629 ESP_Stoppverbot_Anz_05 0 "keine_Anzeige" 1 "ESP_OFF";
VAL_ 1629 ESP_Stoppverbot_Anz_06 0 "keine_Anzeige" 1 "Offroad_HDC";
VAL_ 1629 ESP_Stoppverbot_Anz_07 0 "keine_Anzeige" 1 "ESP_Haltefunktion_nicht_verfuegbar";
VAL_ 1629 ESP_Stoppverbot_Anz_Std 0 "keine_Anzeige" 1 "Standard_Stoppvetogrund";
VAL_ 1629 ESP_Dachrelingsensor 0 "Sensor_nicht_verbaut" 1 "Quertraeger_montiert" 2 "Quertraeger_nicht_montiert" 3 "Fehler";
VAL_ 1629 ESP_Stoppverbot_Anz_08 0 "keine_Anzeige" 1 "Neigungsbegrenzung";
VAL_ 1629 HDC_Charisma_FahrPr 0 "keine_Funktion" 1 "Programm_1" 2 "Programm_2" 3 "Programm_3" 4 "Programm_4" 5 "Programm_5" 6 "Programm_6" 7 "Programm_7" 8 "Programm_8" 9 "Programm_9" 10 "Programm_10" 11 "Programm_11" 12 "Programm_12" 13 "Programm_13" 14 "Programm_14" 15 "Programm_15";
VAL_ 1629 HDC_Charisma_Status 0 "Init" 1 "verfuegbar" 2 "nicht_verfuegbar" 3 "asynchron_durch_Fahrerwunsch";
VAL_ 1629 BR_QBit_Reifenumfang 0 "gueltiger_Wert" 1 "Ersatz_Init_oder_Fehlerwert";
VAL_ 253 BR_Eingriffsmoment 1022 "Init" 1023 "Fehler";
VAL_ 253 ESP_PLA_Bremseingriff 0 "inaktiv" 1 "aktiv";
VAL_ 253 ESP_Diagnose 0 "ESP_nicht_in_Diagnose" 1 "ESP_in_Diagnose";
VAL_ 253 ESC_Reku_Freigabe 0 "keine_Freigabe_der_Rekuperation" 1 "Freigabe_der_Rekuperation";
VAL_ 253 ESC_v_Signal_Qualifier_High_Low 0 "Gueteschwelle_kleiner_1kmh" 1 "Gueteschwelle_kleiner_3kmh" 2 "Gueteschwelle_kleiner_5kmh" 3 "Gueteschwelle_kleiner_10kmh" 4 "Gueteschwelle_kleiner_20kmh" 5 "Gueteschwelle_groessergleich_20kmh" 6 "Init" 7 "Fehler";
VAL_ 253 ESP_Vorsteuerung 0 "keine_Vorsteuerung_aktiv" 1 "Vorsteuerung_aktiv";
VAL_ 253 ESP_AWV3_Brems_aktiv 0 "inaktiv" 1 "aktiv";
VAL_ 253 OBD_Schlechtweg 0 "kein_Schlechtweg_erkannt" 1 "Schlechtweg_erkannt";
VAL_ 253 OBD_QBit_Schlechtweg 0 "gueltiger_Wert" 1 "Ersatz_Init_oder_Fehlerwert";
VAL_ 253 ESP_v_Signal 65533 "Unterspannung" 65534 "Init" 65535 "Fehler";
VAL_ 253 ASR_Tastung_passiv 0 "ASR_aktiviert" 1 "ASR_passiv_getastet_oder_Schwellen_geaendert";
VAL_ 253 ESP_Tastung_passiv 0 "ESP_aktiviert" 1 "ESP_passiv_getastet_oder_Schwellen_geaendert";
VAL_ 253 ESP_Systemstatus 0 "iO" 1 "Fehler";
VAL_ 253 ASR_Schalteingriff 0 "keine_Anforderung" 1 "ASR_Schaltkennfeld" 2 "Rueckschaltung" 3 "Schaltverbot";
VAL_ 253 ESP_Haltebestaetigung 0 "kein_sicheres_Halten" 1 "sicheres_Halten";
VAL_ 253 ESP_MKB_Abbruch_Geschw 0 "MKB_nicht_beendet_wg_v_Schwelle" 1 "MKB_beendet_wg_v_Schwelle";
VAL_ 253 ESP_QBit_v_Signal 0 "gueltiger_Wert" 1 "Ersatz_Init_oder_Fehlerwert";
VAL_ 253 ABS_Bremsung 0 "keine_ABS_Regelung" 1 "ABS_Regelung_aktiv";
VAL_ 253 ASR_Anf 0 "keine_Anforderung" 1 "ASR_Anforderung";
VAL_ 253 MSR_Anf 0 "keine Anfoderung" 1 "MSR-Anforderung";
VAL_ 253 EBV_Eingriff 0 "kein_EBV_Eingriff" 1 "EBV_Eingriff";
VAL_ 253 EDS_Eingriff 0 "kein_EDS_Eingriff" 1 "EDS_Eingriff";
VAL_ 253 ESP_Eingriff 0 "kein_ESP_Eingriff" 1 "ESP_Eingriff_aktiv";
VAL_ 253 ESP_ASP 0 "inaktiv" 1 "aktiv";
VAL_ 253 ESP_Anhaltevorgang_ACC_aktiv 0 "inaktiv" 1 "aktiv";
VAL_ 795 ESP_Lampe 0 "Aus" 1 "Ein";
VAL_ 795 ABS_Lampe 0 "Aus" 1 "Ein";
VAL_ 795 BK_Lampe_02 0 "aus" 1 "ein_statisch" 3 "Warnung";
VAL_ 795 TC_Lampe 0 "Aus" 1 "Ein";
VAL_ 795 ESP_m_Raddrehz 32765 "Unterspannung" 32766 "Init" 32767 "Fehler";
VAL_ 795 ESP_Textanzeigen_03 0 "kein_Text" 1 "ESP_Stoerung" 2 "ABS_Stoerung" 3 "ESP_ABS_Stoerung" 4 "Werkstatt_Bremse" 5 "ASR_Stoerung" 6 "ESP_switched_off" 7 "ASR_off" 8 "ESP_ASR_on" 10 "keine_Bremskraftverstaerkung" 11 "ASR_aktiviert" 12 "ABS_ASR_Stoerung" 15 "ESP_offroad" 17 "ESP_sport" 18 "ESP_Zwangsaktivierung" 19 "ESP_Taster_Info" 20 "TC_aktiv" 21 "reserviert_fuer_Verlwarn" 22 "TC_switched_off" 23 "Verlwarn_akt_Rollsicher_inakt" 24 "ESP_SuperSport" 25 "ESP_Offroad_nicht_verfuegbar";
VAL_ 795 ESP_Meldungen 0 "keine_Anzeige" 1 "Autohold_Hinweis_1" 2 "Stoerung_Autohold" 3 "Stoerung_Hillholder" 4 "Uebernehmen" 5 "Autohold_aus" 6 "Autohold_Hinweis_2";
VAL_ 795 ESP_Fehlerstatus_Wegimp 0 "Wegimpulse_iO" 1 "Fehler";
VAL_ 795 ESP_Wegimp_Ueberlauf 0 "Reset_und_kein_Ueberlauf" 1 "mindestens_1x_Ueberlauf";
VAL_ 795 ESP_QBit_Wegimp_VA 0 "gueltiger_Wert" 1 "Ersatz_Init_oder_Fehlerwert";
VAL_ 795 ESP_HDC_FktLampe 0 "Aus" 1 "Ein";
VAL_ 795 ESP_Off_Lampe 0 "Lampe_aus" 1 "Lampe_ein";
VAL_ 795 ESP_HDC_Regelgeschw 0 "nicht_verbaut" 125 "HDC_Standby" 126 "Init" 127 "Fehler";
VAL_ 795 ESP_BKV_Warnung 0 "keine_Anzeige" 1 "keine_Bremskraftverstaerkung";
VAL_ 2589283617 EDS_Charisma_FahrPr 0 "keine_Funktion" 1 "Programm_1" 2 "Programm_2" 3 "Programm_3" 4 "Programm_4" 5 "Programm_5" 6 "Programm_6" 7 "Programm_7" 8 "Programm_8" 9 "Programm_9" 10 "Programm_10" 11 "Programm_11" 12 "Programm_12" 13 "Programm_13" 14 "Programm_14" 15 "Programm_15";
VAL_ 2589283617 EDS_Charisma_Status 0 "Init" 1 "verfuegbar" 2 "nicht_verfuegbar" 3 "asynchron_durch_Fahrerwunsch";
VAL_ 2589283617 HHC_Charisma_Status 0 "Init" 1 "verfuegbar" 2 "nicht_verfuegbar" 3 "asynchron_durch_Fahrerwunsch";
VAL_ 2589283617 HHC_Charisma_FahrPr 0 "keine_Funktion" 1 "Programm_1" 2 "Programm_2" 3 "Programm_3" 4 "Programm_4" 5 "Programm_5" 6 "Programm_6" 7 "Programm_7" 8 "Programm_8" 9 "Programm_9" 10 "Programm_10" 11 "Programm_11" 12 "Programm_12" 13 "Programm_13" 14 "Programm_14" 15 "Programm_15";
VAL_ 2589283617 RLE_Anzeigen 0 "keine_Anzeige" 1 "Rad_lose_allgemein" 2 "Rad_VL_lose" 3 "Rad_VR_lose" 4 "Rad_HL_lose" 5 "Rad_HR_lose" 6 "RLE_Pruefphase" 7 "RLE_Systemstoerung";
VAL_ 2589283617 ESC_Lernfreigabe_Abrollumfang 0 "keine_Lernfreigabe" 1 "Lernfreigabe";
VAL_ 2589283617 ESC_Texte_eBKV_Betaetigung 0 "keine_Anzeige" 1 "Halten_ueber_Schaltwippen_aktiv" 2 "Beide_Schaltwippen_betaetigen" 3 "Abbr_Halten_ueber_Schaltwippen" 4 "Bremspedal_betaetigen" 5 "Fahrpedal_loesen_Bremse_treten";
VAL_ 2589283617 ESC_MBK_Meldungen 0 "kein_Text" 1 "MBK_Hinweis_aktiv" 2 "MBK_Eskalation1_aktiv";
VAL_ 2589283617 ESC_Anf_KV 0 "kein_Oeffnen" 1 "Oeffnen";
VAL_ 2589283617 ESC_FBA_Meldungen 0 "kein_Text" 1 "FBA_Warnung_aktiv_MT" 2 "FBA_Warnung_aktiv_AT";
VAL_ 2589283617 DBK_Fahrerwarnung 0 "kein_Anfordern" 1 "Warnung_Aufforderung_Anhalten" 2 "Warnung_Aufforderung_Werkstatt" 3 "nicht_belegt";
VAL_ 2527679668 eTM_Ventil1_Status 0 "Ventil_nicht_angesteuert" 1 "Ventil_angesteuert" 5 "Ventil_nicht_verbaut" 6 "Init" 7 "Fehler";
VAL_ 2527679668 eTM_Ventil2_Status 0 "Ventil_nicht_angesteuert" 1 "Ventil_angesteuert" 5 "Ventil_nicht_verbaut" 6 "Init" 7 "Fehler";
VAL_ 2527679668 eTM_Ventil3_Status 0 "Ventil_nicht_angesteuert" 1 "Ventil_angesteuert" 5 "Ventil_nicht_verbaut" 6 "Init" 7 "Fehler";
VAL_ 2527679668 eTM_Pumpe3_Status 14 "Init" 15 "Fehler";
VAL_ 2527679668 eTM_BMS_Pumpe1_SollAnsteuerung 14 "Init" 15 "Fehler";
VAL_ 2527679668 eTM_Pumpe2_Volumenstrom 62 "Init" 63 "Fehler";
VAL_ 2527679668 eTM_BMS_Ventil2_Befuellung 0 "false" 1 "true";
VAL_ 2527679668 eTM_Pumpe1_Volumenstrom 62 "Init" 63 "Fehler";
VAL_ 2527679668 eTM_BMS_Pumpe1_Befuellung 0 "false" 1 "true";
VAL_ 2527679668 eTM_BMS_Ventil1_Befuellung 0 "false" 1 "true";
VAL_ 2527679668 eTM_Pumpe1_Status 14 "Init" 15 "Fehler";
VAL_ 2527679668 eTM_Pumpe2_Status 14 "Init" 15 "Fehler";
VAL_ 2527679668 eTM_Temperatur_1 254 "Init" 255 "Fehler";
VAL_ 2527679668 eTM_Temperatur_2 254 "Init" 255 "Fehler";
VAL_ 2527679740 KBI_aktive_Laengsfunktion_02 0 "Init" 1 "Speedlimiter" 2 "GRA_oder_ACC" 3 "PACCh" 4 "HDC" 5 "p_GRA" 6 "p_Lim" 7 "ACC_im_GRA_Modus";
VAL_ 2527679740 KBI_Anzeigestatus_GRA 0 "nicht_vorhanden" 1 "Anzeigemoeglichkeit_vorhanden" 2 "reserviert" 3 "Fehler";
VAL_ 2527679740 KBI_Anzeigestatus_LIM 0 "nicht_vorhanden" 1 "Anzeigemoeglichkeit_vorhanden" 2 "reserviert" 3 "Fehler";
VAL_ 2527679740 KBI_Anzeigestatus_ACC 0 "keine_ACC_Anzeige" 1 "ACC_Anzeige_aktiv";
VAL_ 2527679740 KBI_Konsistenz_ACC 0 "ACC Botschaft konsistent" 1 "ACC Botschaft inkonsistent";
VAL_ 2527679740 KBI_Fehler_Anzeige_ACC 0 " iO" 1 "Anzeigefehler ACC";
VAL_ 2589283684 GRA_FoD_Status 0 "Init" 1 "Funktion_inaktiv" 2 "Funktion_aktiv";
VAL_ 2589283684 FoD_Transmission_Info 0 "Initwert" 1 "start_transmission" 2 "finish_transmission";
VAL_ 987 BCM_01_alt 0 "aktuell" 1 "veraltet";
VAL_ 987 SMLS_01_alt 0 "aktuell" 1 "veraltet";
VAL_ 987 ZV_02_alt 0 "aktuell" 1 "veraltet";
VAL_ 987 Wischer_01_alt 0 "aktuell" 1 "veraltet";
VAL_ 987 Anhaenger_01_alt 0 "aktuell" 1 "veraltet";
VAL_ 987 Klima_Sensor_02_alt 0 "aktuell" 1 "veraltet";
VAL_ 987 Verdeck_01_alt 0 "aktuell" 1 "veraltet";
VAL_ 987 Klima_11_alt 0 "aktuell" 1 "veraltet";
VAL_ 987 WFS_01_alt 0 "aktuell" 1 "veraltet";
VAL_ 987 Licht_Anf_01_alt 0 "aktuell" 1 "veraltet";
VAL_ 987 ZV_verriegelt_extern_soll 1 "Fahrzeug verriegelt extern; Sollzusstand";
VAL_ 987 BH_Lichthupe 0 "nicht_betaetigt" 1 "Blinkerhebel in Richtung Lichthupe betaetigt";
VAL_ 987 WFS_Klemmenfreigabe 0 "keine_Freigabe" 1 "Freigabe";
VAL_ 987 ZV_Tankklappe_offen 0 "Tankklappe_geschlossen" 1 "Tankklappe_offen";
VAL_ 987 AAG_Anhaenger_abgesteckt 1 "Anhaenger_wurde_bei_KL15_aus_abgesteckt";
VAL_ 987 BCM1_LDS_Stellung 0 "Init" 1 "Stellung_0" 2 "Auto" 3 "Standlicht" 4 "Abblendlicht" 7 "Fehler";
VAL_ 987 VS_VD_entriegelt 1 "Zustand des Verdeck entriegelt";
VAL_ 987 ZV_HFS_offen 0 "geschlossen" 1 "offen";
VAL_ 987 ZV_HBFS_offen 0 "geschlossen" 1 "offen";
VAL_ 987 VS_VD_offen_ver 0 "Init" 1 "Verdeck_verriegelt_und_offen";
VAL_ 987 VS_VD_zu_ver 1 "Zustand des Verdecks verriegelt und geschlossen";
VAL_ 987 ZV_BT_offen 1 "BT_geoeffnet";
VAL_ 987 BCM1_Rueckfahrlicht_Schalter 0 "nicht_betaetigt" 1 "betaetigt";
VAL_ 987 ZV_FT_offen 1 "FT_geoeffnet";
VAL_ 987 Wischer_vorne_aktiv 1 "Wischer vorne läuft";
VAL_ 987 AAG_Anhaenger_erkannt 0 "kein_Anhaenger_erkannt" 1 "AAG_Anhaenger_erkannt";
VAL_ 987 BCM1_MH_Schalter 0 "MH_geschlossen" 1 "MH_offen";
VAL_ 987 ZV_HD_offen 1 "Heckdeckel_auf";
VAL_ 987 Waschen_vorne_aktiv 1 "Waschen aktiv";
VAL_ 987 KL_Thermomanagement 0 "keine_Freigabe_TMM__max_Heizbedarf" 1 "kleine_Freigabe_TMM" 2 "mittlere_Freigabe_TMM" 3 "volle_Freigabe_TMM__kein_Heizbedarf";
VAL_ 987 WFS_Schluessel_Fahrberecht 0 "kein authorisierter Schluessel erkannt" 1 "aktive_Funkschluessel_Nr_01" 2 "aktive_Funkschluessel_Nr_02" 3 "aktive_Funkschluessel_Nr_03" 4 "aktive_Funkschluessel_Nr_04" 5 "aktive_Funkschluessel_Nr_05" 6 "aktive_Funkschluessel_Nr_06" 7 "aktive_Funkschluessel_Nr_07" 8 "aktive_Funkschluessel_Nr_08" 9 "ungueltig_09" 10 "ungueltig_10" 11 "ungueltig_11" 12 "ungueltig_12" 13 "ungueltig_13" 14 "ungueltig_14" 15 "digitaler_Schluessel_aktiv";
VAL_ 987 BCM_Rueckfahrlicht_Anf 0 "Licht_nicht_angefordert" 1 "Licht_angefordert";
VAL_ 987 WWSs_01_alt 0 "aktuell" 1 "veraltet";
VAL_ 987 BCM_Tankklappensteller_Fehler 0 "kein_Fehler" 1 "Fehler";
VAL_ 987 AAG_LED_aktiv 0 "Lampen" 1 "LED";
VAL_ 987 ZV_verriegelt_soll 0 "Init" 1 "nicht_verriegelt" 2 "verriegelt";
VAL_ 987 ZV_Schluessel_Zugang 0 "kein authorisierter Schluessel erkannt " 1 "aktive_Funkschluessel_Nr_01" 2 "aktive_Funkschluessel_Nr_02" 3 "aktive_Funkschluessel_Nr_03" 4 "aktive_Funkschluessel_Nr_04" 5 "aktive_Funkschluessel_Nr_05" 6 "aktive_Funkschluessel_Nr_06" 7 "aktive_Funkschluessel_Nr_07" 8 "aktive_Funkschluessel_Nr_08" 9 "ungueltig_09" 10 "ungueltig_10" 11 "ungueltig_11" 12 "ungueltig_12" 13 "ungueltig_13" 14 "ungueltig_14" 15 "ungueltig_15";
VAL_ 987 WFS_ID_Geb_autorisiert_in_Kl15 0 "nicht_authorisiert_in_Kl15" 1 "authorisiert_in_Kl15";
VAL_ 987 BH_Fernlicht 0 "nicht_betaetigt" 1 "Blinkerhebel_in_Richtung_Fernlicht_betaetigt";
VAL_ 987 BH_Blinker_li 0 "nicht_betaetigt" 1 "Blinkerhebel_Richtung_links_betaetigt";
VAL_ 987 BH_Blinker_re 0 "nicht_betaetigt" 1 "Blinkerhebel_Richtung_rechts_betaetigt";
VAL_ 987 BCM1_OBD_FStatus_ATemp 0 "kein Fehler / Init / nicht verbaut" 1 "KS- (Kurzschluss nach minus)" 2 "KS+ (Kurzschluss nach plus)" 3 "OC (Leitungsunterbrechung)" 4 "OOR+ (Signal zu gross)" 5 "OOR- (Signal zu klein)" 6 "RC+ (Signal unplausibel zu gross)" 7 "RC- (Signal unplausibel zu klein)" 8 "KS+/OC (Kurzschluss nach plus/Unterbrechung)" 9 "KS-/OC  (Kurzschluss nach minus/Unterbrechung)" 10 "KS-/KS+  (Kurzschluss nach minus/plus)" 11 "KS-/KS+/OC (Kurzschluss nach minus/plus/Unterbrechung)" 12 "frei" 13 "frei" 14 "frei" 15 "frei";
VAL_ 987 BCM1_Aussen_Temp_ungef 253 "nicht_verbaut" 254 "Initwert" 255 "Fehler";
VAL_ 173 GE_MMom_Soll_02 1022 "keine_Anforderung_Init" 1023 "Fehler";
VAL_ 173 GE_MMom_Vorhalt_02 1022 "Init" 1023 "Fehler";
VAL_ 173 GE_Uefkt 1023 "Fehler";
VAL_ 173 GE_Fahrstufe 8 "Position_D" 0 "Zwischenstellung" 9 "Position_S" 1 "Init" 5 "Position_P" 6 "Position_R" 7 "Position_N" 10 "Effizienz" 13 "Tipp_in_S" 14 "Tipp_in_D" 15 "Fehler";
VAL_ 173 GE_Schaltablauf 0 "keine_Schaltung" 1 "Momentenueberschneidung" 2 "Befuellphase" 3 "Drehzahlueberfuehrung";
VAL_ 173 GE_Uefkt_unplausibel 0 "Uefkt_plausibel" 1 "Uefkt_unplausibel";
VAL_ 173 GE_MMom_Status_02 0 "kein_Eingriff" 1 "abs_reduzierender_Eingriff_auf_Gesamt_Antrieb_nur_schneller_Pfad" 2 "abs_erhoehender_Eingriff_auf_Gesamt_Antrieb" 3 "relativer_Eingriff_auf_Gesamt_Antrieb" 4 "relativer_Eingriff_auf_E_Maschine" 5 "abs_red_Eingr_auf_Gesamt_Antrieb_nur_Luftpfad" 6 "abs_red_Eingr_auf_Gesamt_Antrieb_Luft-_und_schnellen_Pfad" 7 "abs_Eingriff_auf_Gesamtantrieb_erhoehend_und_reduzierend";
VAL_ 173 GE_Status_Kraftschluss 0 "offen_kein_Kraftschluss" 1 "offen_mit_Kraftschluss" 2 "schlupfend_geregelt" 3 "abgesichert_offen_kein_Kraftschl" 4 "geschlossen_mit_Mikroschlupf" 5 "geschlossen_mit_Ueberanpressung" 6 "sonstige_Fehler" 7 "fehlerhaft_geschlossen";
VAL_ 173 GE_MMom_Status 0 "keine Anforderung" 1 "reduzierender Getriebeeingriff" 2 "erhöhender Getriebeeingriff" 3 "Änderung mit Sprung";
VAL_ 173 GE_Freig_MMom_Vorhalt 0 "nicht_freigegeben" 1 "freigegeben";
VAL_ 173 GE_Verbot_Ausblendung 0 "kein_Verbot" 1 "Verbot";
VAL_ 173 GE_Zielgang 0 "Gang P/N (ausgekuppelt)" 1 "Gang 1" 2 "Gang 2" 3 "Gang 3" 4 "Gang 4" 5 "Gang 5" 6 "Gang 6" 7 "Gang 7" 8 "Gang R" 11 "Gang 8" 12 "Gang 9" 13 "Gang10" 14 "Istgang nicht definiert" 15 "Fehler";
VAL_ 324 GE_Ausleuchtung_Fahrstufe 8 "P" 0 "Init" 5 "D" 6 "N" 7 "R" 10 "Tipp_Plus" 11 "Tipp_Minus" 12 "S" 13 "Kurz_Manuell_Programm" 14 "Tipp_Gasse" 15 "Fehler";
VAL_ 324 GE_Test_Freigabe 0 "kein Test" 1 "gültige Testparameter";
VAL_ 324 GE_N_Haltephase 0 "nicht_aktiv" 1 "aktiv";
VAL_ 324 GE_WH_Abschalten 0 "Wählhebel-SG ein" 1 "Wählhebel-SH aus";
VAL_ 324 GE_Soll_Haltemagnet 0 "Init_nicht_verwendet" 1 "nicht_halten" 2 "halten" 3 "keine_Vorgabe";
VAL_ 324 GE_WH_Shiftlock 0 "Waehlhebel_sperren" 1 "Waehlhebel_freigeben";
VAL_ 324 GE_WH_Mute 0 "Senden_ein" 1 "Senden_aus";
VAL_ 324 GE_Ausleuchtung_blinkend 0 "kein_Blinken" 1 "Blinken";
VAL_ 299 GRA_Hauptschalter 0 "Hauptschalter_aus__Taster_nicht_betaetigt" 1 "Hauptschalter_ein__Taster_betaetigt";
VAL_ 299 GRA_Abbrechen 0 "nicht_betaetigt" 1 "betaetigt";
VAL_ 299 GRA_Typ_Hauptschalter 0 "gerasteter_Lenkstockschalter" 1 "getasteter_Lenkstockschalter";
VAL_ 299 GRA_Limiter 0 "nicht_betaetigt" 1 "betaetigt";
VAL_ 299 GRA_Tip_Setzen 0 "nicht_betaetigt" 1 "betaetigt";
VAL_ 299 GRA_Tip_Hoch 0 "nicht_betaetigt" 1 "betaetigt";
VAL_ 299 GRA_Tip_Runter 0 "nicht_betaetigt" 1 "betaetigt";
VAL_ 299 GRA_Tip_Wiederaufnahme 0 "nicht_betaetigt" 1 "betaetigt";
VAL_ 299 GRA_Verstellung_Zeitluecke 0 "Taste_nicht_betaetigt" 1 "Dist_minus_1" 2 "Dist_plus_1" 3 "Dist_Toggle";
VAL_ 299 GRA_Codierung 0 "kein_Hebel" 1 "GRA_Hebel" 2 "ACC_Hebel" 3 "Limiter_Only";
VAL_ 299 GRA_Fehler 0 "kein_Fehler" 1 "Fehler";
VAL_ 299 GRA_LIM_Taste_verfuegbar 0 "Limiter_Taste_nicht_vorhanden" 1 "Limiter_Taste_vorhanden";
VAL_ 299 GRA_Tip_Stufe_2 0 "Tip_Stufe_1__keine_Betaetigung" 1 "Tip_Stufe_2";
VAL_ 299 GRA_Typ_Bedienteil 0 "Init" 1 "4_Positions_Bedienteil" 2 "6_Positions_Bedienteil" 3 "8_Positions_Bedienteil" 4 "PAG_5_Positions_Bedienteil" 5 "VW_MFL_Gen2" 6 "VW_MFL_Gen3" 7 "reserviert";
VAL_ 299 GRA_TravelAssist 0 "nicht_betaetigt" 1 "betaetigt";
VAL_ 1452 HVEM_IstStrom_HVVerbraucher 4094 "Init" 4095 "Fehler";
VAL_ 1452 HVEM_Energie_Klima_Vorgabe_HighR 6 "Init" 7 "Fehler";
VAL_ 1452 HVEM_IstLeistungNA 510 "Init" 511 "Fehler";
VAL_ 1452 HVEM_Leistung_Klima_Vorgabe 254 "Init" 255 "Fehler";
VAL_ 1452 HVEM_Nutzbare_Energie 2045 "Max" 2046 "Init" 2047 "Fehler";
VAL_ 1452 HVEM_Energie_Klima_Vorgabe 254 "Init" 255 "Fehler";
VAL_ 1452 HVEM_HVK_Aktivitaet 0 "keine_Aktivitaet" 1 "Aktivitaet" 2 "Init";
VAL_ 1452 HVEM_Pruefpuls_Anf 0 "Keine_Anforderung" 1 "Anforderung" 2 "Reserved" 3 "Init";
VAL_ 1452 HVEM_HV_Anf 0 "keine_Anforderung" 1 "HV_angefordert";
VAL_ 1452 HVEM_MO_MaxLeistungIgnoriert 0 "Max_Leistung_nicht_ignoriert" 1 "Max_Leistung_ignoriert";
VAL_ 1385 HVEM_DCDC_Freigabe 0 "keine_Freigabe" 1 "Freigabe";
VAL_ 1385 HVEM_Ladesteckerentr_Anf 0 "keine_Anforderung" 1 "Anf_Ladestecker_Entr";
VAL_ 1385 HVEM_LeistungsAnf 0 "nicht_angefordert" 1 "angefordert";
VAL_ 1385 HVEM_Nachlad_Status 0 "nicht_moeglich__Fehler" 1 "moeglich__begonnen" 2 "Beendet" 3 "Init";
VAL_ 1385 HVEM_Abschaltstatus 0 "100" 1 "75" 2 "50" 3 "25" 7 "Init";
VAL_ 1385 HVEM_Anf_ReichweiteNV 0 "keine_Massnahme_notwendig" 1 "Reduktion_Stufe_1" 2 "Reduktion_Stufe_2" 3 "Fehler";
VAL_ 1385 HVEM_LadeklappenVerr_Anf 0 "Init" 1 "Ladeklappe_verriegeln" 2 "Ladeklappe_entriegeln";
VAL_ 1385 HVEM_Max_VK_Betriebsdauer 62 "Init" 63 "Fehler";
VAL_ 1385 HVEM_HV_Anf 0 "keine_Anforderung" 1 "HV_angefordert";
VAL_ 1385 HVEM_Text_1 0 "kein_Text" 1 "Text";
VAL_ 1385 HVEM_Nachladen_Anf 0 "keine_Anforderung" 1 "Nachladen_angefordert";
VAL_ 1385 HVEM_FreigabeKlimatisierung 0 "keine_Freigabe" 1 "Freigabe" 2 "Init" 3 "Fehler";
VAL_ 1385 HVEM_Leistung_Bat_Kond_Vorgabe 254 "Init";
VAL_ 1283 HVK_Istmodus_Anf 0 "nicht_angefordert" 1 "angefordert";
VAL_ 1283 HVK_TN1_Sollmodus 0 "HV_Off" 1 "HV_On" 2 "reserviert" 3 "Initialisierung";
VAL_ 1283 HVK_Vorladung_aktiv 0 "Vorladung_nicht_aktiv" 1 "Vorladung_aktiv";
VAL_ 1283 HVK_BMS_Sollmodus 0 "HV_Off" 1 "HV_On" 3 "AC_Laden_erw" 4 "AC_Laden" 6 "DC_Laden" 7 "Init";
VAL_ 1283 HVK_DCDC_Sollmodus 0 "Standby" 1 "HV_On_Vorladen" 2 "Tiefsetzen" 3 "Hochsetzen" 4 "Pruefpuls_12V" 7 "Initialisierung";
VAL_ 1283 HVK_EKK_Sollmodus 0 "Keine_Freigabe" 1 "Freigabe" 2 "Freigabe_ausgesetzt" 7 "Init";
VAL_ 1283 HVK_HVPTC_Sollmodus 0 "Keine_Freigabe" 1 "Freigabe" 2 "Freigabe_ausgesetzt" 7 "Init";
VAL_ 1283 HVK_HVLM_Sollmodus 0 "keine_Freigabe" 1 "Freigabe_Lademanager" 7 "Init";
VAL_ 1283 HVK_HV_Netz_Warnungen 0 "Keine_Warnung" 1 "Warntext_HV_Netz_Anf" 2 "Fehlertext_HV_Netz_Anf" 3 "Warnung_Kein_Wiederstart_moeglich";
VAL_ 1283 HV_Bordnetz_aktiv 0 "inaktiv" 1 "aktiv";
VAL_ 1283 HV_Bordnetz_Fehler 0 "kein_Fehler" 1 "Fehler";
VAL_ 1283 HVK_Gesamtst_Spgfreiheit 0 "Funktion_Init__ohne_Funktion" 1 "HV_System_spannungsfrei" 2 "HV_System_nicht_spannungsfrei" 3 "Fehler";
VAL_ 1283 HVK_AktiveEntladung_Anf 0 "nicht_angefordert" 1 "angefordert";
VAL_ 1283 HVK_HVEM_Freigabe 0 "keine_Freigabe" 1 "Freigabe" 2 "Init";
VAL_ 1283 HVK_Notentladung_Anf 0 "keine_Anforderung_Notentladung" 1 "Anforderung_Notentladung" 2 "Reserve" 3 "INIT_keine_HV_Zuschaltung";
VAL_ 1283 HVK_Iso_Messung_Start 0 "keine_Messung" 1 "Messung_HV_Netz_1" 2 "Messung_HV_Netz_2" 4 "deaktiviert";
VAL_ 1283 HVK_Ladebereit 0 "Init_oder_nicht_Ladebereit" 1 "AC_Ladebereit" 2 "DC_Ladebereit" 3 "AC_und_DC_Ladebereit" 4 "Induktiv_Ladebereit" 5 "AC_und_Induktiv_Ladebereit" 6 "DC_und_Induktiv_Ladebereit" 7 "AC_DC_und_Induktiv_Ladebereit";
VAL_ 1283 HVK_PPulsFreigabe 0 "keine_Freigabe" 1 "Freigabe" 2 "Reserve" 3 "Init";
VAL_ 2463978813 HVL_Steckerstatus 0 "Init" 1 "kein_Stecker_erkannt" 2 "Stecker_erkannt" 3 "Fehler";
VAL_ 2463978813 HVL_LadeAnforderung 0 "Laden_nicht_angefordert" 1 "AC_Laden_Angefordert" 2 "DC_Laden_Angefordert" 3 "AC_und_DC_Angefordert" 4 "Induktiv_Laden_Angef" 5 "AC_und_Induktiv_Angef" 6 "DC_und_Induktiv_Angef" 7 "Fehler";
VAL_ 626 HVLM_Anforderung_HMS 0 "keine_Anforderung" 1 "halten" 2 "parken" 3 "halten_Standby" 4 "anfahren" 5 "Loesen_ueber_Rampe";
VAL_ 626 HVLM_Parken_beibehalten_HMS 0 "Parken_nicht_beibehalten" 1 "Parken_beibehalten" 2 "Init" 3 "Fehler";
VAL_ 626 HVLM_WakeUpZaehlerResetAnf 0 "keine_Anforderung" 1 "Reset_Zaehler";
VAL_ 626 HVLM_AWC_VerbautStatus 0 "Init" 1 "nicht_verbaut" 2 "verbaut" 3 "Fehler";
VAL_ 626 HVLM_Steckerstatus_A 0 "Init" 1 "kein_Stecker_erkannt" 2 "Stecker_steckt_nicht_verriegelt" 3 "Stecker_steckt_und_verriegelt" 7 "Fehler";
VAL_ 626 HVLM_Steckerstatus_B 0 "Init" 1 "kein_Stecker_erkannt" 2 "Stecker_steckt_nicht_verriegelt" 3 "Stecker_steckt_und_verriegelt" 7 "Fehler";
VAL_ 626 HVLM_Start_Pulserkennung 0 "keine_Anforderung" 1 "Pulserkennung_starten";
VAL_ 626 HVLM_ZustandLadeablauf 8 "Erhaltungsladen" 0 "Init" 1 "Stby_Ladevorbed_erfuellt" 2 "Stby_Ladevorbed_nicht_erfuellt" 4 "Laden_starten" 5 "Laden_beenden" 6 "HVBatterie_Laden" 7 "HVBatterie_Entladen";
VAL_ 626 HVLM_DC_Aufstartmodus 0 "keine_Anforderung" 1 "Angleich_Fahrzeug" 2 "Angleich_LS_1" 3 "Angleich_LS_2";
VAL_ 626 HVLM_Ladeszenario 0 "Aus" 1 "Timerladen_abgeschlossen" 2 "Sofortladen_abgeschlossen" 3 "Optimiertes_Laden_abgeschlossen" 4 "Timerladen_aktiv" 5 "Sofortladen_aktiv" 6 "Optimiertes_Laden_aktiv" 7 "Timerladen_warten" 8 "Optimiertes_Laden_warten" 9 "Keine_Netzspannung" 10 "Fehler_Verriegelung" 11 "Fehler_Ladesytem" 12 "Init_Ladekommunikation" 30 "Init" 31 "Fehler";
VAL_ 626 HVLM_Ladevorgang_Anf 0 "Laden_nicht_angefordert" 1 "AC_Laden_Angefordert" 2 "DC_Laden_Angefordert" 3 "AC_und_DC_Angefordert" 4 "Induktiv_Laden_Angef" 5 "AC_und_Induktiv_Angef" 6 "DC_und_Induktiv_Angef" 7 "AC_DC_und_Induktiv_Angef";
VAL_ 626 HVLM_Intensitaet 126 "Init" 127 "Fehler";
VAL_ 626 HVLM_Laden_ISO_Messung_Anf 0 "Anforderung" 1 "keine_Anforderung";
VAL_ 268 ImoCord_Auth_Aufforderung_WFS 0 "nicht_anfordern" 1 "anfordern";
